VERSION "hnnbnnnynnnnnnnnnnnnnnnnnnnnnnnnnnnnnnnnnn/4/%%%/4/'%**4nnn///"

NS_ :

BS_:

BU_: BAP_Tester Fahrerdisplay_Kombi HUD ICAS1_X_Gateway ICAS3_Gateway ICC_IO_Node Kombi SmartLight_01 ZR_MIB_TOP_ab_Gen3

BO_ 851 DiETa_01: 8 ICAS1_X_Gateway
	SG_ DiETa_Car : 16|2@1+ (1,0) [0|3] ""  ICAS3_Gateway
	SG_ DiETa_Defrost_Taste : 36|2@1+ (1,0) [0|3] ""  Vector__XXX
	SG_ DiETa_FAS_Stufe : 30|2@1+ (1,0) [0|3] ""  Vector__XXX
	SG_ DiETa_FSH_Taste : 24|2@1+ (1,0) [0|3] ""  Vector__XXX
	SG_ DiETa_HSH_Taste : 26|2@1+ (1,0) [0|3] ""  Vector__XXX
	SG_ DiETa_Klima : 18|2@1+ (1,0) [0|3] ""  Vector__XXX
	SG_ DiETa_Lock_Unlock_Taste : 40|3@1+ (1,0) [0|7] ""  Vector__XXX
	SG_ DiETa_Mode : 20|2@1+ (1,0) [0|3] ""  Vector__XXX
	SG_ DiETa_Mode2 : 38|2@1+ (1,0) [0|3] ""  Vector__XXX
	SG_ DiETa_Mode_roh : 43|1@1+ (1,0) [0|1] ""  Vector__XXX
	SG_ DiETa_PAO_OFF_Status : 34|2@1+ (1,0) [0|3] ""  Vector__XXX
	SG_ DiETa_PAO_ON_Status : 32|2@1+ (1,0) [0|3] ""  Vector__XXX
	SG_ DiETa_Parken : 22|2@1+ (1,0) [0|3] ""  Vector__XXX
	SG_ DiETa_Reserve_Byte2_4 : 12|1@1+ (1,0) [0|1] ""  Vector__XXX
	SG_ DiETa_Reserve_Byte6_6 : 46|2@1+ (1,0) [0|3] ""  Vector__XXX
	SG_ DiETa_Reserve_Byte7_4 : 52|4@1+ (1,0) [0|15] ""  Vector__XXX
	SG_ DiETa_Reserve_Byte8 : 56|8@1+ (1,0) [0|255] ""  Vector__XXX
	SG_ DiETa_ResponseError : 15|1@1+ (1,0) [0|1] ""  Vector__XXX
	SG_ DiETa_Status : 13|2@1+ (1,0) [0|3] ""  Vector__XXX
	SG_ DiETa_Touch_Event : 48|4@1+ (1,0) [0|15] ""  ICAS3_Gateway
	SG_ DiETa_Warnblink_Taste : 28|2@1+ (1,0) [0|3] ""  Vector__XXX
	SG_ DiETas_01_BZ : 8|4@1+ (1,0) [0|15] ""  Vector__XXX
	SG_ DiETas_01_CRC : 0|8@1+ (1,0) [0|255] ""  Vector__XXX
	SG_ ESP_Off_Taster : 44|2@1+ (1,0) [0|3] ""  Vector__XXX

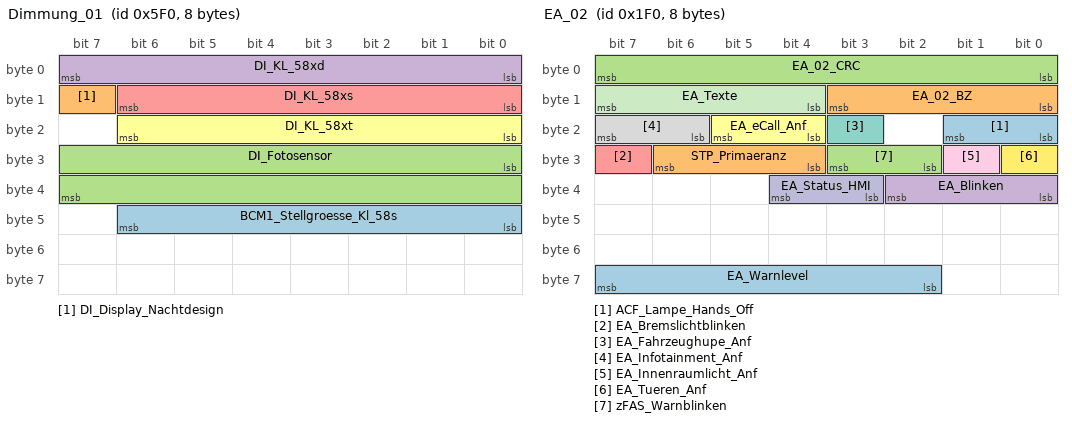
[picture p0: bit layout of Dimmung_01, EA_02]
BO_ 1520 Dimmung_01: 8 ICAS1_X_Gateway
	SG_ BCM1_Stellgroesse_Kl_58s : 40|7@1+ (1,0) [0|100] ""  HUD,ICAS3_Gateway,ICC_IO_Node,ZR_MIB_TOP_ab_Gen3
	SG_ DI_Display_Nachtdesign : 15|1@1+ (1,0) [0|1] ""  Fahrerdisplay_Kombi,HUD,ICAS3_Gateway,ICC_IO_Node,Kombi,ZR_MIB_TOP_ab_Gen3
	SG_ DI_Fotosensor : 24|16@1+ (1,0) [0|65535] ""  ICAS3_Gateway,ICC_IO_Node,ZR_MIB_TOP_ab_Gen3
	SG_ DI_KL_58xd : 0|8@1+ (1,0) [0|253] ""  Fahrerdisplay_Kombi,HUD,ICAS3_Gateway,ICC_IO_Node,Kombi,ZR_MIB_TOP_ab_Gen3
	SG_ DI_KL_58xs : 8|7@1+ (1,0) [0|100] "PerCent"  Fahrerdisplay_Kombi,HUD,ICAS3_Gateway,ICC_IO_Node,Kombi,ZR_MIB_TOP_ab_Gen3
	SG_ DI_KL_58xt : 16|7@1+ (1,0) [0|100] "PerCent"  Fahrerdisplay_Kombi,HUD,ICAS3_Gateway,ICC_IO_Node,Kombi,ZR_MIB_TOP_ab_Gen3

BO_ 2527679674 DispKBI_FS_01: 8 Fahrerdisplay_Kombi
	SG_ DispKBI_FS_Systemstatus : 12|1@1+ (1,0) [0|1] ""  ICAS1_X_Gateway

BO_ 2630879546 DispKBI_FS_DispPos_Req_FD: 64 Fahrerdisplay_Kombi
	SG_ DispKBI_FS_DispPos_Req_FD_Data : 0|512@1+ (1,0) [0|13407807929942597099574024998205846127479365820592393377723561443721764030073546976801874298166903427690031858186486050853753882811946569946433649006084096] ""  ICAS3_Gateway

BO_ 2631010618 DispKBI_FS_DispPos_Resp_FD: 64 ICAS3_Gateway
	SG_ DispKBI_FS_DispPos_Resp_FD_Data : 0|512@1+ (1,0) [0|13407807929942597099574024998205846127479365820592393377723561443721764030073546976801874298166903427690031858186486050853753882811946569946433649006084096] ""  Fahrerdisplay_Kombi

BO_ 2621717001 DispPos_DispKBI_FS_Req_FD: 64 ICAS3_Gateway
	SG_ DispPos_DispKBI_FS_Req_FD_Data : 0|512@1+ (1,0) [0|13407807929942597099574024998205846127479365820592393377723561443721764030073546976801874298166903427690031858186486050853753882811946569946433649006084096] ""  Fahrerdisplay_Kombi

BO_ 2621848073 DispPos_DispKBI_FS_Resp_FD: 64 Fahrerdisplay_Kombi
	SG_ DispPos_DispKBI_FS_Resp_FD_Data : 0|512@1+ (1,0) [0|13407807929942597099574024998205846127479365820592393377723561443721764030073546976801874298166903427690031858186486050853753882811946569946433649006084096] ""  ICAS3_Gateway

BO_ 496 EA_02: 8 ICAS1_X_Gateway
	SG_ ACF_Lampe_Hands_Off : 16|2@1+ (1,0) [0|3] ""  Vector__XXX
	SG_ EA_02_BZ : 8|4@1+ (1,0) [0|15] ""  Vector__XXX
	SG_ EA_02_CRC : 0|8@1+ (1,0) [0|255] ""  Vector__XXX
	SG_ EA_Blinken : 32|3@1+ (1,0) [0|7] ""  Vector__XXX
	SG_ EA_Bremslichtblinken : 31|1@1+ (1,0) [0|1] ""  Vector__XXX
	SG_ EA_eCall_Anf : 20|2@1+ (1,0) [0|3] ""  Kombi
	SG_ EA_Fahrzeughupe_Anf : 19|1@1+ (1,0) [0|1] ""  Vector__XXX
	SG_ EA_Infotainment_Anf : 22|2@1+ (1,0) [0|3] ""  ICAS3_Gateway,ZR_MIB_TOP_ab_Gen3
	SG_ EA_Innenraumlicht_Anf : 25|1@1+ (1,0) [0|1] ""  Vector__XXX
	SG_ EA_Status_HMI : 35|2@1+ (1,0) [0|3] ""  ICAS3_Gateway
	SG_ EA_Texte : 12|4@1+ (1,0) [0|15] ""  Kombi
	SG_ EA_Tueren_Anf : 24|1@1+ (1,0) [0|1] ""  Vector__XXX
	SG_ EA_Warnlevel : 58|6@1+ (1,0) [0|63] ""  Vector__XXX
	SG_ STP_Primaeranz : 28|3@1+ (1,0) [0|7] ""  Vector__XXX
	SG_ zFAS_Warnblinken : 26|2@1+ (1,0) [0|3] ""  Vector__XXX

BO_ 1622 ELV_01: 8 ICAS1_X_Gateway
	SG_ ELV_01_BZ : 8|4@1+ (1,0) [0|15] ""  Vector__XXX
	SG_ ELV_01_CRC : 0|8@1+ (1,0) [0|255] ""  Vector__XXX
	SG_ ELV_01_Sendestatus : 15|1@1+ (1,0) [0|1] ""  Vector__XXX
	SG_ ELV_Abbruch_Anf_Klemmenfreigabe : 23|1@1+ (1,0) [0|1] ""  Vector__XXX
	SG_ ELV_Anf_Klemme_15 : 13|1@1+ (1,0) [0|1] ""  Vector__XXX
	SG_ ELV_Anf_Klemme_50 : 14|1@1+ (1,0) [0|1] ""  Vector__XXX
	SG_ ELV_Anf_Klemme_S : 12|1@1+ (1,0) [0|1] ""  Vector__XXX
	SG_ ELV_Anlernmodus : 20|1@1+ (1,0) [0|1] ""  Vector__XXX
	SG_ ELV_Entriegelt : 17|1@1+ (1,0) [0|1] ""  Kombi
	SG_ ELV_Klemmenfreigabe : 22|1@1+ (1,0) [0|1] ""  Vector__XXX
	SG_ ELV_Lebenszustand : 19|1@1+ (1,0) [0|1] ""  Vector__XXX
	SG_ ELV_LED_Gelb : 25|1@1+ (1,0) [0|1] ""  Vector__XXX
	SG_ ELV_LED_Rot : 24|1@1+ (1,0) [0|1] ""  Kombi
	SG_ ELV_P_verriegelt : 35|1@1+ (1,0) [0|1] ""  Vector__XXX
	SG_ ELV_Txt_Bremse : 34|1@1+ (1,0) [0|1] ""  Vector__XXX
	SG_ ELV_Txt_Defekt : 30|1@1+ (1,0) [0|1] ""  Kombi
	SG_ ELV_Txt_Kupplung : 33|1@1+ (1,0) [0|1] ""  Vector__XXX
	SG_ ELV_Txt_Lkg_Bewegen : 28|1@1+ (1,0) [0|1] ""  Kombi
	SG_ ELV_Txt_P_Gang : 31|1@1+ (1,0) [0|1] ""  Vector__XXX
	SG_ ELV_Txt_Panikabschaltung : 27|1@1+ (1,0) [0|1] ""  Vector__XXX
	SG_ ELV_Txt_PN_Gang : 32|1@1+ (1,0) [0|1] ""  Vector__XXX
	SG_ ELV_Txt_Werkstatt : 29|1@1+ (1,0) [0|1] ""  Kombi
	SG_ ELV_Verriegelt : 16|1@1+ (1,0) [0|1] ""  Kombi
	SG_ ELV_ZAT_betaetigt : 18|1@1+ (1,0) [0|1] ""  Vector__XXX
	SG_ KST_Anf_ZV_Verriegelung : 37|1@1+ (1,0) [0|1] ""  Vector__XXX
	SG_ KST_aut_Abschaltung_Zuendung : 21|1@1+ (1,0) [0|1] ""  Vector__XXX
	SG_ KST_Txt_Komfortabschaltung : 36|1@1+ (1,0) [0|1] ""  Vector__XXX

BO_ 522 EML_06: 64 ICAS1_X_Gateway
	SG_ EML_06_BZ : 8|4@1+ (1,0) [0|15] ""  Vector__XXX
	SG_ EML_06_CRC : 0|8@1+ (1,0) [0|255] ""  Vector__XXX
	SG_ EML_AnzeigeGeschw : 252|10@1+ (0.32,0) [0|325.12] "KiloMeterPerHour"  Vector__XXX
	SG_ EML_BeschlX : 12|11@1+ (0.02,-20.45) [-20.45|20.45] "MeterPerSeconSquar"  Vector__XXX
	SG_ EML_BeschlXCF : 34|3@1+ (1,0) [0|7] ""  Vector__XXX
	SG_ EML_BeschlY : 23|11@1+ (0.02,-20.45) [-20.45|20.45] "MeterPerSeconSquar"  Vector__XXX
	SG_ EML_BeschlYCF : 37|3@1+ (1,0) [0|7] ""  Vector__XXX
	SG_ EML_Fahrtrichtungswahrsch : 184|8@1+ (1,-100) [-100|100] "PerCent"  Vector__XXX
	SG_ EML_Fahrwerksregeleingriff : 248|3@1+ (1,0) [0|7] ""  Vector__XXX
	SG_ EML_GeschwX : 40|12@1+ (0.0625,-128) [-128|127.8125] "MeterPerSecon"  Vector__XXX
	SG_ EML_GeschwXStdA : 52|6@1+ (0.125,0) [0|7.5] "MeterPerSecon"  Vector__XXX
	SG_ EML_GierRate : 200|16@1+ (0.000122070312,-3.9998168945) [-3.9998168945|3.999816894563] "RadiaPerSecon"  Vector__XXX
	SG_ EML_GierRateCF : 64|3@1+ (1,0) [0|7] ""  Vector__XXX
	SG_ EML_GierRateStdA : 58|6@1+ (0.0008,0) [0|0.048] "RadiaPerSecon"  Vector__XXX
	SG_ EML_Gierwinkel : 170|14@1+ (0.000383565435,-3.1415927) [-3.1415927|3.141592698925] "Radia"  Vector__XXX
	SG_ EML_GierwinkelCF : 72|2@1+ (1,0) [0|3] ""  Vector__XXX
	SG_ EML_GierwinkelStdA : 67|5@1+ (0.000976563,0) [0|0.027343764] "Radia"  Vector__XXX
	SG_ EML_Hoehe2USK : 80|7@1+ (0.002,-0.126) [-0.126|0.124] "Meter"  Vector__XXX
	SG_ EML_Hoehe2USKStdA : 76|4@1+ (0.002,0) [0|0.024] "Meter"  Vector__XXX
	SG_ EML_Hoehe_Nick_Wankwinkel2USKCF : 74|2@1+ (1,0) [0|3] ""  Vector__XXX
	SG_ EML_Kurvenkruemmung : 216|14@1+ (0.00004,-0.32) [-0.32|0.32] "MeterInver"  Vector__XXX
	SG_ EML_LenkWnklVL : 100|10@1+ (0.001953125,-1) [-1|0.994140625] "Radia"  ZR_MIB_TOP_ab_Gen3
	SG_ EML_LenkWnklVR : 110|10@1+ (0.001953125,-1) [-1|0.994140625] "Radia"  ZR_MIB_TOP_ab_Gen3
	SG_ EML_MessZeitpunkt : 87|13@1+ (0.001,0) [0|8.19] "Secon"  Vector__XXX
	SG_ EML_Nickwinkel : 262|12@1+ (0.001,-1.786) [-1.786|1.789] "Radia"  Vector__XXX
	SG_ EML_Nickwinkel2USK : 120|7@1+ (0.002,-0.126) [-0.126|0.124] "Radia"  Vector__XXX
	SG_ EML_Nickwinkel2USKStdA : 232|4@1+ (0.002,0) [0|0.024] "Radia"  Vector__XXX
	SG_ EML_Pose_Qualifier : 127|1@1+ (1,0) [0|1] ""  Vector__XXX
	SG_ EML_PositionCF : 128|2@1+ (1,0) [0|3] ""  Vector__XXX
	SG_ EML_PositionX : 130|14@1+ (0.001,-8) [-8|7.999] "Meter"  Vector__XXX
	SG_ EML_PositionXStdA : 158|6@1+ (0.01,0) [0|0.6] "Meter"  Vector__XXX
	SG_ EML_PositionY : 144|14@1+ (0.001,-8) [-8|7.999] "Meter"  Vector__XXX
	SG_ EML_PositionYStdA : 164|6@1+ (0.01,0) [0|0.6] "Meter"  Vector__XXX
	SG_ EML_QBit_Anzeigegeschw : 251|1@1+ (1,0) [0|1] ""  Vector__XXX
	SG_ EML_QBit_Fahrtrichtungswahrsch : 231|1@1+ (1,0) [0|1] ""  Vector__XXX
	SG_ EML_QBit_Kurvenkruemmung : 230|1@1+ (1,0) [0|1] ""  Vector__XXX
	SG_ EML_QBit_Nickwinkel : 274|1@1+ (1,0) [0|1] ""  Vector__XXX
	SG_ EML_QBit_Stillstandswahrsch : 247|1@1+ (1,0) [0|1] ""  Vector__XXX
	SG_ EML_Stillstandswahrsch : 240|7@1+ (1,0) [0|100] "PerCent"  Vector__XXX
	SG_ EML_Wankwinkel2USK : 192|8@1+ (0.002,-0.254) [-0.254|0.252] "Radia"  Vector__XXX
	SG_ EML_Wankwinkel2USKStdA : 236|4@1+ (0.002,0) [0|0.024] "Radia"  Vector__XXX

BO_ 608 EML_07: 8 ICAS1_X_Gateway
	SG_ EML_AnzeigeGeschw : 54|10@1+ (0.32,0) [0|325.12] "KiloMeterPerHour"  ICAS3_Gateway,Kombi
	SG_ EML_QBit_Anzeigegeschw : 53|1@1+ (1,0) [0|1] ""  Vector__XXX

BO_ 2589283970 Entfernung_02: 16 ICAS1_X_Gateway
	SG_ DIST_DKmtg_Auth : 32|32@1+ (1,0) [0|4294967293] "Meter"  ICAS3_Gateway,Kombi
	SG_ SOK_Entfernung_02_Signatur : 64|64@1+ (1,0) [0|18446744073709551616] "None"  ICAS3_Gateway,Kombi

BO_ 2331595989 Entfernung_03: 8 ICAS1_X_Gateway
	SG_ DIST_DKmtg : 32|32@1+ (1,0) [0|4294967293] "Meter"  ICAS3_Gateway,Kombi

BO_ 2589283751 Entfernungen_01: 8 ICAS1_X_Gateway
	SG_ KBI_Kilometerstand_Extended : 6|24@1+ (1,0) [0|16777213] "KiloMeter"  Vector__XXX
	SG_ KBI_Kilometerstand_HiRes_meter : 30|34@1+ (1,0) [0|17179869183] "Meter"  Kombi

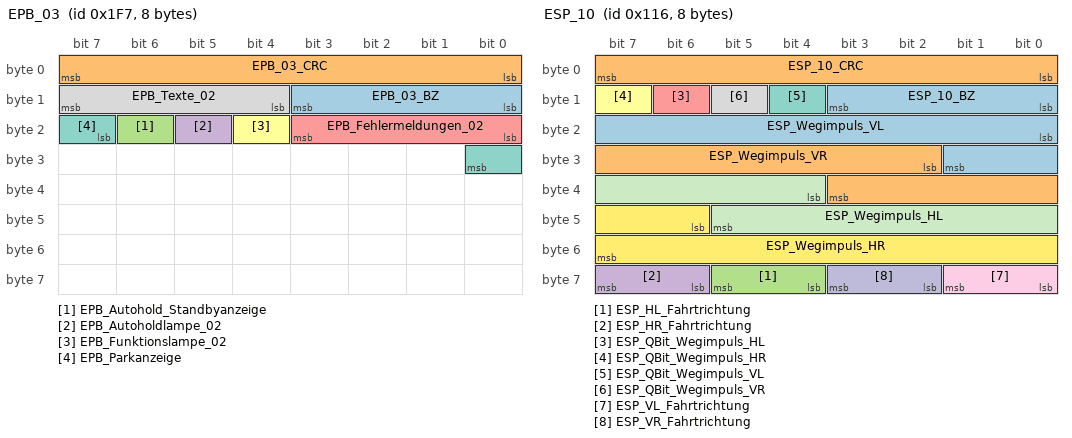
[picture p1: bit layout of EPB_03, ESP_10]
BO_ 503 EPB_03: 8 ICAS1_X_Gateway
	SG_ EPB_03_BZ : 8|4@1+ (1,0) [0|15] ""  Fahrerdisplay_Kombi,Kombi
	SG_ EPB_03_CRC : 0|8@1+ (1,0) [0|255] ""  Fahrerdisplay_Kombi,Kombi
	SG_ EPB_Autohold_Standbyanzeige : 22|1@1+ (1,0) [0|1] ""  Kombi
	SG_ EPB_Autoholdlampe_02 : 21|1@1+ (1,0) [0|1] ""  Fahrerdisplay_Kombi,Kombi
	SG_ EPB_Fehlermeldungen_02 : 16|4@1+ (1,0) [0|15] ""  Fahrerdisplay_Kombi,Kombi
	SG_ EPB_Funktionslampe_02 : 20|1@1+ (1,0) [0|1] ""  Fahrerdisplay_Kombi,Kombi
	SG_ EPB_Parkanzeige : 23|2@1+ (1,0) [0|3] ""  ICAS3_Gateway,Kombi
	SG_ EPB_Texte_02 : 12|4@1+ (1,0) [0|15] ""  Fahrerdisplay_Kombi,Kombi

BO_ 258 ESC_50: 48 ICAS1_X_Gateway
	SG_ ASR_Systemstatus : 150|2@1+ (1,0) [0|3] ""  Vector__XXX
	SG_ ECD_Bremslicht : 123|1@1+ (1,0) [0|1] ""  Vector__XXX
	SG_ ECD_Fehler : 96|1@1+ (1,0) [0|1] ""  Vector__XXX
	SG_ ECD_nicht_verfuegbar : 97|1@1+ (1,0) [0|1] ""  Vector__XXX
	SG_ EPB_DAA_Randbed_erf : 305|1@1+ (1,0) [0|1] ""  Vector__XXX
	SG_ EPB_Fehlerstatus_02 : 306|2@1+ (1,0) [0|3] ""  Vector__XXX
	SG_ EPB_Freig_Verzoeg_Anf : 271|1@1+ (1,0) [0|1] ""  Vector__XXX
	SG_ EPB_Pedalweg_Kuppl : 288|8@1+ (0.4,0) [8|92] "PerCent"  Vector__XXX
	SG_ EPB_QBit_Pedalweg_Kuppl : 269|1@1+ (1,0) [0|1] ""  Vector__XXX
	SG_ EPB_QBit_Schalterpos : 310|1@1+ (1,0) [0|1] ""  Vector__XXX
	SG_ EPB_Schalterposition : 308|2@1+ (1,0) [0|3] ""  Vector__XXX
	SG_ EPB_Spannkraft : 312|5@1+ (1,0) [0|29] "KiloNewto"  Vector__XXX
	SG_ EPB_Status : 320|2@1+ (1,0) [0|3] ""  Vector__XXX
	SG_ EPB_Status_02 : 317|3@1+ (1,0) [0|7] ""  Vector__XXX
	SG_ EPB_Verzoeg_Anf : 272|8@1+ (0.048,-7.968) [-7.968|4.224] "MeterPerSeconSquar"  Vector__XXX
	SG_ ESC_50_BZ : 8|4@1+ (1,0) [0|15] ""  Vector__XXX
	SG_ ESC_50_CRC : 0|8@1+ (1,0) [0|255] ""  Vector__XXX
	SG_ ESC_Bremsdruckgradient : 172|8@1+ (10,0) [0|2500] "BarPerSecon"  Vector__XXX
	SG_ ESC_Fahrerbremswunsch : 226|10@1+ (0.3,-30) [-30|276.6] "Bar"  Vector__XXX
	SG_ ESC_Fahrerradbremswunschmoment : 128|12@1+ (6,-2400) [-2400|22158] "NewtoMeter"  Vector__XXX
	SG_ ESC_Hydr_Fkt_aktiv : 223|2@1+ (1,0) [0|3] ""  Vector__XXX
	SG_ ESC_Motorstartverzoegerung : 34|1@1+ (1,0) [0|1] ""  Vector__XXX
	SG_ ESC_QBit_Fahrerbremswunsch : 225|1@1+ (1,0) [0|1] ""  Vector__XXX
	SG_ ESC_Raddruck_max : 248|8@1+ (1,0) [0|250] "Bar"  Vector__XXX
	SG_ ESC_SeitenwindAssistent_Eingriff : 35|1@1+ (1,0) [0|1] ""  Vector__XXX
	SG_ ESC_Unterdruckmangel_erkannt : 38|1@1+ (1,0) [0|1] ""  Vector__XXX
	SG_ ESCGeneratorSollMoment : 236|12@1+ (3,-12279) [-12279|0] ""  Vector__XXX
	SG_ ESP_Abrutschen_Stillstand : 146|1@1+ (1,0) [0|1] ""  Vector__XXX
	SG_ ESP_ANB_CM_Rueckk_Umsetz : 140|1@1+ (1,0) [0|1] ""  Vector__XXX
	SG_ ESP_Anforderung_EPB : 126|2@1+ (1,0) [0|3] ""  Vector__XXX
	SG_ ESP_Anschleppstart_Freigabe : 36|2@1+ (1,0) [0|3] ""  Vector__XXX
	SG_ ESP_Autohold_aktiv : 120|1@1+ (1,0) [0|1] ""  Vector__XXX
	SG_ ESP_Autohold_Standby : 99|1@1+ (1,0) [0|1] ""  Vector__XXX
	SG_ ESP_BKV_Unterdruck : 112|8@1+ (4,0) [4|1012] "MilliBar"  Vector__XXX
	SG_ ESP_Bremsdruck : 80|10@1+ (0.3,-30) [-30|276.6] "Bar"  ZR_MIB_TOP_ab_Gen3
	SG_ ESP_Bremsruck_AWV2 : 94|1@1+ (1,0) [0|1] ""  Vector__XXX
	SG_ ESP_Eingr_HL : 108|1@1+ (1,0) [0|1] ""  ZR_MIB_TOP_ab_Gen3
	SG_ ESP_Eingr_HR : 109|1@1+ (1,0) [0|1] ""  ZR_MIB_TOP_ab_Gen3
	SG_ ESP_Eingr_VL : 110|1@1+ (1,0) [0|1] ""  ZR_MIB_TOP_ab_Gen3
	SG_ ESP_Eingr_VR : 111|1@1+ (1,0) [0|1] ""  ZR_MIB_TOP_ab_Gen3
	SG_ ESP_Fahrer_bremst : 90|1@1+ (1,0) [0|1] ""  Vector__XXX
	SG_ ESP_Fahrer_tritt_ZBR_Schw : 147|1@1+ (1,0) [0|1] ""  Vector__XXX
	SG_ ESP_FStatus_Anfahrhilfe : 121|1@1+ (1,0) [0|1] ""  Vector__XXX
	SG_ ESP_Gierrate : 40|14@1+ (0.01,0) [0|163.82] "DegreOfArcPerSecon"  ICAS3_Gateway,ZR_MIB_TOP_ab_Gen3
	SG_ ESP_HBA_aktiv : 101|1@1+ (1,0) [0|1] ""  Vector__XXX
	SG_ ESP_HDC_aktiv : 105|1@1+ (1,0) [0|1] ""  Vector__XXX
	SG_ ESP_HDC_Standby : 100|1@1+ (1,0) [0|1] ""  Vector__XXX
	SG_ ESP_Konsistenz_ACC_Botschaft : 141|1@1+ (1,0) [0|1] ""  Vector__XXX
	SG_ ESP_Konsistenz_AWV2 : 95|1@1+ (1,0) [0|1] ""  Vector__XXX
	SG_ ESP_Konsistenz_TSK : 93|1@1+ (1,0) [0|1] ""  Vector__XXX
	SG_ ESP_Laengsbeschl : 24|10@1+ (0.03125,-16) [-16|15.90625] "MeterPerSeconSquar"  ICAS3_Gateway,Kombi,ZR_MIB_TOP_ab_Gen3
	SG_ ESP_Lenkeingriff_ADS : 92|1@1+ (1,0) [0|1] ""  Vector__XXX
	SG_ ESP_Notbremsanzeige : 55|1@1+ (1,0) [0|1] ""  Vector__XXX
	SG_ ESP_PLA_Abbruch : 57|3@1+ (1,0) [0|7] ""  Vector__XXX
	SG_ ESP_Prefill_ausgeloest : 102|1@1+ (1,0) [0|1] ""  Vector__XXX
	SG_ ESP_QBit_Bremsdruck : 76|1@1+ (1,0) [0|1] ""  Vector__XXX
	SG_ ESP_QBit_Fahrer_bremst : 77|1@1+ (1,0) [0|1] ""  Vector__XXX
	SG_ ESP_QBit_Gierrate : 12|1@1+ (1,0) [0|1] ""  ICAS3_Gateway,ZR_MIB_TOP_ab_Gen3
	SG_ ESP_QBit_Laengsbeschl : 13|1@1+ (1,0) [0|1] ""  ICAS3_Gateway,Kombi,ZR_MIB_TOP_ab_Gen3
	SG_ ESP_QBit_Querb : 14|1@1+ (1,0) [0|1] ""  ICAS3_Gateway,Kombi,ZR_MIB_TOP_ab_Gen3
	SG_ ESP_QBit_v_ref : 169|1@1+ (1,0) [0|1] ""  Vector__XXX
	SG_ ESP_Querbeschleunigung : 16|8@1+ (0.01,-1.27) [-1.27|1.27] "ForceOfGravi"  ICAS3_Gateway,Kombi,ZR_MIB_TOP_ab_Gen3
	SG_ ESP_Rueckwaertsfahrt_erkannt : 103|1@1+ (1,0) [0|1] ""  Vector__XXX
	SG_ ESP_Schwelle_Unterdruck : 78|2@1+ (1,0) [0|3] ""  Vector__XXX
	SG_ ESP_SpannungsAnf : 56|1@1+ (1,0) [0|1] ""  Vector__XXX
	SG_ ESP_StartStopp_Info : 106|2@1+ (1,0) [0|3] ""  Vector__XXX
	SG_ ESP_Status_Anfahrhilfe : 104|1@1+ (1,0) [0|1] ""  Vector__XXX
	SG_ ESP_Status_Bremsdruck : 125|1@1+ (1,0) [0|1] ""  Vector__XXX
	SG_ ESP_Status_Bremsentemp : 98|1@1+ (1,0) [0|1] ""  Vector__XXX
	SG_ ESP_Status_Bremsentemp_02 : 322|2@1+ (1,0) [0|3] ""  Vector__XXX
	SG_ ESP_Status_ESP_PLA : 60|4@1+ (1,0) [0|15] ""  Vector__XXX
	SG_ ESP_Stillstandsphase_erschoepft : 142|1@1+ (1,0) [0|1] ""  Vector__XXX
	SG_ ESP_Systemstatus_03 : 148|2@1+ (1,0) [0|3] ""  Vector__XXX
	SG_ ESP_Tuerkontakt_Fahrertuer : 144|1@1+ (1,0) [0|1] ""  Vector__XXX
	SG_ ESP_v_ref : 180|12@1+ (0.125,0) [0|511.5] "KiloMeterPerHour"  Vector__XXX
	SG_ ESP_v_ref_Fahrtrichtung : 170|2@1+ (1,0) [0|3] ""  Vector__XXX
	SG_ ESP_Verz_EPB_aktiv : 122|1@1+ (1,0) [0|1] ""  Vector__XXX
	SG_ ESP_Verz_TSK_aktiv : 91|1@1+ (1,0) [0|1] ""  Vector__XXX
	SG_ ESP_Verzoeg_EPB_verf : 124|1@1+ (1,0) [0|1] ""  Vector__XXX
	SG_ ESP_VZ_Gierrate : 54|1@1+ (1,0) [0|1] ""  ICAS3_Gateway,ZR_MIB_TOP_ab_Gen3
	SG_ ESP_ZT_Rueckk_Umsetz : 143|1@1+ (1,0) [0|1] ""  Vector__XXX
	SG_ SOK_ESC_50_Signatur : 352|32@1+ (1,0) [0|4294967295] ""  Vector__XXX

BO_ 252 ESC_51_Auth: 64 ICAS1_X_Gateway
	SG_ ESC_51_BZ : 8|4@1+ (1,0) [0|15] ""  Vector__XXX
	SG_ ESC_51_CRC : 0|8@1+ (1,0) [0|255] ""  Vector__XXX
	SG_ ESC_Achsdrehzahl_Max : 328|14@1+ (0.4,-800) [-800|5752.4] "MinutInver"  Vector__XXX
	SG_ ESC_Achsdrehzahl_Max_sek : 356|14@1+ (0.4,-800) [-800|5752.4] "MinutInver"  Vector__XXX
	SG_ ESC_Achsdrehzahl_Min : 342|14@1+ (0.4,-800) [-800|5752.4] "MinutInver"  Vector__XXX
	SG_ ESC_Achsdrehzahl_Min_sek : 370|14@1+ (0.4,-800) [-800|5752.4] "MinutInver"  Vector__XXX
	SG_ ESC_aktBR_Modus_02 : 12|2@1+ (1,0) [0|3] ""  Vector__XXX
	SG_ ESC_aktBr_Volumenstrom : 24|16@1+ (0.0078125,-252) [-252|252] "MilliLiterPerSec"  Vector__XXX
	SG_ ESC_Allrad_Anteil_max_sek : 280|9@1+ (0.2,0) [0|100] "PerCent"  Vector__XXX
	SG_ ESC_Allrad_Anteil_min_sek : 289|9@1+ (0.2,0) [0|100] "PerCent"  Vector__XXX
	SG_ ESC_Allradverteilung_aktiv : 63|1@1+ (1,0) [0|1] ""  Vector__XXX
	SG_ ESC_Anf_Mindestreku : 144|1@1+ (1,0) [0|1] ""  Kombi
	SG_ ESC_Blending_Solldruck : 14|10@1+ (0.25,0) [0|250] "Bar"  Vector__XXX
	SG_ ESC_Bremsdruck_02 : 52|10@1+ (0.3,-30) [-30|276.6] "Bar"  Vector__XXX
	SG_ ESC_Bremsdruck_Modell : 42|10@1+ (0.25,0) [0|250] "Bar"  Vector__XXX
	SG_ ESC_EBKV_Kraftblending_Modus : 40|2@1+ (1,0) [0|3] ""  Vector__XXX
	SG_ ESC_GMV_aktiv : 145|3@1+ (1,0) [0|7] ""  Vector__XXX
	SG_ ESC_GMV_nicht_verfuegbar : 148|1@1+ (1,0) [0|1] ""  Vector__XXX
	SG_ ESC_MomRad_Eingriff : 302|13@1+ (3,-12279) [-12279|12279] "None"  Vector__XXX
	SG_ ESC_MomRad_Eingriff_sek : 315|13@1+ (3,-12279) [-12279|12279] "None"  Vector__XXX
	SG_ ESC_QBit_Bremsdruck_02 : 62|1@1+ (1,0) [0|1] ""  Vector__XXX
	SG_ ESC_Status_Eingriff : 298|2@1+ (1,0) [0|3] ""  Vector__XXX
	SG_ ESC_Status_Eingriff_sek : 300|2@1+ (1,0) [0|3] ""  Vector__XXX
	SG_ ESC_Status_vRef_Stuetzeingriff : 149|1@1+ (1,0) [0|1] ""  Vector__XXX
	SG_ ESP_FDR_uebersteuern : 184|8@1+ (0.004,0) [0|1] ""  Vector__XXX
	SG_ ESP_FDR_untersteuern : 192|8@1+ (0.004,0) [0|1] ""  Vector__XXX
	SG_ ESP_FZR_uebersteuern : 128|8@1+ (0.004,0) [0|1] ""  Vector__XXX
	SG_ ESP_FZR_untersteuern : 136|8@1+ (0.004,0) [0|1] ""  Vector__XXX
	SG_ ESP_HL_Bremsmoment : 152|8@1+ (20,0) [0|5060] "NewtoMeter"  Vector__XXX
	SG_ ESP_HL_Radgeschw_02 : 64|16@1+ (0.0075,0) [0|491.49] "KiloMeterPerHour"  ZR_MIB_TOP_ab_Gen3
	SG_ ESP_HR_Bremsmoment : 160|8@1+ (20,0) [0|5060] "NewtoMeter"  Vector__XXX
	SG_ ESP_HR_Radgeschw_02 : 80|16@1+ (0.0075,0) [0|491.49] "KiloMeterPerHour"  ZR_MIB_TOP_ab_Gen3
	SG_ ESP_VL_Bremsmoment : 176|8@1+ (40,0) [0|10120] "NewtoMeter"  Vector__XXX
	SG_ ESP_VL_Radgeschw_02 : 96|16@1+ (0.0075,0) [0|491.49] "KiloMeterPerHour"  ZR_MIB_TOP_ab_Gen3
	SG_ ESP_VR_Bremsmoment : 168|8@1+ (40,0) [0|10120] "NewtoMeter"  Vector__XXX
	SG_ ESP_VR_Radgeschw_02 : 112|16@1+ (0.0075,0) [0|491.49] "KiloMeterPerHour"  ZR_MIB_TOP_ab_Gen3
	SG_ FDR_Allradverteilung_aktiv : 150|1@1+ (1,0) [0|1] ""  Vector__XXX
	SG_ FDR_Anf_Allradbetrieb : 151|1@1+ (1,0) [0|1] ""  Vector__XXX
	SG_ SOK_ESC_51_Signatur : 480|32@1+ (1,0) [0|4294967295] ""  Vector__XXX
	SG_ TSMomBegrenzung : 268|12@1+ (3,-12279) [-12279|0] ""  Vector__XXX

BO_ 885 ESC_54: 32 ICAS1_X_Gateway
	SG_ ESC_54_BZ : 8|4@1+ (1,0) [0|15] ""  ICAS3_Gateway,Kombi
	SG_ SOK_ESC_54_Signatur : 208|48@1+ (1,0) [0|281474976710655] "None"  ICAS3_Gateway,Kombi
	SG_ SSO_EdgeCount_Sum : 16|32@1+ (1,0) [0|4294967293] "None"  ICAS3_Gateway,Kombi

BO_ 278 ESP_10: 8 ICAS1_X_Gateway
	SG_ ESP_10_BZ : 8|4@1+ (1,0) [0|15] ""  ICAS3_Gateway
	SG_ ESP_10_CRC : 0|8@1+ (1,0) [0|255] ""  Vector__XXX
	SG_ ESP_HL_Fahrtrichtung : 60|2@1+ (1,0) [0|3] ""  ICAS3_Gateway,ZR_MIB_TOP_ab_Gen3
	SG_ ESP_HR_Fahrtrichtung : 62|2@1+ (1,0) [0|3] ""  ICAS3_Gateway,ZR_MIB_TOP_ab_Gen3
	SG_ ESP_QBit_Wegimpuls_HL : 14|1@1+ (1,0) [0|1] ""  ICAS3_Gateway,ZR_MIB_TOP_ab_Gen3
	SG_ ESP_QBit_Wegimpuls_HR : 15|1@1+ (1,0) [0|1] ""  ICAS3_Gateway,ZR_MIB_TOP_ab_Gen3
	SG_ ESP_QBit_Wegimpuls_VL : 12|1@1+ (1,0) [0|1] ""  ICAS3_Gateway,ZR_MIB_TOP_ab_Gen3
	SG_ ESP_QBit_Wegimpuls_VR : 13|1@1+ (1,0) [0|1] ""  ICAS3_Gateway,ZR_MIB_TOP_ab_Gen3
	SG_ ESP_VL_Fahrtrichtung : 56|2@1+ (1,0) [0|3] ""  ICAS3_Gateway,ZR_MIB_TOP_ab_Gen3
	SG_ ESP_VR_Fahrtrichtung : 58|2@1+ (1,0) [0|3] ""  ICAS3_Gateway,ZR_MIB_TOP_ab_Gen3
	SG_ ESP_Wegimpuls_HL : 36|10@1+ (1,0) [0|1000] ""  ICAS3_Gateway,ZR_MIB_TOP_ab_Gen3
	SG_ ESP_Wegimpuls_HR : 46|10@1+ (1,0) [0|1000] ""  ICAS3_Gateway,ZR_MIB_TOP_ab_Gen3
	SG_ ESP_Wegimpuls_VL : 16|10@1+ (1,0) [0|1000] ""  ICAS3_Gateway,ZR_MIB_TOP_ab_Gen3
	SG_ ESP_Wegimpuls_VR : 26|10@1+ (1,0) [0|1000] ""  ICAS3_Gateway,ZR_MIB_TOP_ab_Gen3

BO_ 1629 ESP_20: 8 ICAS1_X_Gateway
	SG_ BR_QBit_Reifenumfang : 51|1@1+ (1,0) [0|1] ""  Vector__XXX
	SG_ BR_Reifenumfang : 52|12@1+ (1,0) [0|4095] "MilliMeter"  ICAS3_Gateway
	SG_ BR_Systemart : 12|2@1+ (1,0) [0|3] ""  Vector__XXX
	SG_ ESP_20_BZ : 8|4@1+ (1,0) [0|15] ""  Vector__XXX
	SG_ ESP_20_CRC : 0|8@1+ (1,0) [0|255] ""  Vector__XXX
	SG_ ESP_Charisma_FahrPr : 24|4@1+ (1,0) [0|15] ""  Vector__XXX
	SG_ ESP_Charisma_Status : 28|2@1+ (1,0) [0|3] ""  Vector__XXX
	SG_ ESP_Dachrelingsensor : 42|2@1+ (1,0) [0|3] ""  Vector__XXX
	SG_ ESP_SpannungsAnf_02 : 14|2@1+ (1,0) [0|3] ""  Vector__XXX
	SG_ ESP_Stoppverbot_Anz_01 : 34|1@1+ (1,0) [0|1] ""  Vector__XXX
	SG_ ESP_Stoppverbot_Anz_02 : 35|1@1+ (1,0) [0|1] ""  Vector__XXX
	SG_ ESP_Stoppverbot_Anz_03 : 36|1@1+ (1,0) [0|1] ""  Vector__XXX
	SG_ ESP_Stoppverbot_Anz_04 : 37|1@1+ (1,0) [0|1] ""  Vector__XXX
	SG_ ESP_Stoppverbot_Anz_05 : 38|1@1+ (1,0) [0|1] ""  Vector__XXX
	SG_ ESP_Stoppverbot_Anz_06 : 39|1@1+ (1,0) [0|1] ""  Vector__XXX
	SG_ ESP_Stoppverbot_Anz_07 : 40|1@1+ (1,0) [0|1] ""  Vector__XXX
	SG_ ESP_Stoppverbot_Anz_08 : 44|1@1+ (1,0) [0|1] ""  Vector__XXX
	SG_ ESP_Stoppverbot_Anz_Std : 41|1@1+ (1,0) [0|1] ""  Vector__XXX
	SG_ ESP_Wiederstart_Anz_01 : 30|1@1+ (1,0) [0|1] ""  Vector__XXX
	SG_ ESP_Wiederstart_Anz_02 : 31|1@1+ (1,0) [0|1] ""  Vector__XXX
	SG_ ESP_Wiederstart_Anz_03 : 32|1@1+ (1,0) [0|1] ""  Vector__XXX
	SG_ ESP_Wiederstart_Anz_04 : 33|1@1+ (1,0) [0|1] ""  Vector__XXX
	SG_ ESP_Zaehnezahl : 16|8@1+ (1,0) [0|255] ""  ICAS3_Gateway,Kombi,ZR_MIB_TOP_ab_Gen3
	SG_ HDC_Charisma_FahrPr : 45|4@1+ (1,0) [0|15] ""  Vector__XXX
	SG_ HDC_Charisma_Status : 49|2@1+ (1,0) [0|3] ""  Vector__XXX

BO_ 253 ESP_21: 8 ICAS1_X_Gateway
	SG_ ABS_Bremsung : 56|1@1+ (1,0) [0|1] ""  Vector__XXX
	SG_ ASR_Anf : 57|1@1+ (1,0) [0|1] ""  Vector__XXX
	SG_ ASR_Schalteingriff : 51|2@1+ (1,0) [0|3] ""  Vector__XXX
	SG_ ASR_Tastung_passiv : 48|1@1+ (1,0) [0|1] ""  Vector__XXX
	SG_ BR_Eingriffsmoment : 12|10@1+ (1,-509) [-509|509] ""  Vector__XXX
	SG_ EBV_Eingriff : 59|1@1+ (1,0) [0|1] ""  Vector__XXX
	SG_ EDS_Eingriff : 60|1@1+ (1,0) [0|1] ""  Vector__XXX
	SG_ ESC_Reku_Freigabe : 24|1@1+ (1,0) [0|1] ""  Vector__XXX
	SG_ ESC_v_Signal_Qualifier_High_Low : 25|3@1+ (1,0) [0|7] ""  HUD
	SG_ ESP_21_BZ : 8|4@1+ (1,0) [0|15] ""  HUD
	SG_ ESP_21_CRC : 0|8@1+ (1,0) [0|255] ""  HUD
	SG_ ESP_Anhaltevorgang_ACC_aktiv : 63|1@1+ (1,0) [0|1] ""  Vector__XXX
	SG_ ESP_ASP : 62|1@1+ (1,0) [0|1] ""  Vector__XXX
	SG_ ESP_AWV3_Brems_aktiv : 29|1@1+ (1,0) [0|1] ""  Vector__XXX
	SG_ ESP_Diagnose : 23|1@1+ (1,0) [0|1] ""  Vector__XXX
	SG_ ESP_Eingriff : 61|1@1+ (1,0) [0|1] ""  Vector__XXX
	SG_ ESP_Haltebestaetigung : 53|1@1+ (1,0) [0|1] ""  Vector__XXX
	SG_ ESP_MKB_Abbruch_Geschw : 54|1@1+ (1,0) [0|1] ""  Vector__XXX
	SG_ ESP_PLA_Bremseingriff : 22|1@1+ (1,0) [0|1] ""  Vector__XXX
	SG_ ESP_QBit_v_Signal : 55|1@1+ (1,0) [0|1] ""  Fahrerdisplay_Kombi,HUD,ICAS3_Gateway,ICC_IO_Node,ZR_MIB_TOP_ab_Gen3
	SG_ ESP_Systemstatus : 50|1@1+ (1,0) [0|1] ""  Vector__XXX
	SG_ ESP_Tastung_passiv : 49|1@1+ (1,0) [0|1] ""  Vector__XXX
	SG_ ESP_v_Signal : 32|16@1+ (0.01,0) [0|655.32] "KiloMeterPerHour"  Fahrerdisplay_Kombi,HUD,ICAS3_Gateway,ICC_IO_Node,Kombi,SmartLight_01,ZR_MIB_TOP_ab_Gen3
	SG_ ESP_Vorsteuerung : 28|1@1+ (1,0) [0|1] ""  Vector__XXX
	SG_ MSR_Anf : 58|1@1+ (1,0) [0|1] ""  Vector__XXX
	SG_ OBD_QBit_Schlechtweg : 31|1@1+ (1,0) [0|1] ""  Vector__XXX
	SG_ OBD_Schlechtweg : 30|1@1+ (1,0) [0|1] ""  Vector__XXX

BO_ 795 ESP_24: 8 ICAS1_X_Gateway
	SG_ ABS_Lampe : 13|1@1+ (1,0) [0|1] ""  Fahrerdisplay_Kombi,Kombi
	SG_ BK_Lampe_02 : 14|2@1+ (1,0) [0|3] ""  Fahrerdisplay_Kombi,Kombi
	SG_ ESP_24_BZ : 8|4@1+ (1,0) [0|15] ""  Fahrerdisplay_Kombi,Kombi
	SG_ ESP_24_CRC : 0|8@1+ (1,0) [0|255] ""  Fahrerdisplay_Kombi,Kombi
	SG_ ESP_BKV_Warnung : 63|1@1+ (1,0) [0|1] ""  Fahrerdisplay_Kombi,Kombi
	SG_ ESP_Fehlerstatus_Wegimp : 51|1@1+ (1,0) [0|1] ""  ICAS3_Gateway,ZR_MIB_TOP_ab_Gen3
	SG_ ESP_HDC_FktLampe : 54|1@1+ (1,0) [0|1] ""  Vector__XXX
	SG_ ESP_HDC_Regelgeschw : 56|7@1+ (0.32,0) [0.32|39.68] "KiloMeterPerHour"  Vector__XXX
	SG_ ESP_Lampe : 12|1@1+ (1,0) [0|1] ""  Fahrerdisplay_Kombi,Kombi,ZR_MIB_TOP_ab_Gen3
	SG_ ESP_m_Raddrehz : 17|15@1+ (0.002,0) [0|65.278] "Hertz"  Kombi
	SG_ ESP_Meldungen : 37|3@1+ (1,0) [0|7] ""  Fahrerdisplay_Kombi,Kombi
	SG_ ESP_Off_Lampe : 55|1@1+ (1,0) [0|1] ""  Fahrerdisplay_Kombi,Kombi
	SG_ ESP_QBit_Wegimp_VA : 53|1@1+ (1,0) [0|1] ""  ICAS3_Gateway,ZR_MIB_TOP_ab_Gen3
	SG_ ESP_Textanzeigen_03 : 32|5@1+ (1,0) [0|31] ""  Kombi
	SG_ ESP_Wegimp_Ueberlauf : 52|1@1+ (1,0) [0|1] ""  ICAS3_Gateway,Kombi,ZR_MIB_TOP_ab_Gen3
	SG_ ESP_Wegimp_VA : 40|11@1+ (1,0) [0|2047] ""  ICAS3_Gateway,Kombi,ZR_MIB_TOP_ab_Gen3
	SG_ TC_Lampe : 16|1@1+ (1,0) [0|1] ""  Vector__XXX

BO_TX_BU_ 851 :ICAS1_X_Gateway;
BO_TX_BU_ 1520 :ICAS1_X_Gateway;
BO_TX_BU_ 2527679674 :Fahrerdisplay_Kombi;
BO_TX_BU_ 2630879546 :Fahrerdisplay_Kombi;
BO_TX_BU_ 2631010618 :ICAS3_Gateway;
BO_TX_BU_ 2621717001 :ICAS3_Gateway;
BO_TX_BU_ 2621848073 :Fahrerdisplay_Kombi;
BO_TX_BU_ 496 :ICAS1_X_Gateway;
BO_TX_BU_ 1622 :ICAS1_X_Gateway;
BO_TX_BU_ 522 :ICAS1_X_Gateway;
BO_TX_BU_ 608 :ICAS1_X_Gateway;
BO_TX_BU_ 2589283970 :ICAS1_X_Gateway;
BO_TX_BU_ 2331595989 :ICAS1_X_Gateway;
BO_TX_BU_ 2589283751 :ICAS1_X_Gateway;
BO_TX_BU_ 503 :ICAS1_X_Gateway;
BO_TX_BU_ 258 :ICAS1_X_Gateway;
BO_TX_BU_ 252 :ICAS1_X_Gateway;
BO_TX_BU_ 885 :ICAS1_X_Gateway;
BO_TX_BU_ 278 :ICAS1_X_Gateway;
BO_TX_BU_ 1629 :ICAS1_X_Gateway;
BO_TX_BU_ 253 :ICAS1_X_Gateway;
BO_TX_BU_ 795 :ICAS1_X_Gateway;
CM_ BO_ 1520 "ab MQB nach abgestimmten FLH Dimmung";
CM_ BO_ 1629 "neu im MQB";
CM_ SG_ 851 DiETa_Car "Status Car-Taste";
CM_ SG_ 851 DiETa_Defrost_Taste "Max. Defrost AN/AUS";
CM_ SG_ 851 DiETa_FAS_Stufe "Status FAS-Taste";
CM_ SG_ 851 DiETa_FSH_Taste "Frontscheibenheizung AN/AUS";
CM_ SG_ 851 DiETa_HSH_Taste "Heckscheibenheizung AN/AUS";
CM_ SG_ 851 DiETa_Klima "Status Klimataste";
CM_ SG_ 851 DiETa_Lock_Unlock_Taste "Lock-/Unlock-Taste";
CM_ SG_ 851 DiETa_Mode "Status Modetaste";
CM_ SG_ 851 DiETa_Mode2 "Status Mode2taste (GTE-Taster im VW380 PHEV)";
CM_ SG_ 851 DiETa_Mode_roh "Erweitertes SIgnal zur Erfï?½llung der OBD-Relevanz fï?½r die Funktion Mode auf der DiETa";
CM_ SG_ 851 DiETa_PAO_OFF_Status "Istwert fï?½r LED 'OFF' in Anzeige Passenger Airbag On/Off";
CM_ SG_ 851 DiETa_PAO_ON_Status "Istwert fï?½r LED 'ON' in Anzeige Passenger Airbag On/Off";
CM_ SG_ 851 DiETa_Parken "Status Parkentaste";
CM_ SG_ 851 DiETa_Reserve_Byte2_4 "Vorhalt, Initialisierung mit '0'";
CM_ SG_ 851 DiETa_Reserve_Byte6_6 "Vorhalt, Initialisierung mit '0'";
CM_ SG_ 851 DiETa_Reserve_Byte7_4 "Vorhalt, Initialisierung mit '0'";
CM_ SG_ 851 DiETa_Reserve_Byte8 "Vorhalt, Initialisierung mit '0'";
CM_ SG_ 851 DiETa_ResponseError "siehe LIN2.0-Specification\n(Darf nicht ï?½ber ein Fehlergueltigkeitsbit abgesichtert werden!)";
CM_ SG_ 851 DiETa_Status "Betriebszustand Direkteinstiegstasten";
CM_ SG_ 851 DiETa_Touch_Event "Touch_Events fï?½r Informationen einer Funktionsauslï?½sung auf DiETa, welches dann fï?½r bspw. ein akustisches Signal zentral umgesetzt werden kï?½nnen.";
CM_ SG_ 851 DiETa_Warnblink_Taste "Status Warnblinktaster";
CM_ SG_ 851 DiETas_01_BZ "4bit Botschaftszï?½hler, wird mit jeder Sendebotschaft inkrementiert";
CM_ SG_ 851 DiETas_01_CRC "Fï?½r MLB:\nBerechnung siehe Lastenheft 'Kommunikationsabsicherung fï?½r FlexRay und CAN'\nAb MQB und MLBevo:\nBerechnung siehe Lastenheft 'End-to-End Kommunikationsabsicherung'\n\nEndwerte siehe Begleitdokument 'S-PDU Kennungsfolgen'";
CM_ SG_ 851 ESP_Off_Taster "Das Signal beschreibt den Zustand der ESP Taste, die im MLBevo vom BCM1 eingelesen wird.\n";
CM_ SG_ 1520 BCM1_Stellgroesse_Kl_58s "Rohwert Dimmpoti";
CM_ SG_ 1520 DI_Display_Nachtdesign "Fï?½r Displays sind oft  automatische Umschaltungen von Tag-/Nachtdesign vorgesehen.\nEs gibt jedoch Zustï?½nde, an denen auch tagsï?½ber das Abblendlicht eingeschaltet ist.\nz.B. Dauerfahrlicht, Geschwindigkeitsabhï?½ngiges 'Licht-An-Bei-Autobahn', 'Regenlicht',";
CM_ SG_ 1520 DI_Fotosensor "Helligkeitswert Fotosensor\nFï?½r die Dimmung relevanter Wert zur Sensierung der Umgebungshelligkeit\nIm Detail beschrieben im 'Funktionslastenheft Dimmung MQB'.";
CM_ SG_ 1520 DI_KL_58xd "Klemme 58xd Display- und Funktionsbeleuchtung\nMit der Klemme 58xd wird die Helligkeit der Display- und der Funktionsbeleuchtungen der Schalter gesteuert.\nIm Detail beschrieben im 'Funktionslastenheft Dimmung MQB'.";
CM_ SG_ 1520 DI_KL_58xs "Suchbeleuchtung Schalter\nEIN-AUS-Schaltalgorithmus der allgemeinen Schaltersuchbeleuchtung. \nIm Detail beschrieben im 'Funktionslastenheft Dimmung MQB'.\n";
CM_ SG_ 1520 DI_KL_58xt "Timergesteuerte Suchbeleuchtung\nDer EIN-AUS-Schaltalgorithmus fï?½r die vor- und nachlaufende Schaltersuchbeleuchtungen beim Ein- & Aussteigen; z.B.: Start/Stop-Taster.\nIm Detail beschrieben im 'Funktionslastenheft Dimmung MQB'.";
CM_ SG_ 2527679674 DispKBI_FS_Systemstatus "Steuergerï?½t Defekt Eintrag im Ereignisspeicher des Steuergerï?½tes (Diagnose DTC)";
CM_ SG_ 2630879546 DispKBI_FS_DispPos_Req_FD_Data "ISO TP NA zu FID (CAN FD)\nFahrerdisplay Kombi (NA) an Funktion Display Positionierung Warnanzeigen (FID)\n- Request an Funktion";
CM_ SG_ 2631010618 DispKBI_FS_DispPos_Resp_FD_Data "ISO TP NA zu FID (CAN FD)\nFahrerdisplay Kombi (NA) an Funktion Display Positionierung Warnanzeigen (FID)\n- Response der Funktion";
CM_ SG_ 2621717001 DispPos_DispKBI_FS_Req_FD_Data "ISO TP FID zu NA (CAN FD)\nFunktion Display Positionierung Warnanzeigen (FID) an Fahrerdisplay Kombi (NA)\n- Request an Knoten";
CM_ SG_ 2621848073 DispPos_DispKBI_FS_Resp_FD_Data "ISO TP FID zu NA (CAN FD)\nFunktion Display Positionierung Warnanzeigen (FID) an Fahrerdisplay Kombi (NA)\n- Response des Knotens";
CM_ SG_ 496 ACF_Lampe_Hands_Off "Anzeige, ob der Fahrer die Hï?½nde am Lenkrad hat.";
CM_ SG_ 496 EA_02_BZ "Botschaftszï?½hler";
CM_ SG_ 496 EA_02_CRC "Fï?½r MLB:\n'Berechnung siehe Lastenheft 'Kommunikationsabsicherung fï?½r Flexray und CAN''\n\nAb MQB und MLBevo:\n'Berechnung siehe Lastenheft 'End-to-End Kommunikationsabsicherung'\n\nEndwerte siehe Begleitdokument 'S-PDU Kennungsfolge'";
CM_ SG_ 496 EA_Blinken "Emergency Assist Anforderung Blinker";
CM_ SG_ 496 EA_Bremslichtblinken "Die Funktion Emergency Alert fordert ein Blinken der Bremsleuchten an.";
CM_ SG_ 496 EA_eCall_Anf "Emergency Assist Anforderung eCall";
CM_ SG_ 496 EA_Fahrzeughupe_Anf "Emergency Assist Anforderung Fahrzeughupe";
CM_ SG_ 496 EA_Infotainment_Anf "Emergency Assist Anforderung Absenkung Infotainment-Funktionen";
CM_ SG_ 496 EA_Innenraumlicht_Anf "Anforderung Innenraumbeleuchtung durch den Emergency Assist";
CM_ SG_ 496 EA_Status_HMI "Anzeige Emergency Assist-Statusleuchte im Fahrerinformationsdisplay";
CM_ SG_ 496 EA_Texte "Anzeige der EA Texte";
CM_ SG_ 496 EA_Tueren_Anf "Emergency Assist Anforderung Tï?½ren entriegeln";
CM_ SG_ 496 EA_Warnlevel "Kritikalitï?½t der Funktion Emergency Assist";
CM_ SG_ 496 STP_Primaeranz "Primï?½ranzeige des Staupiloten";
CM_ SG_ 496 zFAS_Warnblinken "Anforderung Warnblinken durch zFAS Funktionen.";
CM_ SG_ 1622 ELV_01_BZ "4bit Botschaftszaehler, wird mit jeder Sendebotschaft inkrementiert";
CM_ SG_ 1622 ELV_01_CRC "Ab MQB und MLBevo:\n'Berechnung siehe Lastenheft 'End-to-End Kommunikationsabsicherung''\n\nEndwerte siehe Begleitdokument 'S-PDU Kennungsfolgen'";
CM_ SG_ 1622 ELV_01_Sendestatus "Zeigt an, ob die ELV fï?½r einen begrenzten Zeitraum mit verkï?½rzter Zykluszeit (50ms) sendet. Das ist bis zur KL15ein notwendig, um eine Motorstartverzï?½gerung zu vermeiden.";
CM_ SG_ 1622 ELV_Abbruch_Anf_Klemmenfreigabe "Klemmenanforderung des Kessy-SG wird von der ELV verworfen und muss vom Kessy zurï?½ckgenommen werden.";
CM_ SG_ 1622 ELV_Anf_Klemme_15 "Signal wird zur Plausibilisierung parrallel zum Klemmensignal auf dem CAN ï?½bertragen\nAnforderung Klemme_15";
CM_ SG_ 1622 ELV_Anf_Klemme_50 "Signal wird zur Plausibilisierung parrallel zum Klemmensignal auf dem CAN ï?½bertragen\nAnforderung Klemme_50";
CM_ SG_ 1622 ELV_Anf_Klemme_S "Signal wird zur Plausibilisierung parallel zum Klemmensignal auf dem CAN ï?½bertragen\nAnforderung Klemme_S";
CM_ SG_ 1622 ELV_Anlernmodus "Im Anlernmodus (1) ist zum Einschalten der KLS u.KL15 keine Authentifizierung der WFS notwendig. KL50 ist nicht einschaltbar.\nAuslieferungszustand ist (1)";
CM_ SG_ 1622 ELV_Entriegelt "ELV im Zustand entriegelt\n";
CM_ SG_ 1622 ELV_Klemmenfreigabe "Freigabe/Quittierung der ELV fï?½r das Einschalten der Klemme 15 und Klemme S";
CM_ SG_ 1622 ELV_Lebenszustand "Auslieferungszustand ist (0)\nLebenszustand";
CM_ SG_ 1622 ELV_LED_Gelb "Warnlampe Gelb";
CM_ SG_ 1622 ELV_LED_Rot "Warnlampe Rot";
CM_ SG_ 1622 ELV_P_verriegelt "Position P-verriegelt vom Gangwahlhebel";
CM_ SG_ 1622 ELV_Txt_Bremse "Text: 'Bremspedal betï?½tigen!'";
CM_ SG_ 1622 ELV_Txt_Defekt "Text: 'Lenkungsverriegelung defekt!'";
CM_ SG_ 1622 ELV_Txt_Kupplung "Text: 'Kupplungspedal betï?½tigen!'";
CM_ SG_ 1622 ELV_Txt_Lkg_Bewegen "Text: 'Lenkrad bewegen!'";
CM_ SG_ 1622 ELV_Txt_P_Gang "Text: 'Wï?½hlhebel in Position P bringen!'";
CM_ SG_ 1622 ELV_Txt_Panikabschaltung "Text: 'Notabschaltung''";
CM_ SG_ 1622 ELV_Txt_PN_Gang "Text: 'Wï?½hlhebel in Position P/N bringen!'";
CM_ SG_ 1622 ELV_Txt_Werkstatt "Text: 'Lenkungsverriegelung! Werkstatt!'";
CM_ SG_ 1622 ELV_Verriegelt "ELV im Zustand verriegelt\n";
CM_ SG_ 1622 ELV_ZAT_betaetigt "Zï?½ndanlass-Taster (ZAT) betï?½tigt";
CM_ SG_ 1622 KST_Anf_ZV_Verriegelung "Neuer Verriegelungstrigger fï?½r die ZV nach der automatischen Klemmenabschaltung.\n\nWird bei Kessyfahrzeugen mit StartStop ein aktiver Stop-Mode und Fahrerverlassen erkannt, startet ein 30 Sekunden-Timer. Innerhalb dieser 30 Sekunden hat der Fahrer die Mï?½";
CM_ SG_ 1622 KST_aut_Abschaltung_Zuendung "Falls bei eingeschalteter Zï?½ndung das Abblendlicht aktiv war, muss nach der automatischen Abschaltung der Kl_15 & Kl_S, dass Standlicht aktiv bleiben. Das Signal sendet die Information, dass eine automatische Abschaltung der Kl_15 und Kl_S erfogt.";
CM_ SG_ 1622 KST_Txt_Komfortabschaltung "Dieses Signal fordert im Kombi die Meldung an, die den Fahrer ï?½ber die ausgefï?½hrte automatische Zï?½ndungsabschaltung informiert. Signal wird fï?½r10s gesendet.";
CM_ SG_ 522 EML_06_BZ "4bit Botschaftszï?½hler, wird mit jeder Sendebotschaft inkrementiert";
CM_ SG_ 522 EML_06_CRC "Fï?½r MLB:\nBerechnung siehe Lastenheft 'Kommunikationsabsicherung fï?½r FlexRay und CAN'\nAb MQB und MLBevo:\nBerechnung siehe Lastenheft 'End-to-End Kommunikationsabsicherung'\n\nEndwerte siehe Begleitdokument 'S-PDU Kennungsfolgen'";
CM_ SG_ 522 EML_AnzeigeGeschw "Betrag des aktuellen Geschwindigkeitssignals in Fahrzeugbewegungsrichtung zur Anzeige nach Euro NCAP. Bei ASIL-Anforderungen ist die Fachabteilung zu kontaktieren.";
CM_ SG_ 522 EML_BeschlX "Beschleunigung in X-Richtung";
CM_ SG_ 522 EML_BeschlXCF "Konfidenzwert Beschleunigung X:\n0: Signal Gï?½ltig\n1: Best Guess/Ersatzwert\n2: Nicht belegt\n3: Nicht belegt\n4: Eingangsdatenfehler\n5: Nicht belegt\n6: Initwert\n7: Fehler";
CM_ SG_ 522 EML_BeschlY "Beschleunigung in Y-Richtung";
CM_ SG_ 522 EML_BeschlYCF "Konfidenzwert Beschleunigung Y:\n0: Signal Gï?½ltig\n1: Best Guess/Ersatzwert\n2: Nicht belegt\n3: Nicht belegt\n4: Eingangsdatenfehler\n5: Nicht belegt\n6: Initwert\n7: Fehler";
CM_ SG_ 522 EML_Fahrtrichtungswahrsch "Fahrtrichtungswahrscheinlichkeit in Prozent. \nBei ASIL-Anforderungen ist die Fachabteilung zu kontaktieren";
CM_ SG_ 522 EML_Fahrwerksregeleingriff "Fahrwerksregeleingriff.\nZu Hinweisen bzgl. der Berechnungsvorschrift oder bei ASIL-Anforderungen ist die Fachabteilung zu kontaktieren";
CM_ SG_ 522 EML_GeschwX "Geschwindigkeitssignal der EML in X-Richtung.";
CM_ SG_ 522 EML_GeschwXStdA "Standardabweichung EML_GeschwX (berechnet auf Basis empirischer Daten). Weiterfï?½hrende Informationen im Lastenheft spezifiziert und in der entsprechenden Fachabteilung zu erfragen.";
CM_ SG_ 522 EML_GierRate "Gierrate .";
CM_ SG_ 522 EML_GierRateCF "Konfidenzwert Gierrate:\n0: Signal Gï?½ltig\n1: Best Guess/Ersatzwert\n2: Nicht belegt\n3: Nicht belegt\n4: Eingangsdatenfehler\n5: Nicht belegt\n6: Initwert\n7: Fehler";
CM_ SG_ 522 EML_GierRateStdA "Abschï?½tzung der Standardabweichung fï?½r EML_Gierrate nach oben (berechnet auf Basis empirischer Daten). Weiterfï?½hrende Informationen im Lastenheft spezifiziert und in der entsprechenden Fachabteilung zu erfragen.";
CM_ SG_ 522 EML_Gierwinkel "Ausrichtung des USK gegenï?½ber ortsfestem Koordinatensystem um z-Achse. Definition des ortsfesten Koordinatensystems in entsprechender Fachabteilung zu erfragen. Drehrichtung im mathematisch positiven Drehsinn (rechtshï?½ndiges Koordinatensystem).";
CM_ SG_ 522 EML_GierwinkelCF "Konfidenzwert Gierwinkel\n0: gï?½ltiger Wert\n1: BestGuess/Ersatzwert\n2: Init\n3: Fehler/Fehler in den Eingangsdaten";
CM_ SG_ 522 EML_GierwinkelStdA "Standardabweichung zu EML_Gierwinkel (berechnet auf Basis empirischer Daten). Weiterfï?½hrende Informationen im Lastenheft spezifiziert und in der entsprechenden Fachabteilung zu erfragen.";
CM_ SG_ 522 EML_Hoehe2USK "Abweichung der Hï?½he der Karosserie zum USK gegenï?½ber Trimmlage";
CM_ SG_ 522 EML_Hoehe2USKStdA "Standardabweichung zu EML_Hoehe2USK (berechnet auf Basis empirischer Daten). Weiterfï?½hrende Informationen im Lastenheft spezifiziert und in der entsprechenden Fachabteilung zu erfragen.";
CM_ SG_ 522 EML_Hoehe_Nick_Wankwinkel2USKCF "Konfidenzwert Hï?½he, Nickwinkel und Wankwinkel 2USK\n0: gï?½ltiger Wert\n1: BestGuess/Ersatzwert\n2: Init\n3: Fehler/Fehler in den Eingangsdaten";
CM_ SG_ 522 EML_Kurvenkruemmung "Kurvenkrï?½mmung in 1/m bezogen auf USK. \nBei ASIL-Anforderungen ist die Fachabteilung zu kontaktieren";
CM_ SG_ 522 EML_LenkWnklVL "Radlenkwinkel Vorne Links. Freigegeben nur fï?½r Laser Scanner";
CM_ SG_ 522 EML_LenkWnklVR "Radlenkwinkel Vorne Rechts. Freigegeben nur fï?½r Laser Scanner";
CM_ SG_ 522 EML_MessZeitpunkt "Messzeitpunkt der EML Daten";
CM_ SG_ 522 EML_Nickwinkel "Nickwinkel zum Schwerevektor auf Basis HMS_Steigung.";
CM_ SG_ 522 EML_Nickwinkel2USK "Nickwinkel zum USK gegenï?½ber Trimmlage. Weiterfï?½hrende Informationen im Lastenheft spezifiziert und in der entsprechenden Fachabteilung zu erfragen.";
CM_ SG_ 522 EML_Nickwinkel2USKStdA "Standardabweichung zu EML_Nickwinkel2USK (berechnet auf Basis empirischer Daten). Weiterfï?½hrende Informationen im Lastenheft spezifiziert und in der entsprechenden Fachabteilung zu erfragen.";
CM_ SG_ 522 EML_Pose_Qualifier "Bei der Berechnung der Geschwindigkeit, Beschleuningung und Gierrate wurden nur ASIL-B abgesicherte Eingangssignale verwendet. Weiterfï?½hrende Informationen im Lastenheft spezifiziert und in der entsprechenden Fachabteilung zu erfragen.";
CM_ SG_ 522 EML_PositionCF "Konfidenzwert Position X und Y\n0: gï?½ltiger Wert\n1: BestGuess/Ersatzwert\n2: Init\n3: Fehler/Fehler in den Eingangsdaten";
CM_ SG_ 522 EML_PositionX "Position des USK gegenï?½ber ortsfestem Koordinatensystem in x-Richtung. Definition des ortsfesten Koordinatensystems in entsprechender Fachabteilung zu erfragen. Bei ï?½berlauf ist folgende Konvention zu beachten: \nPositiver ï?½berlauf: 7,999m + 0.001m = -8,0";
CM_ SG_ 522 EML_PositionXStdA "Standardabweichung zu EML_PositionX (berechnet auf Basis empirischer Daten). Weiterfï?½hrende Informationen im Lastenheft spezifiziert und in der entsprechenden Fachabteilung zu erfragen.";
CM_ SG_ 522 EML_PositionY "Position des USK gegenï?½ber ortsfestem Koordinatensystem in y-Richtung. Definition des ortsfesten Koordinatensystems in entsprechender Fachabteilung zu erfragen. Bei ï?½berlauf ist folgende Konvention zu beachten: \nPositiver ï?½berlauf: 7,999m + 0.001m = -8,0";
CM_ SG_ 522 EML_PositionYStdA "Standardabweichung zu EML_PositionY (berechnet auf Basis empirischer Daten). Weiterfï?½hrende Informationen im Lastenheft spezifiziert und in der entsprechenden Fachabteilung zu erfragen.";
CM_ SG_ 522 EML_QBit_Anzeigegeschw "QBit der Anzeigegeschwindigkeit. Gesetzt bei Ersatzwert, Init oder Fehler.";
CM_ SG_ 522 EML_QBit_Fahrtrichtungswahrsch "QBit der Fahrtrichtungswahrscheinlichkeit. Gesetzt bei Ersatzwert, Init oder Fehler";
CM_ SG_ 522 EML_QBit_Kurvenkruemmung "QBit der Kurvenkrï?½mmung. Gesetzt bei Ersatzwert, Init oder Fehler.";
CM_ SG_ 522 EML_QBit_Nickwinkel "QBit des Signals EML_Nickwinkel. Gesetzt bei Ersatzwert, Init oder Fehler.";
CM_ SG_ 522 EML_QBit_Stillstandswahrsch "QBit der Stillstandswahrscheinlichkeit. Gesetzt bei Ersatzwert, Init oder Fehler.";
CM_ SG_ 522 EML_Stillstandswahrsch "Stillstandswahrscheinlichkeit in Prozent. \nBei ASIL-Anforderungen ist die Fachabteilung zu kontaktieren";
CM_ SG_ 522 EML_Wankwinkel2USK "Wankwinkel zum USK gegenï?½ber Trimmlage. Weiterfï?½hrende Informationen im Lastenheft spezifiziert und in der entsprechenden Fachabteilung zu erfragen.";
CM_ SG_ 522 EML_Wankwinkel2USKStdA "Standardabweichung zu EML_Wankwinkel2USK (berechnet auf Basis empirischer Daten). Weiterfï?½hrende Informationen im Lastenheft spezifiziert und in der entsprechenden Fachabteilung zu erfragen.";
CM_ SG_ 608 EML_AnzeigeGeschw "Betrag des aktuellen Geschwindigkeitssignals in Fahrzeugbewegungsrichtung zur Anzeige nach Euro NCAP. Bei ASIL-Anforderungen ist die Fachabteilung zu kontaktieren.";
CM_ SG_ 608 EML_QBit_Anzeigegeschw "QBit der Anzeigegeschwindigkeit. Gesetzt bei Ersatzwert, Init oder Fehler.";
CM_ SG_ 2589283970 DIST_DKmtg_Auth "Vehicle lifetime traveled distance authentic";
CM_ SG_ 2589283970 SOK_Entfernung_02_Signatur "Signatur im Rahmen der durch SOK geschï?½tzten Broadcast-Kommunikation\n\nGeschï?½tzte Funktion: Wegstreckensicherheit\nGeschï?½tzte Signale: DIST_DKmtg_Auth";
CM_ SG_ 2331595989 DIST_DKmtg "Vehicle lifetime traveled distance";
CM_ SG_ 2589283751 KBI_Kilometerstand_Extended "Erweiterter Kilometerstand in km (ï?½ber 999.999 km)";
CM_ SG_ 2589283751 KBI_Kilometerstand_HiRes_meter "Hï?½chauflï?½senderes Signal als KBI_Kilometerstand_HiRes um Umrechnung zu vermindern und eine hï?½here Auflï?½sung als 0,1km zu erhalten.\nAuflï?½sung 1m / Bit";
CM_ SG_ 503 EPB_03_BZ "Botschaftszï?½hler";
CM_ SG_ 503 EPB_03_CRC "Fï?½r MLB:\n'Berechnung siehe Lastenheft 'Kommunikationsabsicherung fï?½r FlexRay und CAN''\n\nAb MQB und MLBevo:\n'Berechnung siehe Lastenheft 'End-to-End Kommunikationsabsicherung''\n\nEndwerte siehe Begleitdokument 'S-PDU Kennungsfolgen'\n";
CM_ SG_ 503 EPB_Autohold_Standbyanzeige "Ansteuerung der Autohold-Bereitschaftsanzeige im Kombiinstrument";
CM_ SG_ 503 EPB_Autoholdlampe_02 "Autoholdlampe im Kombi, grï?½nes P";
CM_ SG_ 503 EPB_Fehlermeldungen_02 "ï?½ber das Signal werden bestimmte Fehlertexte und -lampen im Kombi angefordert.";
CM_ SG_ 503 EPB_Funktionslampe_02 "Bit wird nur gesetzt, wenn volle Spannkraft auf beiden Seiten erreicht. Rote Lampe (rotes P) im Kombiinstrument";
CM_ SG_ 503 EPB_Parkanzeige "Signalisierung der Funktionsaktivierung der Parkbremse. Dient zur Anzeige des Schriftzug ï?½PARKï?½ im i.ID..";
CM_ SG_ 503 EPB_Texte_02 "EPB-Texte fï?½r Kombi\n9 bei Audi aktuell nicht bedient.\n10 bei Audi hinzugefï?½gt fï?½r RSe\n11 bei PAG Duo Servo Parkbremse aktuell nicht bedient \n12 bei PAG Duo Servo Parkbremse aktuell nicht bedient";
CM_ SG_ 258 ASR_Systemstatus "ASR-Systemstatus fï?½r Datenablage im EDR";
CM_ SG_ 258 ECD_Bremslicht "Bremslichtansteuerung durch ECD-Funktion";
CM_ SG_ 258 ECD_Fehler "ESP kann die Verzï?½gerungsregelung/Bremsenregelung aufgrund eines internen Fehlers nicht ausfï?½hren, mit Fehlereintrag im ESP.\n";
CM_ SG_ 258 ECD_nicht_verfuegbar "ESP kann die Verzï?½gerungsregelung/Bremsenregelung temporï?½r nicht ausfï?½hren (z.B. Netzwerkmanagement-Betriebe - KL15 Aus; v<18km/h; ESP in Diagnose, ...), ohne Fehlereintrag im ESP.\n\n";
CM_ SG_ 258 EPB_DAA_Randbed_erf "Die Randbedingungen zum automatischen ï?½ffnen der EPB (Funktion DAA) sind erfï?½llt und ein Betï?½tigen des Fahrpedals fï?½hrt zum ï?½ffnen der EPB.";
CM_ SG_ 258 EPB_Fehlerstatus_02 "Anpassung der Texte an die  aktuellen Zustï?½nde fï?½r weitergehende Funktionen (Stillstandsmanager)";
CM_ SG_ 258 EPB_Freig_Verzoeg_Anf "Verzï?½gerungsanforderung\t";
CM_ SG_ 258 EPB_Pedalweg_Kuppl "Signal entspricht Tastverhï?½ltnis des PWM. Gesamtweg Kupplungspedal 10% bis 90%, damit zu erwartende Werte 25 bis 225. 25 bei Kupplungspedal nicht getreten, 225 bei Kupplungspedal voll durchgetreten.\n2% Toleranz wird im Wertebereich ermï?½glicht (8%-92%).\n";
CM_ SG_ 258 EPB_Schalterposition "Spiegelt die Schalterstellung wieder.\n\n0x3 = Schalterfehler ";
CM_ SG_ 258 EPB_Spannkraft "Erzeugte Spannkraft. Bezieht sich auf die Aktuatoren.\n\nMQB: Spannkraftwerte entsprechen nicht den tatsï?½chlichen Spannkrï?½ften. Genauere Informationen bitte in der Fachabteilung erfragen! ";
CM_ SG_ 258 EPB_Status "Gibt den Zustand der EPB-Aktuatoren an.\n\nNur VW526/PAG E2: Wert 0x3 bedeutet 'unbekannt'\n\n";
CM_ SG_ 258 EPB_Status_02 "Erweiterung der Zustï?½nde um ein genaueres Bild des aktuellen Zustandes zu erhalten fï?½r weitergehende Funktionen ( Stillstandsmanager)\n";
CM_ SG_ 258 EPB_Verzoeg_Anf "Steuerungsanforderung an andere Systeme (z.B. ESP), um wï?½hrend der Fahrt, durch den Handbremsschalter ausgelï?½st, zu bremsen (ECD-Funktion)";
CM_ SG_ 258 ESC_50_BZ "4bit Botschaftszï?½hler, wird mit jeder Sendebotschaft inkrementiert";
CM_ SG_ 258 ESC_50_CRC "Fï?½r MLB:\nBerechnung siehe Lastenheft 'Kommunikationsabsicherung fï?½r FlexRay und CAN'\nAb MQB und MLBevo:\nBerechnung siehe Lastenheft 'End-to-End Kommunikationsabsicherung'\n\nEndwerte siehe Begleitdokument 'S-PDU Kennungsfolgen'";
CM_ SG_ 258 ESC_Bremsdruckgradient "Das Signal zeigt den vom Fahrer gedruckten Bremsdruckgradienten";
CM_ SG_ 258 ESC_Fahrerbremswunsch "PHEV: Berechneter Druck anhand des eBKV-Ausgangsstangenwegs sowie ESP-pMC. Reku nicht aktiv--> vergleichbar mit ESP_Bremsdruck; Reku aktiv --> virtueller Bremsdruck\nKonv.: entspricht ESP_Bremsdruck";
CM_ SG_ 258 ESC_Fahrerradbremswunschmoment "Berechnetes Moment anhand des eBKV-Ausgangsstangenwegs, THZ-Druck, cp-Faktoren der Bremsen und Bremspedalbetï?½tigung.\nReku nicht aktiv--> entspricht dem berechneten Moment auf Basis THZ-Druck; \nReku aktiv --> entspricht dem berechneten Moment auf Basis v";
CM_ SG_ 258 ESC_Hydr_Fkt_aktiv "Info ï?½ber die Aktivitï?½t von Druckaufbaufunktionen im ESC und Uebermittlung des Warnlevel an EBKV.";
CM_ SG_ 258 ESC_Motorstartverzoegerung "Mit dem Signal 'Motorstartverzï?½gerung' wird den aktiven Teilnehmern ermï?½glicht, einen Motorstart durch die Start-Stop-Funktion zu verzï?½gern.";
CM_ SG_ 258 ESC_QBit_Fahrerbremswunsch "Gesetzt bei Ersatzwert, Init oder Fehler.";
CM_ SG_ 258 ESC_Raddruck_max "Stellt den zahlenmï?½ï?½ig hï?½chsten Druckwert der vier modellierten Raddrï?½cke dar.";
CM_ SG_ 258 ESC_SeitenwindAssistent_Eingriff "Mit diesem Statusbit wird eine aktive Regelung durch den Seitenwindassistenten signalisiert.";
CM_ SG_ 258 ESC_Unterdruckmangel_erkannt "ESC hat einen Unterdruckmangel im Bremskraftverstï?½rker festgestellt";
CM_ SG_ 258 ESCGeneratorSollMoment "In MLBevo Faktor in TS_Faktor_Radmomente beachten!\n\nVerzï?½gernd wirkender Antriebsstrangsollmomentenanteil aus Bremspedalbetï?½tigung auf Summenradebene.";
CM_ SG_ 258 ESP_Abrutschen_Stillstand "Das ESP teilt ï?½ber dieses Bit mit, dass ein Abrutschen im Stillstand erkannt wurde.\n\nIm MQB wird das Signal nicht unterstï?½tzt!";
CM_ SG_ 258 ESP_ANB_CM_Rueckk_Umsetz "Das Signal dient als Rï?½ckmeldung zum ACC, dass eine angeforderte ANB-CM durchgefï?½hrt wird. Die positive Rï?½ckmeldung lï?½st u.a. eine entsprechende Fahrerinformation im Kombiinstrument aus";
CM_ SG_ 258 ESP_Anforderung_EPB "ESP fordert von der EPB ï?½ffnen bzw. Schliessen an. Notwendig wegen Autohold-Funktion.";
CM_ SG_ 258 ESP_Anschleppstart_Freigabe "Bilden einer Schleppstartfreigabe aus Fahrdynamiksicht. Schleppstartabbruch bei kritischer Fahrzeugstabilitï?½t";
CM_ SG_ 258 ESP_Autohold_aktiv "Rï?½ckmeldung an EPB, dass Autohold aktiv ist.";
CM_ SG_ 258 ESP_Autohold_Standby "Rï?½ckmeldung an EPB, dass der Fahrer die Funktion Autohold mindestens einmal angefordert hat. Im Fall eines ESP-Ausfalles oder einer ï?½bernahmeaufforderung erfolgt die EPB-Zuschaltung nur nach Setzen dieses Bits. Bit wird gesetzt nach Betï?½tigung des Autohol";
CM_ SG_ 258 ESP_BKV_Unterdruck "Der maximale Wert wird auf 1012 mbar begrenzt.\nDieses Signal wird im AU64x nicht unterstï?½tzt.\n\nHinweis: Auch bei nicht verbautem BKV-Unterdrucksensor kï?½nnte wï?½hrend der Initialisierung der Initialisierungswert gesendet werden.";
CM_ SG_ 258 ESP_Bremsdruck "Rohwert des Bremsdrucks\nFï?½r Fahrzeuge mit elektrischem Bremskraftverstï?½rker gilt: Aus dem Signal ESP_Bremsdruck lï?½sst sich kein Fahrerbremswunsch ableiten. Das Signal bildet lediglich den hydraulischen Anteil der Fahrzeugverzï?½gerung ab. Der Rohwert des S";
CM_ SG_ 258 ESP_Bremsruck_AWV2 "Das Signal dient als Rï?½ckmeldung zum ACC, dass ein angeforderter AWV2-Bremsruck durchgefï?½hrt wird. Die positive Rï?½ckmeldung lï?½st u.a. eine entsprechende Fahrerinformation im Kombiinstrument aus";
CM_ SG_ 258 ESP_Eingr_HL "wird von QSP und Neigungsanzeige verwendet\n\nFlag wird vom ESP gesetzt, sobald aufgrund eines ESP-Eingriffs am Rad aktiv Druck aufgebaut wird.\nFrï?½hestens mit ï?½ffnen des Ventils und spï?½testens bei einem Bremsmoment von 100Nm. Flag bleibt solange gesetzt ";
CM_ SG_ 258 ESP_Eingr_HR "wird von QSP und Neigungsanzeige verwendet\n\nFlag wird vom ESP gesetzt, sobald aufgrund eines ESP-Eingriffs am Rad aktiv Druck aufgebaut wird.\nFrï?½hestens mit ï?½ffnen des Ventils und spï?½testens bei einem Bremsmoment von 100Nm. Flag bleibt solange gesetzt ";
CM_ SG_ 258 ESP_Eingr_VL "wird von QSP und Neigungsanzeige verwendet\n\nFlag wird vom ESP gesetzt, sobald aufgrund eines ESP-Eingriffs am Rad aktiv Druck aufgebaut wird.\nFrï?½hestens mit ï?½ffnen des Ventils und spï?½testens bei einem Bremsmoment von 100Nm. Flag bleibt solange gesetzt ";
CM_ SG_ 258 ESP_Eingr_VR "wird von QSP und Neigungsanzeige verwendet\n\nFlag wird vom ESP gesetzt, sobald aufgrund eines ESP-Eingriffs am Rad aktiv Druck aufgebaut wird.\nFrï?½hestens mit ï?½ffnen des Ventils und spï?½testens bei einem Bremsmoment von 100Nm. Flag bleibt solange gesetzt ";
CM_ SG_ 258 ESP_Fahrer_bremst "Bit wird gesetzt beim ï?½berschreiten der Bremsdruckschwelle\n\nWeiterfï?½hrende Informationen im Lastenheft spezifiziert und in der entsprechenden Fachabteilung zu erfragen.\n";
CM_ SG_ 258 ESP_Fahrer_tritt_ZBR_Schw "Rï?½ckmeldung des ESP an AWV, ob der Fahrer die aktuell gï?½ltige ZBR-Schwelle ï?½bertritt";
CM_ SG_ 258 ESP_FStatus_Anfahrhilfe "Bei gesetztem Bit steht die Funktion Berganfahrassistent (Hillhold) nicht zur Verfï?½gung";
CM_ SG_ 258 ESP_Gierrate "Winkelgeschwindigkeit um die z-Achse, ESP_VZ_Gierrate & ESP_QBit_Gierrate beachten !!!\n\nMLB: gemessener Wert\ntatsï?½chliche Auflï?½sung Bosch ESP: 0,27 Grad/s\n\nAb AU64x Auflï?½sung wie die tatsï?½chliche Skalierung 0,01. Im AU64x und AU57x wird bei ESP-Absch";
CM_ SG_ 258 ESP_HBA_aktiv "Verwendung/Bedienung ab D4\nSignal gibt an, ob der hydraulische Bremsassistent im Regler aktiviert wurde\n\nIm MQB wird das Signal nicht unterstï?½tzt!\n\n";
CM_ SG_ 258 ESP_HDC_aktiv "MQB und AU57x Allroad: Mit diesem Statusbit wird eine gerade aktive Regelung des Bergabfahrassistenten (Hill Descent Control) signalisiert.";
CM_ SG_ 258 ESP_HDC_Standby "Verwendung/Bedienung im MQB und AU57x Allroad:\nFlag wird vom ESP gesetzt, wenn ï?½ber den HDC-Taster die HDC-Funktion eingeschalten wurde";
CM_ SG_ 258 ESP_Konsistenz_ACC_Botschaft "Rï?½ckmeldung zum Sender der Verzï?½gerungsanforderung ACC bezï?½glich Prï?½fung CHK/CRC, BZ und langer Timeout. Wird auch gesetzt bei einer Verzï?½gerungsanforderung grï?½ï?½er als eine applizierbare Schwelle.\n\nIm D4/C7: Botschaft ACC_05\nIm MQB: Botschaft ACC_07";
CM_ SG_ 258 ESP_Konsistenz_AWV2 "Rï?½ckmeldung zum Sender einer AWV-Anforderung (ACC-Steuergerï?½t) bezï?½glich Prï?½fung der Checksumme, des Botschaftszï?½hlers, des langen Timeout und DLC.\n";
CM_ SG_ 258 ESP_Konsistenz_TSK "Rï?½ckmeldung zum Sender einer Verzï?½gerungsanforderung (Triebstrangskoordinator) bezï?½glich Prï?½fung der Checksumme, des Botschaftszï?½hlers, des langen Timeout und DLC. Wird auch gesetzt bei Verzï?½gerungsanforderung grï?½ï?½er einer applizierbaren Schwelle.\n";
CM_ SG_ 258 ESP_Laengsbeschl "Beschleunigungswert in x-Achse\n\nMLB: Im AU64x und AU57x erfolgt die Bereitstellung der Sensorwerte durch SARA-SG! Im AU64x und AU57x wird bei ESP-Abschaltung durch modellgestï?½tzte ï?½berwachung das Signal weiterhin ausgegeben.\n\nMQB: reines ABS schickt 0";
CM_ SG_ 258 ESP_Lenkeingriff_ADS "Im Falle eines fahrzeugstabilisierenden Lenkeingriffs des ADS-Systems soll ACC/GRA deaktiviert werden.\n\nIm MQB wird dieses Signal nicht unterstï?½tzt!";
CM_ SG_ 258 ESP_Notbremsanzeige "ABS/ASR oder ESP hat Notbremssituation erkannt.\nWeiterfï?½hrende Informationen im Lastenheft spezifiziert und in der entsprechenden Fachabteilung zu erfragen.\n\n";
CM_ SG_ 258 ESP_PLA_Abbruch "Wenn der Bremseingriff abgebrochen wurde, wird in diesem Signal der Grund des Abbruchs dargestellt.\nDies ist nur gï?½ltig, wenn der Status ESP_Status_ESP_PLA = '0xA' ist.";
CM_ SG_ 258 ESP_Prefill_ausgeloest "MLB: Verwendung/Bedienung ab D4\nzeigt, ob die Funktion Prefill (aufgrund Fahrpedalgradient) ausgelï?½st wird; zeigt keinen Funktionszustand bezï?½glich Fehlerstilllegung\n\nMQB: Wird gesetzt bei jeder Art von aktivem Prefill";
CM_ SG_ 258 ESP_QBit_Bremsdruck "QBit des Bremsdrucks. Gesetzt bei Ersatzwert, Init oder Fehler.";
CM_ SG_ 258 ESP_QBit_Fahrer_bremst "Gï?½ltigkeit der Bremsdruckschwelleninformation des Signals ESP_Fahrer_bremst vom ESP SG\n0x1 = Druckschwelleninformation kann noch nicht oder aufgrund eines Fehlers nicht ausgegeben werden\n";
CM_ SG_ 258 ESP_QBit_Gierrate "QBit der Gierrate. Gesetzt bei Ersatzwert, Init oder Fehler. \n";
CM_ SG_ 258 ESP_QBit_Laengsbeschl "QBit der Lï?½ngsbeschleunigung. Gesetzt bei Ersatzwert, Init oder Fehler. \n";
CM_ SG_ 258 ESP_QBit_Querb "QBit der Querbeschleunigung. Gesetzt bei Ersatzwert, Init oder Fehler. ";
CM_ SG_ 258 ESP_QBit_v_ref "QBit der Referenzgeschwindigkeit ESP_v_ref. Gesetzt bei Ersatzwert, Init oder Fehler.\nDetailinformationen zu dem Signal sind dem Lastenheft 'Signalexport - Funktionale Anforderungen an ESP' zu entnehmen - Signal ESP_St_v_fzg_ref";
CM_ SG_ 258 ESP_Querbeschleunigung "Beschleunigungswert in y-Achse\n\nMLB: Gemessener Wert\n0xFF = Fehler (wie bereits im Wertebereich spezifizert)\nBei ESP-Abschaltung durch modellgestï?½tzte ï?½berwachung wird das Signal weiterhin ausgegeben.\nIm AU64x und AU57x erfolgt die Bereitstellung der";
CM_ SG_ 258 ESP_Rueckwaertsfahrt_erkannt "nur bei AU57x und AU416 sowie Audi B8PA\nInfo, ob Rï?½ckwï?½rtsfahrt ï?½ber internen Algorithmus sicher erkannt\n\nIm MQB wird das Signal nicht unterstï?½tzt!";
CM_ SG_ 258 ESP_Schwelle_Unterdruck "Verwendung im MQB fï?½r HBV-Projekte oder wenn fï?½r St/St ein Unterdrucksensor verbaut ist";
CM_ SG_ 258 ESP_SpannungsAnf "Die Rekuperation kann mit der Anforderung einer hï?½heren Spannung eingeschrï?½nkt werden.";
CM_ SG_ 258 ESP_StartStopp_Info "Stopp-Freigabe und Start-Anforderung an den Start-Stopp-Koordinator";
CM_ SG_ 258 ESP_Status_Anfahrhilfe "Funktionsstatus des Berganfahrassistenten\nMQB: Auswertung im Getriebe zwecks Standabkopplung";
CM_ SG_ 258 ESP_Status_Bremsdruck "MLB: Bei gesetztem Bit liegt p > ca. 2 bar an, hervorgerufen durch Fahrer, ASR, FZR, ECD, Bremsregler ... bei Abfall des Bits ist p < X bar, bei aktivem ECD-Eingriff Ende des Eingriffs \n\nWeiterfï?½hrende Informationen im Lastenheft spezifiziert und in der";
CM_ SG_ 258 ESP_Status_Bremsentemp "ECD-Bremsscheibentemperaturmodell. Rï?½ckmeldung fï?½r Sender einer ECD Verzï?½gerungsanforderung, ohne Fehlereintrag im ESP";
CM_ SG_ 258 ESP_Status_Bremsentemp_02 "Bremsscheibentemperaturmodell. Rï?½ckmeldung fï?½r Sender einer Verzï?½gerungsanforderung";
CM_ SG_ 258 ESP_Status_ESP_PLA "Zustand der Statusmaschine der Bremse fï?½r die korrespondierende Statusmaschine in dem PLA-SG";
CM_ SG_ 258 ESP_Stillstandsphase_erschoepft "Rï?½ckmeldung vom ESP, dass eine angefordertes sicheres Halten im Stillstand nicht mehr lï?½nger mï?½glich ist.";
CM_ SG_ 258 ESP_Systemstatus_03 "ESC-Status fï?½r Datenablage im EDR";
CM_ SG_ 258 ESP_Tuerkontakt_Fahrertuer "Logischer Pegel der HW-Leitung zum Tï?½rkontaktschalter im ESP-SG.\n0 > Schalter geschlossen\n1 > Schalter offen\n\nUngefilterter und unplausibilisierter Status der HW-Leitung vom Fahrertï?½r-Tï?½rkontaktschalter zum ESP.\nRedundanz fï?½r Systemsicherheit notwend";
CM_ SG_ 258 ESP_v_ref "MLBevo:\nSignal wird nur von einem BOSCH ESP System zur Verfï?½gung gestellt. Exklusives Signal vom BOSCH ESP zum BOSCH Airbag fï?½r ROSEII Funktion und fï?½r Fahrwerkregelsysteme. \nVerwendung nur nach vorheriger Abstimmung mit den verantwortlichen EF Fachbere";
CM_ SG_ 258 ESP_v_ref_Fahrtrichtung "Signal stellt die Informationen ï?½ber die Fahrtrichtung des Fahrzeuges dar. Sie wird als Vorzeichen der Referenzgeschwindigkeit ESP_v_ref interpretiert und basiert auf den Drehrichtungen der Rï?½der.\nDetailinformationen zu dem Signal sind dem Lastenheft 'Si";
CM_ SG_ 258 ESP_Verz_EPB_aktiv "Bei gesetztem Bit wird die Verzï?½gerungsanforderung von EPB umgesetzt.";
CM_ SG_ 258 ESP_Verz_TSK_aktiv "Rï?½ckmeldeinformation an den Triebsstrangkoordinator/ACC, dass die ECD-Verzï?½gerungsanforderung aktuell umgesetzt wird";
CM_ SG_ 258 ESP_Verzoeg_EPB_verf "Bei gesetztem Bit ist der Verzï?½gerungsregeler fï?½r EPB verfï?½gbar.";
CM_ SG_ 258 ESP_VZ_Gierrate "Vorzeichen der Gierrate";
CM_ SG_ 258 ESP_ZT_Rueckk_Umsetz "Das Signal dient als Rï?½ckmeldung zum ACC, dass eine angeforderte Zielbremsung/Teilbremsung durchgefï?½hrt wird. Die positive Rï?½ckmeldung lï?½st u.a. eine entsprechende Fahrerinformation im Kombiinstrument aus";
CM_ SG_ 258 SOK_ESC_50_Signatur "Signatur im Rahmen der durch SOK geschï?½tzten Broadcast-Kommunikation\nGeschï?½tzte Funktionen: Airbag-Funktionen, EML, versch. Bremsfunktionen\nGeschï?½tzte Botschaft: ESC_50";
CM_ SG_ 252 ESC_51_BZ "4bit Botschaftszï?½hler, wird mit jeder Sendebotschaft inkrementiert";
CM_ SG_ 252 ESC_51_CRC "Fï?½r MLB:\nBerechnung siehe Lastenheft 'Kommunikationsabsicherung fï?½r FlexRay und CAN'\nAb MQB und MLBevo:\nBerechnung siehe Lastenheft 'End-to-End Kommunikationsabsicherung'\n\nEndwerte siehe Begleitdokument 'S-PDU Kennungsfolgen'";
CM_ SG_ 252 ESC_Achsdrehzahl_Max "Limit Achsdrehzahl fï?½r die Primï?½rachse";
CM_ SG_ 252 ESC_Achsdrehzahl_Max_sek "Limit Achsdrehzahl fï?½r die Sekundï?½rachse";
CM_ SG_ 252 ESC_Achsdrehzahl_Min "Limit Achsdrehzahl fï?½r die Primï?½rachse";
CM_ SG_ 252 ESC_Achsdrehzahl_Min_sek "Limit Achsdrehzahl fï?½r die Sekundï?½rachse";
CM_ SG_ 252 ESC_aktBR_Modus_02 "Kontext des Signals ESC_aktBr_Modus_02:\n0: AktivBremsung per eBKV nicht aktiv\n1: ESC fordert eine schnelle Initialisierung vom eBKV beim Wecken\n2: Aktivbremsung per eBKV aktiv\n3: Aktivbremsung per eBKV aktiv ohne Begrenzung durch 'Fahrer bremst' Erken";
CM_ SG_ 252 ESC_aktBr_Volumenstrom "Volumenstromvorgabe fï?½r Aktivbremsung per eBKV,\nKontext des Volumenstroms wird im Signal ESC_aktBr_Modus ï?½bertragen";
CM_ SG_ 252 ESC_Allrad_Anteil_max_sek "Maximaler prozentualer Anteil der sekundï?½ren Antriebsachse am Gesamtmoment - wird soweit dies durch die Leistungsfï?½higkeit der Achse mï?½glich ist eingehalten";
CM_ SG_ 252 ESC_Allrad_Anteil_min_sek "Minimaler prozentualer Anteil der sekundï?½ren Antriebsachse am Gesamtmoment - wird soweit dies durch die Leistungsfï?½higkeit der Achse mï?½glich ist eingehalten";
CM_ SG_ 252 ESC_Allradverteilung_aktiv "Allradumverteilung aus BRS aktiv und vom ASG umzusetzen";
CM_ SG_ 252 ESC_Anf_Mindestreku "Bei Wert == 1 soll durch den Antrieb eine im Projekt definierte Mindestrekuperationsleistung des E-Antriebs zur Anforderung durch das Bremssystem schnellst mï?½glich frei gegeben werden. Dies dient zur Entlastung der Reibbremse.";
CM_ SG_ 252 ESC_Blending_Solldruck "Zieldruck wï?½hrend Rekuperation. Das Signal ist spezifisch aufbereitet und wird fï?½r die Pedakraftkompensation im eBKV genutzt.\n\nMQB/MQB2020: Wird nur von einem blendfï?½higen ESC unterstï?½tzt, wie es in mHEV und pHEV Fahrzeugen eingesetzt wird.";
CM_ SG_ 252 ESC_Bremsdruck_02 "Rohwert des Bremsdrucks\nFï?½r Fahrzeuge mit elektrischem Bremskraftverstï?½rker gilt: Aus dem Signal ESC_Bremsdruck_02 lï?½sst sich kein Fahrerbremswunsch ableiten. Das Signal bildet lediglich den hydraulischen Anteil der Fahrzeugverzï?½gerung ab. Der Rohwert de";
CM_ SG_ 252 ESC_Bremsdruck_Modell "Virtueller, aus dem Wert 'EBKV_Stangenweg_Fahrerwunsch' berechneter Hauptzylinderdruck. Wï?½hrend einer hydraulischen Bremsung entspricht dieser Druck nahezu dem 'ESC_Bremsdruck_02'. Wï?½hrend einer Bremsung mit Rekuperation ist es ein berechneter Wert, der d";
CM_ SG_ 252 ESC_EBKV_Kraftblending_Modus "Freigabe der Pedalkraftkompensation (Funktion des eBKV)\n\nMQB/MQB2020: Wird nur von einem blendfï?½higen ESC unterstï?½tzt, wie es in mHEV und pHEV Fahrzeugen eingesetzt wird.";
CM_ SG_ 252 ESC_GMV_aktiv "Rueckmeldung Giermomentvorgabe aktiv";
CM_ SG_ 252 ESC_GMV_nicht_verfuegbar "Rueckmeldung Giermomentvorgabe nicht verfuegbar";
CM_ SG_ 252 ESC_MomRad_Eingriff "Eingriffs-Momenten-Anforderung vom ESC an das ASG fï?½r die primï?½re Achse; auf Bezugsebene ï?½Moment am Rad; Faktor in TS_Faktor_Radmomente beachten!";
CM_ SG_ 252 ESC_MomRad_Eingriff_sek "Eingriffs-Momenten-Anforderung vom ESC an das ASG fï?½r die sekundï?½re Achse; auf Bezugsebene ï?½Moment am Rad; Faktor in TS_Faktor_Radmomente beachten! Signal ist nur relevant fï?½r mechanisch getrennte Achsantriebe (z. B. equattro)";
CM_ SG_ 252 ESC_QBit_Bremsdruck_02 "QBit des ESC_Bremsdruck_02. Gesetzt bei Ersatzwert, Init oder Fehler.";
CM_ SG_ 252 ESC_Status_Eingriff "Das Signal qualifiziert ï?½ESC_MomRad_Eingriffï?½ und gibt an, wie dieses Signal umzusetzen ist";
CM_ SG_ 252 ESC_Status_Eingriff_sek "Das Signal qualifiziert ï?½ESC_MomRad_Eingriff_sekï?½ und gibt an, wie dieses Signal umzusetzen ist";
CM_ SG_ 252 ESC_Status_vRef_Stuetzeingriff "Das Signal qualifiziert eine Momentenreduzierung an der Hinterachse zur Stï?½tzung der ESC Referenzgeschwindigkeit. Die Reduzierung erfolgt ï?½ber die Signale ESC_MomRad_Eingriff bzw ESC_MomRad_Eingriff_sek";
CM_ SG_ 252 ESP_FDR_uebersteuern "Modularer Fahrdynamikregler erkennt ï?½bersteuern.\nBei Integration modularer Fahrdynamikregler in ESC MEB: Verwendung durch eAllradfunktion in MSG.";
CM_ SG_ 252 ESP_FDR_untersteuern "Modularer Fahrdynamikregler erkennt Untersteuern.\nBei Integration modularer Fahrdynamikregler in ESC MEB: Verwendung durch eAllradfunktion in MSG.";
CM_ SG_ 252 ESP_FZR_uebersteuern "Fahrzeug erkennt uebersteuern";
CM_ SG_ 252 ESP_FZR_untersteuern "Fahrzeug erkennt untersteuern";
CM_ SG_ 252 ESP_HL_Bremsmoment "Bremsmoment HL\nAusgabe nach LAH: Ausgabe der internen Radbremsmomente / Radbremsdrï?½cke / durch das ESP";
CM_ SG_ 252 ESP_HL_Radgeschw_02 "Radgeschwindigkeit hinten links";
CM_ SG_ 252 ESP_HR_Bremsmoment "Bremsmoment HR\nAusgabe nach LAH: Ausgabe der internen Radbremsmomente / Radbremsdrï?½cke / durch das ESP";
CM_ SG_ 252 ESP_HR_Radgeschw_02 "Radgeschwindigkeit hinten rechts";
CM_ SG_ 252 ESP_VL_Bremsmoment "Bremsmoment VL\nAusgabe nach LAH: Ausgabe der internen Radbremsmomente / Radbremsdrï?½cke / durch das ESP";
CM_ SG_ 252 ESP_VL_Radgeschw_02 "Radgeschwindigkeit vorne links";
CM_ SG_ 252 ESP_VR_Bremsmoment "Bremsmoment VR\nAusgabe nach LAH: Ausgabe der internen Radbremsmomente / Radbremsdrï?½cke / durch das ESP";
CM_ SG_ 252 ESP_VR_Radgeschw_02 "Radgeschwindigkeit vorne rechts";
CM_ SG_ 252 FDR_Allradverteilung_aktiv "Allradumverteilung aus FDR aktiv und vom MSG umzusetzen";
CM_ SG_ 252 FDR_Anf_Allradbetrieb "Anforderung des Fahrdynamikreglers an MSG zur Aktivierung des Allradbetriebs.";
CM_ SG_ 252 SOK_ESC_51_Signatur "Signatur im Rahmen des SOK Authentic-Broadcast-Protokolls.\n\nGeschï?½tzte Funktion: Lenkunterstï?½tzung\nGeschï?½tzte Botschaft: ESC_51";
CM_ SG_ 252 TSMomBegrenzung "In MLBevo Faktor in TS_Faktor_Radmomente beachten!\n\nBegrenzung des verzï?½gernd wirkenden Antriebsstrangsollmomentenanteil auf Summenradebene";
CM_ SG_ 885 ESC_54_BZ "4bit Botschaftszï?½hler, wird mit jeder Sendebotschaft inkrementiert";
CM_ SG_ 885 SOK_ESC_54_Signatur "Signatur im Rahmen der durch SOK geschï?½tzten Broadcast-Kommunikation\n\nGeschï?½tzte Funktion: Wegstreckensicherheit\nGeschï?½tzte Signale: SSO_EdgeCount_Sum";
CM_ SG_ 885 SSO_EdgeCount_Sum "sum of the average of the counters of the rear wheels";
CM_ SG_ 278 ESP_10_BZ "Botschaftszï?½hler\n\nWird im Projekt D4 und D4Hybrid nicht verwendet!  Wird im D4 PA verwendet";
CM_ SG_ 278 ESP_10_CRC "Fï?½r MLB:\n'Berechnung siehe Lastenheft 'Kommunikationsabsicherung fï?½r FlexRay und CAN''\n\nAb MQB und MLBevo:\n'Berechnung siehe Lastenheft 'End-to-End Kommunikationsabsicherung''\n\nEndwerte siehe Begleitdokument 'S-PDU Kennungsfolgen'\n\nWird im Projekt";
CM_ SG_ 278 ESP_HL_Fahrtrichtung "Drehrichtung Rad HL\n\nWeiterfï?½hrende Informationen im Lastenheft spezifiziert und in der entsprechenden Fachabteilung zu erfragen.\n\nWird im Projekt D4 und D4Hybrid nicht verwendet!  Wird im D4 PA verwendet";
CM_ SG_ 278 ESP_HR_Fahrtrichtung "Drehrichtung Rad HR\n\nWeiterfï?½hrende Informationen im Lastenheft spezifiziert und in der entsprechenden Fachabteilung zu erfragen.\n\nWird im Projekt D4 und D4Hybrid nicht verwendet!  Wird im D4 PA verwendet";
CM_ SG_ 278 ESP_QBit_Wegimpuls_HL "Qualifizierungsbit Wegimpulszï?½hler HL\n\nWird im Projekt D4 und D4Hybrid nicht verwendet!  Wird im D4 PA verwendet";
CM_ SG_ 278 ESP_QBit_Wegimpuls_HR "Qualifizierungsbit Wegimpulszï?½hler HR\n\nWird im Projekt D4 und D4Hybrid nicht verwendet!  Wird im D4 PA verwendet";
CM_ SG_ 278 ESP_QBit_Wegimpuls_VL "Qualifizierungsbit Wegimpulszï?½hler VL\n\nWird im Projekt D4 und D4Hybrid nicht verwendet!  Wird im D4 PA verwendet";
CM_ SG_ 278 ESP_QBit_Wegimpuls_VR "Qualifizierungsbit Wegimpulszï?½hler VR\n\nWird im Projekt D4 und D4Hybrid nicht verwendet!  Wird im D4 PA verwendet";
CM_ SG_ 278 ESP_VL_Fahrtrichtung "Drehrichtung Rad VL\n\nWeiterfï?½hrende Informationen im Lastenheft spezifiziert und in der entsprechenden Fachabteilung zu erfragen.\n\nWird im Projekt D4 und D4Hybrid nicht verwendet!  Wird im D4 PA verwendet";
CM_ SG_ 278 ESP_VR_Fahrtrichtung "Drehrichtung Rad VR\n\nWeiterfï?½hrende Informationen im Lastenheft spezifiziert und in der entsprechenden Fachabteilung zu erfragen.\n\nWird im Projekt D4 und D4Hybrid nicht verwendet!  Wird im D4 PA verwendet";
CM_ SG_ 278 ESP_Wegimpuls_HL "Wegimpulszï?½hler HL.\nAnzahl der Wegimpulse Hinterrad links (steigende und fallende Flanke)\nZï?½hler lï?½uft grundsï?½tzlich vorwï?½rts, auch bei Rï?½ckwï?½rtsfahrt.\nNach SG-Reset ist immer, ohne Ausnahme, 1mal der Init Wert 1021 zu senden.\n\nWird im Projekt D4 und";
CM_ SG_ 278 ESP_Wegimpuls_HR "Wegimpulszï?½hler HR.\nAnzahl der Wegimpulse Hinterrad rechts (steigende und fallende Flanke)\nZï?½hler lï?½uft grundsï?½tzlich vorwï?½rts, auch bei Rï?½ckwï?½rtsfahrt.\nNach SG-Reset ist immer, ohne Ausnahme, 1mal der Init Wert 1021 zu senden.\n\nWird im Projekt D4 un";
CM_ SG_ 278 ESP_Wegimpuls_VL "Wegimpulszï?½hler VL.\nAnzahl der Wegimpulse Vorderrad links (steigende und fallende Flanke)\nZï?½hler lï?½uft grundsï?½tzlich vorwï?½rts, auch bei Rï?½ckwï?½rtsfahrt.\nNach SG-Reset ist immer, ohne Ausnahme, 1mal der Init Wert 1021 zu senden.\n\nWird im Projekt D4 und";
CM_ SG_ 278 ESP_Wegimpuls_VR "Wegimpulszï?½hler VR.\nAnzahl der Wegimpulse Vorderrad rechts (steigende und fallende Flanke)\nZï?½hler lï?½uft grundsï?½tzlich vorwï?½rts, auch bei Rï?½ckwï?½rtsfahrt.\nNach SG-Reset ist immer, ohne Ausnahme, 1mal der Init Wert 1021 zu senden.\n\nWird im Projekt D4 un";
CM_ SG_ 1629 BR_QBit_Reifenumfang "Gesetzt bei Ersatzwert, Init oder Fehler.";
CM_ SG_ 1629 BR_Reifenumfang "Mittlerer Radumfang gerechnet in Millimeter.\nVon der Bremse plausibilisierter Wert (Kopie von KBI_Reifenumfang wenn dieser plausibel) oder Ersatzwert aus Bremse wenn KBI_Reifenumfang unplausibel. Bitte das QBit beachten!\n\nIm MEB wird das Signal KBI_Rei";
CM_ SG_ 1629 BR_Systemart "Identifikation des verbauten Bremssystems\n\nDient dem Kombi zur Plausibilisierung";
CM_ SG_ 1629 ESP_20_CRC "Fï?½r MLB:\n'Berechnung siehe Lastenheft 'Kommunikationsabsicherung fï?½r FlexRay und CAN''\n\nAb MQB und MLBevo:\n'Berechnung siehe Lastenheft 'End-to-End Kommunikationsabsicherung''\n\nEndwerte siehe Begleitdokument 'S-PDU Kennungsfolgen'";
CM_ SG_ 1629 ESP_Charisma_FahrPr "MLBevo: Aktuelles Fahrprogramm des Charisma-Teilnehmers (siehe Systemlastenheft Drive Select)\nMQB: Istwert der Kennlinie (siehe Systemlastenheft MQB FPA)";
CM_ SG_ 1629 ESP_Charisma_Status "Systemstatus des Charismateilnehmers\n\nWert 0x3 ist nur fï?½r Fahrzeuge ab MQB relevant";
CM_ SG_ 1629 ESP_Dachrelingsensor "Erkennung auf Verbau des Dachrelingsensors und Dachquertrï?½ger.";
CM_ SG_ 1629 ESP_SpannungsAnf_02 "Forderung des ESP-SG's zur Spannungsanhebung.";
CM_ SG_ 1629 ESP_Stoppverbot_Anz_01 "Dieses Signal gibt die detaillierte Begrï?½ndung fï?½r ein Stoppverbot vom Bremsensteuergerï?½t an.";
CM_ SG_ 1629 ESP_Stoppverbot_Anz_02 "Dieses Signal gibt die detaillierte Begrï?½ndung fï?½r ein Stoppverbot vom Bremsensteuergerï?½t an.";
CM_ SG_ 1629 ESP_Stoppverbot_Anz_03 "Dieses Signal gibt die detaillierte Begrï?½ndung fï?½r ein Stoppverbot vom Bremsensteuergerï?½t an.";
CM_ SG_ 1629 ESP_Stoppverbot_Anz_04 "Dieses Signal gibt die detaillierte Begrï?½ndung fï?½r ein Stoppverbot vom Bremsensteuergerï?½t an.";
CM_ SG_ 1629 ESP_Stoppverbot_Anz_05 "Dieses Signal gibt die detaillierte Begrï?½ndung fï?½r ein Stoppverbot vom Bremsensteuergerï?½t an.";
CM_ SG_ 1629 ESP_Stoppverbot_Anz_06 "Dieses Signal gibt die detaillierte Begrï?½ndung fï?½r ein Stoppverbot vom Bremsensteuergerï?½t an.";
CM_ SG_ 1629 ESP_Stoppverbot_Anz_07 "Dieses Signal gibt die detaillierte Begrï?½ndung fï?½r ein Stoppverbot vom Bremsensteuergerï?½t an.";
CM_ SG_ 1629 ESP_Stoppverbot_Anz_08 "Dieses Signal gibt die detaillierte Begrï?½ndung fï?½r ein Stoppverbot vom Bremsensteuergerï?½t an.";
CM_ SG_ 1629 ESP_Stoppverbot_Anz_Std "Dieses Signal gibt die detaillierte Begrï?½ndung fï?½r ein Stoppverbot vom Bremsensteuergerï?½t an.";
CM_ SG_ 1629 ESP_Wiederstart_Anz_01 "Dieses Signal gibt die detaillierte Begrï?½ndung fï?½r einen Wiederstart vom Bremsensteuergerï?½t an. ";
CM_ SG_ 1629 ESP_Wiederstart_Anz_02 "Dieses Signal gibt die detaillierte Begrï?½ndung fï?½r einen Wiederstart vom Bremsensteuergerï?½t an. ";
CM_ SG_ 1629 ESP_Wiederstart_Anz_03 "Dieses Signal gibt die detaillierte Begrï?½ndung fï?½r einen Wiederstart vom Bremsensteuergerï?½t an. ";
CM_ SG_ 1629 ESP_Wiederstart_Anz_04 "Dieses Signal gibt die detaillierte Begrï?½ndung fï?½r einen Wiederstart vom Bremsensteuergerï?½t an.";
CM_ SG_ 1629 ESP_Zaehnezahl "Konstanter Wert der Zï?½hnezahl des verwendeten Impulsrades wird ausgegeben, jeder Empfï?½nger der Wegimpulse muss die Zï?½hnezahl einlesen, um eine volle Umdrehung des Rades zu erkennen. \n\nWeiterfï?½hrende Informationen im Lastenheft spezifiziert und in der en";
CM_ SG_ 1629 HDC_Charisma_FahrPr "MLBevo: Aktuelles Fahrprogramm des Charisma-Teilnehmers (siehe Systemlastenheft Drive Select)\nMQB: Istwert der Kennlinie (siehe Systemlastenheft MQB FPA)";
CM_ SG_ 1629 HDC_Charisma_Status "Systemstatus des Charismateilnehmers\n\nWert 0x3 ist nur fï?½r Fahrzeuge ab MQB relevant";
CM_ SG_ 253 ABS_Bremsung "Antiblockiersystem, Bit zeigt auch Druckabbau an (z.B. ESP hat zuviel Druck aufgebaut oder ungebremste Regelung auf Bahnï?½bergang)\nWeiterfï?½hrende Informationen im Lastenheft spezifiziert und in der entsprechenden Fachabteilung zu erfragen.";
CM_ SG_ 253 ASR_Anf "MLB: Die Momentenanforderung 'ASR_MSR_Moment_schnell' und 'ASR_Moment_langsam' sind auszufï?½hren\nMQB: Die Momentenanforderung 'BR_Eingriffsmoment' ist auszufï?½hren";
CM_ SG_ 253 ASR_Schalteingriff "Wunsch an das Getriebe wï?½hrend einer ASR Regelung\n\nMLB: Es wird nur 0x0 und 0x1 genutzt\n\n";
CM_ SG_ 253 ASR_Tastung_passiv "ASR deaktiviert oder Schwellen geï?½ndert (projektabhï?½ngig)\nWeiterfï?½hrende Informationen im Lastenheft spezifiziert und in der entsprechenden Fachabteilung zu erfragen.\n";
CM_ SG_ 253 BR_Eingriffsmoment "Einheitenloser Wert! Faktor in MO_Faktor_Momente_02 in Motor_Code_01 beachten!\nSchnelle reduzierende (ASR) oder erhï?½hende (MSR) Momentanforderung an den Motor.";
CM_ SG_ 253 EBV_Eingriff "Elektronische Bremskraftverteilung, aktueller Eingriff (Druckhalten, Druckabbau)\n\nIm MLB: kein ABS / ESP-Eingriff ???";
CM_ SG_ 253 EDS_Eingriff "Elektronische Differentialsperre";
CM_ SG_ 253 ESC_Reku_Freigabe "Mit diesem Bit wird die Rekuperation im Motorsteuergerï?½t erlaubt. Bei Ausfall ESC wird Rekuperation nicht freigegeben.\n\nMQB/MQB2020: Wird nur von einem blendfï?½higen ESC unterstï?½tzt, wie es in mHEV und pHEV Fahrzeugen eingesetzt wird.";
CM_ SG_ 253 ESC_v_Signal_Qualifier_High_Low "Das Qualifizerungssignal ESC_v_Signal_Qualifier_High_Low gibt eine Information ï?½ber die Gï?½te der vom Bremsregelsystem ausgegebenen Geschwindigkeitsinformation 'mittlere Geschwindigkeit', wobei Vertrauensbereiche fï?½r das ausgegebene Geschwindigkeitssignal ";
CM_ SG_ 253 ESP_21_CRC "Fï?½r MLB:\n'Berechnung siehe Lastenheft 'Kommunikationsabsicherung fï?½r FlexRay und CAN''\n\nAb MQB und MLBevo:\n'Berechnung siehe Lastenheft 'End-to-End Kommunikationsabsicherung''\n\nEndwerte siehe Begleitdokument 'S-PDU Kennungsfolgen'";
CM_ SG_ 253 ESP_Anhaltevorgang_ACC_aktiv "Zeigt an, ob ACC-Anhaltevorgang aktiv";
CM_ SG_ 253 ESP_ASP "MLB: Anhaenger-Stabilisierungs-Programm\nMQB: Gespannstabilisierung";
CM_ SG_ 253 ESP_AWV3_Brems_aktiv "Teil-, Ziel- oder Notbremsung wird im ESP fï?½r AWV3 umgesetzt (das MSG nutzt diese Info fï?½r den Abwurf der GRA-Regelung).";
CM_ SG_ 253 ESP_Diagnose "MLB: Nach Diagnoseende wird ein SW-Reset ausgelï?½st welcher einen Kommunikatiosausfall fï?½r max. 150ms verursacht. Dies ist bei SG mit verschï?½rfter Timeoutï?½berwachung (nicht nach Konzern-LH) zu beachten.\n\nMQB: Weiterfï?½hrende Informationen im Lastenheft sp";
CM_ SG_ 253 ESP_Eingriff "Eingriff des Fahrdynamikreglers";
CM_ SG_ 253 ESP_Haltebestaetigung "Rï?½ckmeldung vom ESP-SG, dass das Fahrzeug aufgrund einer externen Bremsanforderung (z. B. ACC, PLA, ANB, o. ï?½.) abgebremst wurde und im Stillstand gehalten wird.";
CM_ SG_ 253 ESP_MKB_Abbruch_Geschw "Im Falle einer Multikollisionsbremsung teilt das ESP den Abbruch der MKB aufgrund der unteren Geschwindigkeitsschwelle mit.";
CM_ SG_ 253 ESP_PLA_Bremseingriff "Signalisierung des aktiven Bremseingriffes des ESP aufgrund einer Bremsanforderung vom PLA.";
CM_ SG_ 253 ESP_QBit_v_Signal "Geschwindigkeit wird vom ABS/ASR oder ESP aus Ersatzwerten errechnet, wenn Bit gesetzt ist. Gï?½te des Signals ist verï?½ndert.";
CM_ SG_ 253 ESP_Systemstatus "Fehler steht fï?½r Stillegung ESP mit Fehlereintrag.\n\nMLB: Flag wird bei Unterspannung im Stand bis einmalig 6km/h (AU48x) oder 10 km/h (AU641, AU57x) ï?½berschritten nicht gesetzt (Ausblendung Startvorgang)\nIm AU64x, AU57x gilt ESP D4 Funktionsanforderung";
CM_ SG_ 253 ESP_Tastung_passiv "ESP deaktiviert oder Schwellen geï?½ndert (projektabhï?½ngig)\nWeiterfï?½hrende Informationen im Lastenheft spezifiziert und in der entsprechenden Fachabteilung zu erfragen.";
CM_ SG_ 253 ESP_v_Signal "Geschwindigkeitssignal vom ABS/ASR oder ESP. Mittelwert der angetriebenen Rï?½der.\nBei MSR oder ABS Eingriffen wird die ABS-Referenzgeschwindigkeit fï?½r >= 200ms eingespiegelt (Zeit wird mit Aktiv-Flanke der Funktionsbits getriggert)\n\nMQB: Bei Frontantrie";
CM_ SG_ 253 ESP_Vorsteuerung "zur Unterscheidung zwischen ESP-Vorsteuermaï?½nahmen und ESP-Regeleingriffen";
CM_ SG_ 253 MSR_Anf "MLB: Die Momentenanforderung 'ASR_MSR_Moment_schnell' ist auszufï?½hren.\nMQB: Die Momentenanforderung 'BR_Eingriffsmoment' ist auszufï?½hren";
CM_ SG_ 253 OBD_Schlechtweg "Fï?½r Ausblendung der Zï?½ndaussetzererkennung im Motorsteuergerï?½t (Otto). Bit wird gesetzt, wenn Rad-Drehbeschleunigung im ESP > Grenzwert ist. Vorteil gegenï?½ber Radgeschwindigkeiten, dass ESP alle 2 ms dynamisch die Rad-Drehbeschleunigung errechnet und dem ";
CM_ SG_ 795 ABS_Lampe "Sicherheitswarnlampe\n\nWeiterfï?½hrende Informationen im Lastenheft spezifiziert und in der entsprechenden Fachabteilung zu erfragen.";
CM_ SG_ 795 BK_Lampe_02 "Typ1_ein_statisch signalisiert EBV-Ausfall\nMQB: wird auch bei HBV-Ausfall verwendet.\n\nTyp1_ein_statisch: wird bei AUDI fï?½r Aktivierung der roten BKL ohne Text und Akustik verwendet (z.B. Lampenaufprï?½fung).\nTyp2_ein_statisch: signalisiert elektrischen ";
CM_ SG_ 795 ESP_24_CRC "Fï?½r MLB:\n'Berechnung siehe Lastenheft 'Kommunikationsabsicherung fï?½r FlexRay und CAN''\n\nAb MQB und MLBevo:\n'Berechnung siehe Lastenheft 'End-to-End Kommunikationsabsicherung''\n\nEndwerte siehe Begleitdokument 'S-PDU Kennungsfolgen'";
CM_ SG_ 795 ESP_BKV_Warnung "ESP sendet im Hinweis- /Stï?½rungsfall an das Kombi Informationen zum Anzeigen (Text + Akustik)\n\nIm MQB wird dieses Signal nicht unterstï?½tzt!\n";
CM_ SG_ 795 ESP_Fehlerstatus_Wegimp "Weiterfï?½hrende Informationen im Lastenheft spezifiziert und in der entsprechenden Fachabteilung zu erfragen.\n\nMLB: Fehler wird gesetzt, wenn beide ESP-Drehzahlfï?½hler an der Vorderachse defekt sind.\n\nMQB: Fehler wird gesetzt, wenn beide Raddrehzahlfï?½hl";
CM_ SG_ 795 ESP_HDC_FktLampe "Funktionslampe Bergabfahrassistent.\n(Sender blinkt mit dem Bit 3,3Hz)";
CM_ SG_ 795 ESP_HDC_Regelgeschw "Verwendung/Bedienung nur im AU57x Allroad:\nHDC-Geschwindigkeit\nDient der Anzeige der HDC-Geschwindigkeit und eines Bergabfahrsymbols im Kombi.\nHDC-Standby wird gesetzt sobald der Fahrer den HDC-Taster aktiviert hat.\nBei HDC-Off oder wï?½hrend der Initia";
CM_ SG_ 795 ESP_Lampe "Zustand der Fahrdynamikregelungslampe (MLB: ASR und/oder ESP, MQB: nur ESP)\n\nWeiterfï?½hrende Informationen im Lastenheft spezifiziert und in der entsprechenden Fachabteilung zu erfragen.";
CM_ SG_ 795 ESP_m_Raddrehz "Radumdrehungen pro Sekunde sind Eingangsgrï?½ï?½e fï?½r die Geschwindigkeitsberechnung im Kombi. Aus dieser Raddrehzahl und dem Radumfang wird die Fahrzeuggeschwindigkeit errechnet.\n\nMLB: Exklusiver Empfï?½nger ist das Kombiinstrument!\nMQB: Bei Frontantrieb un";
CM_ SG_ 795 ESP_Meldungen "ESP sendet im Hinweis- /Stï?½rungsfall an das Kombi Informationen zum Anzeigen\n\nWeiterfï?½hrende Informationen im Lastenheft spezifiziert und in der entsprechenden Fachabteilung zu erfragen.\nErgï?½nzender Hinweis:\n1 = Autohold_Hinweis_1 (Anfahrassistent: nu";
CM_ SG_ 795 ESP_Off_Lampe "Bit zur Ansteuerung der separaten ESP-off-Lampe im Kombi (Gesetzesforderung USA)\n\nMLB:\nVerwendung/Bedienung ab D4";
CM_ SG_ 795 ESP_QBit_Wegimp_VA "Gesetzt bei Ersatzwert, Init oder Fehler.";
CM_ SG_ 795 ESP_Textanzeigen_03 "Textanzeigen der Fahrdynamikregelung im Kombiinstrument\n\nWeiterfï?½hrende Informationen im Lastenheft spezifiziert und in der entsprechenden Fachabteilung zu erfragen.\n\nDer Signalwert 24 wird nur im BY736 verwendet.";
CM_ SG_ 795 ESP_Wegimp_Ueberlauf "Der Wegimpulszï?½hler ist pro Zï?½ndungslauf mindestens einmal ï?½bergelaufen\n\nWeiterfï?½hrende Informationen im Lastenheft spezifiziert und in der entsprechenden Fachabteilung zu erfragen.";
CM_ SG_ 795 ESP_Wegimp_VA "Weiterfï?½hrende Informationen im Lastenheft spezifiziert und in der entsprechenden Fachabteilung zu erfragen.\n\nMLB: Die Wegimpulse Vorderachse sind die gemittelten Werte (reine mathematische Operation: Addition und Division durch zwei, keine Filterung) d";
CM_ SG_ 795 TC_Lampe "M-ABS Lampe (separate Lampe fï?½r M-ABS-Systeme Markt Brasilien)\n\nWeiterfï?½hrende Informationen im Lastenheft spezifiziert und in der entsprechenden Fachabteilung zu erfragen.";
BA_DEF_ BO_ "CANFD_BRS" ENUM "0", "1";
BA_DEF_ BO_ "DiagRequest" ENUM "No", "Yes";
BA_DEF_ BO_ "DiagResponse" ENUM "No", "Yes";
BA_DEF_ BO_ "DiagState" ENUM "No", "Yes";
BA_DEF_ BO_ "GenMsgChkConstant" HEX 0 4095;
BA_DEF_ BO_ "GenMsgCycleTime" INT 0 65535;
BA_DEF_ BO_ "GenMsgCycleTimeFast" INT 0 65535;
BA_DEF_ BO_ "GenMsgDelayTime" INT 0 100000;
BA_DEF_ BO_ "GenMsgILSupport" ENUM "No", "Yes";
BA_DEF_ BO_ "GenMsgNrOfRepetition" INT 0 100;
BA_DEF_ BO_ "GenMsgPDUConstants" STRING;
BA_DEF_ BO_ "GenMsgSendType" ENUM "Cyclic", "not_used", "not_used", "not_used", "not_used", "not_used", "not_used", "IfActive", "NoMsgSendType";
BA_DEF_ BO_ "GenMsgStartDelayTime" INT 0 100000;
BA_DEF_ BO_ "MsgType" ENUM "Application", "NM ", "NMH", "TP2.0", "ISO-TP ", "BAP", "EID", "KS", "XCP_PRE_CONFIGURED", "XCP_RUNTIME_CONFIGURED";
BA_DEF_ BO_ "NmMessage" ENUM "No", "Yes";
BA_DEF_ BO_ "NmhMessage" ENUM "No", "Yes";
BA_DEF_ BO_ "VAGTP20_API" HEX 0 255;
BA_DEF_ BO_ "VAGTP20_DynConnection" ENUM "No", "Yes";
BA_DEF_ BO_ "VAGTP20_DynSetup" ENUM "No", "Yes";
BA_DEF_ BO_ "VAGTP20_StatConnection" ENUM "No", "Yes";
BA_DEF_ BO_ "VFrameFormat" ENUM "StandardCAN", "ExtendedCAN", "reserved", "reserved", "reserved", "reserved", "reserved", "reserved", "reserved", "reserved", "reserved", "reserved", "reserved", "reserved", "StandardCAN_FD", "ExtendedCAN_FD";
BA_DEF_ SG_ "Fehlerwert" HEX 0 2147483647;
BA_DEF_ SG_ "GenSigActiveRepetitions" INT -2147483648 2147483647;
BA_DEF_ SG_ "GenSigFuncType" ENUM "NoFunction", "MsgCounter", "CRC-8", "XOR", "XOR-2", "DatedBit", "SW-Kl15", "CHK", "Constant", "Protocol", "CRC-8-SAE_J1850", "CRC-32", "DataLength", "DataID", "MsgCounter16", "SOK-Signatur", "Cluster";
BA_DEF_ SG_ "GenSigInactiveValue" INT -2147483648 2147483647;
BA_DEF_ SG_ "GenSigMissingSourceValue" HEX 0 2147483647;
BA_DEF_ SG_ "GenSigSendType" ENUM "Cyclic", "OnWrite", "OnWriteWithRepetition", "OnChange", "OnChangeWithRepetition", "IfActive", "IfActiveWithRepetition", "NoSigSendType", "OnChangeAndIfActive", "OnChangeAndIfActiveWithRepetition";
BA_DEF_ SG_ "GenSigStartValue" INT -2147483648 2147483647;
BA_DEF_ SG_ "GenSigSwitchedByIgnition" ENUM "No", "Yes";
BA_DEF_ SG_ "NWM-WakeupAllowed" ENUM "No", "Yes";

BA_DEF_REL_ BU_SG_REL_ "GenSigTimeoutTime" INT 0 65535;
BA_DEF_DEF_ "CANFD_BRS" "1";
BA_DEF_DEF_ "DiagRequest" "No";
BA_DEF_DEF_ "DiagResponse" "No";
BA_DEF_DEF_ "DiagState" "No";
BA_DEF_DEF_ "Fehlerwert" 0;
BA_DEF_DEF_ "GenMsgChkConstant" 0;
BA_DEF_DEF_ "GenMsgCycleTime" 0;
BA_DEF_DEF_ "GenMsgCycleTimeFast" 0;
BA_DEF_DEF_ "GenMsgDelayTime" 0;
BA_DEF_DEF_ "GenMsgILSupport" "No";
BA_DEF_DEF_ "GenMsgNrOfRepetition" 0;
BA_DEF_DEF_ "GenMsgPDUConstants" "";
BA_DEF_DEF_ "GenMsgSendType" "NoMsgSendType";
BA_DEF_DEF_ "GenMsgStartDelayTime" 0;
BA_DEF_DEF_ "GenSigActiveRepetitions" 0;
BA_DEF_DEF_ "GenSigFuncType" "NoFunction";
BA_DEF_DEF_ "GenSigInactiveValue" 0;
BA_DEF_DEF_ "GenSigMissingSourceValue" 0;
BA_DEF_DEF_ "GenSigSendType" "NoSigSendType";
BA_DEF_DEF_ "GenSigStartValue" 0;
BA_DEF_DEF_ "GenSigSwitchedByIgnition" "Yes";
BA_DEF_DEF_ "MsgType" "Application";
BA_DEF_DEF_ "NWM-WakeupAllowed" "No";
BA_DEF_DEF_ "NmMessage" "No";
BA_DEF_DEF_ "NmhMessage" "No";
BA_DEF_DEF_ "VAGTP20_API" 0;
BA_DEF_DEF_ "VAGTP20_DynConnection" "No";
BA_DEF_DEF_ "VAGTP20_DynSetup" "No";
BA_DEF_DEF_ "VAGTP20_StatConnection" "No";
BA_DEF_DEF_ "VFrameFormat" "StandardCAN";
BA_DEF_DEF_REL_ "GenSigTimeoutTime" 0;
BA_ "GenMsgCycleTime" BO_ 851 40;
BA_ "GenMsgILSupport" BO_ 851 1;
BA_ "GenMsgPDUConstants" BO_ 851 "0x3a,0x97,0x6b,0x70,0x1e,0x84,0xe1,0xb4,0xde,0xb8,0x03,0xe7,0x33,0x20,0x3f,0x7c";
BA_ "GenMsgSendType" BO_ 851 0;
BA_ "VFrameFormat" BO_ 851 14;
BA_ "GenMsgCycleTime" BO_ 1520 200;
BA_ "GenMsgDelayTime" BO_ 1520 50;
BA_ "GenMsgILSupport" BO_ 1520 1;
BA_ "GenMsgSendType" BO_ 1520 0;
BA_ "VFrameFormat" BO_ 1520 14;
BA_ "GenMsgCycleTime" BO_ 2527679674 500;
BA_ "GenMsgDelayTime" BO_ 2527679674 50;
BA_ "GenMsgILSupport" BO_ 2527679674 1;
BA_ "GenMsgSendType" BO_ 2527679674 0;
BA_ "VFrameFormat" BO_ 2527679674 15;
BA_ "MsgType" BO_ 2630879546 4;
BA_ "VFrameFormat" BO_ 2630879546 15;
BA_ "MsgType" BO_ 2631010618 4;
BA_ "VFrameFormat" BO_ 2631010618 15;
BA_ "MsgType" BO_ 2621717001 4;
BA_ "VFrameFormat" BO_ 2621717001 15;
BA_ "MsgType" BO_ 2621848073 4;
BA_ "VFrameFormat" BO_ 2621848073 15;
BA_ "GenMsgCycleTime" BO_ 496 500;
BA_ "GenMsgDelayTime" BO_ 496 20;
BA_ "GenMsgILSupport" BO_ 496 1;
BA_ "GenMsgPDUConstants" BO_ 496 "0x2f,0x3c,0x22,0x60,0x18,0xeb,0x63,0x76,0xc5,0x91,0x0f,0x27,0x34,0x04,0x7f,0x02";
BA_ "GenMsgSendType" BO_ 496 0;
BA_ "VFrameFormat" BO_ 496 14;
BA_ "GenMsgCycleTime" BO_ 1622 1000;
BA_ "GenMsgCycleTimeFast" BO_ 1622 50;
BA_ "GenMsgDelayTime" BO_ 1622 50;
BA_ "GenMsgILSupport" BO_ 1622 1;
BA_ "GenMsgNrOfRepetition" BO_ 1622 5;
BA_ "GenMsgPDUConstants" BO_ 1622 "0xab,0x2f,0xd3,0x39,0x6f,0x37,0xfa,0x59,0xa4,0x70,0xce,0x11,0x54,0x82,0x62,0x56";
BA_ "GenMsgSendType" BO_ 1622 0;
BA_ "VFrameFormat" BO_ 1622 14;
BA_ "GenMsgCycleTime" BO_ 522 20;
BA_ "GenMsgILSupport" BO_ 522 1;
BA_ "GenMsgPDUConstants" BO_ 522 "0x9d,0xe8,0x36,0xa1,0xca,0x3b,0x1d,0x33,0xe0,0xd5,0xbb,0x5f,0xae,0x3c,0x31,0x9f";
BA_ "GenMsgSendType" BO_ 522 0;
BA_ "VFrameFormat" BO_ 522 14;
BA_ "GenMsgCycleTime" BO_ 608 50;
BA_ "GenMsgILSupport" BO_ 608 1;
BA_ "GenMsgSendType" BO_ 608 0;
BA_ "VFrameFormat" BO_ 608 14;
BA_ "GenMsgCycleTime" BO_ 2589283970 1000;
BA_ "GenMsgILSupport" BO_ 2589283970 1;
BA_ "GenMsgSendType" BO_ 2589283970 0;
BA_ "VFrameFormat" BO_ 2589283970 15;
BA_ "GenMsgCycleTime" BO_ 2331595989 50;
BA_ "GenMsgILSupport" BO_ 2331595989 1;
BA_ "GenMsgSendType" BO_ 2331595989 0;
BA_ "VFrameFormat" BO_ 2331595989 15;
BA_ "GenMsgCycleTime" BO_ 2589283751 500;
BA_ "GenMsgILSupport" BO_ 2589283751 1;
BA_ "GenMsgSendType" BO_ 2589283751 0;
BA_ "VFrameFormat" BO_ 2589283751 15;
BA_ "GenMsgCycleTime" BO_ 503 200;
BA_ "GenMsgDelayTime" BO_ 503 20;
BA_ "GenMsgILSupport" BO_ 503 1;
BA_ "GenMsgPDUConstants" BO_ 503 "0xe7,0x1f,0xa2,0xc2,0x76,0x25,0x1a,0x30,0xb7,0xc8,0xe8,0xe9,0x15,0x28,0x08,0x75";
BA_ "GenMsgSendType" BO_ 503 0;
BA_ "VFrameFormat" BO_ 503 14;
BA_ "GenMsgCycleTime" BO_ 258 20;
BA_ "GenMsgILSupport" BO_ 258 1;
BA_ "GenMsgPDUConstants" BO_ 258 "0xd7,0x12,0x85,0x7e,0x0b,0x34,0xfa,0x16,0x7a,0x25,0x2d,0x8f,0x04,0x8e,0x5d,0x35";
BA_ "GenMsgSendType" BO_ 258 0;
BA_ "VFrameFormat" BO_ 258 14;
BA_ "GenMsgCycleTime" BO_ 252 10;
BA_ "GenMsgILSupport" BO_ 252 1;
BA_ "GenMsgPDUConstants" BO_ 252 "0x69,0xdc,0xf9,0x64,0x6a,0xce,0x55,0x2c,0xc4,0x38,0x8f,0xd1,0xc6,0x43,0xb4,0xb1";
BA_ "GenMsgSendType" BO_ 252 0;
BA_ "VFrameFormat" BO_ 252 14;
BA_ "GenMsgCycleTime" BO_ 885 50;
BA_ "GenMsgILSupport" BO_ 885 1;
BA_ "GenMsgSendType" BO_ 885 0;
BA_ "VFrameFormat" BO_ 885 14;
BA_ "GenMsgChkConstant" BO_ 278 172;
BA_ "GenMsgCycleTime" BO_ 278 20;
BA_ "GenMsgILSupport" BO_ 278 1;
BA_ "GenMsgPDUConstants" BO_ 278 "0xac,0xac,0xac,0xac,0xac,0xac,0xac,0xac,0xac,0xac,0xac,0xac,0xac,0xac,0xac,0xac";
BA_ "GenMsgSendType" BO_ 278 0;
BA_ "VFrameFormat" BO_ 278 14;
BA_ "GenMsgCycleTime" BO_ 1629 1000;
BA_ "GenMsgDelayTime" BO_ 1629 200;
BA_ "GenMsgILSupport" BO_ 1629 1;
BA_ "GenMsgPDUConstants" BO_ 1629 "0xac,0xb3,0xab,0xeb,0x7a,0xe1,0x3b,0xf7,0x73,0xba,0x7c,0x9e,0x06,0x5f,0x02,0xd9";
BA_ "GenMsgSendType" BO_ 1629 0;
BA_ "VFrameFormat" BO_ 1629 14;
BA_ "GenMsgCycleTime" BO_ 253 20;
BA_ "GenMsgILSupport" BO_ 253 1;
BA_ "GenMsgPDUConstants" BO_ 253 "0xb4,0xef,0xf8,0x49,0x1e,0xe5,0xc2,0xc0,0x97,0x19,0x3c,0xc9,0xf1,0x98,0xd6,0x61";
BA_ "GenMsgSendType" BO_ 253 0;
BA_ "VFrameFormat" BO_ 253 14;
BA_ "GenMsgCycleTime" BO_ 795 50;
BA_ "GenMsgILSupport" BO_ 795 1;
BA_ "GenMsgPDUConstants" BO_ 795 "0x67,0x8a,0xae,0x22,0x4d,0xd0,0x51,0x80,0x5c,0xb9,0xce,0x1e,0xdf,0x02,0x2d,0xd4";
BA_ "GenMsgSendType" BO_ 795 0;
BA_ "VFrameFormat" BO_ 795 14;
BA_ "Fehlerwert" SG_ 851 DiETa_Car 3;
BA_ "GenSigSendType" SG_ 851 DiETa_Car 0;
BA_ "GenSigSwitchedByIgnition" SG_ 851 DiETa_Car 0;
BA_ "Fehlerwert" SG_ 851 DiETa_Defrost_Taste 3;
BA_ "GenSigSendType" SG_ 851 DiETa_Defrost_Taste 0;
BA_ "GenSigSwitchedByIgnition" SG_ 851 DiETa_Defrost_Taste 0;
BA_ "Fehlerwert" SG_ 851 DiETa_FAS_Stufe 3;
BA_ "GenSigSendType" SG_ 851 DiETa_FAS_Stufe 0;
BA_ "GenSigSwitchedByIgnition" SG_ 851 DiETa_FAS_Stufe 0;
BA_ "Fehlerwert" SG_ 851 DiETa_FSH_Taste 3;
BA_ "GenSigSendType" SG_ 851 DiETa_FSH_Taste 0;
BA_ "GenSigSwitchedByIgnition" SG_ 851 DiETa_FSH_Taste 0;
BA_ "Fehlerwert" SG_ 851 DiETa_HSH_Taste 3;
BA_ "GenSigSendType" SG_ 851 DiETa_HSH_Taste 0;
BA_ "GenSigSwitchedByIgnition" SG_ 851 DiETa_HSH_Taste 0;
BA_ "Fehlerwert" SG_ 851 DiETa_Klima 3;
BA_ "GenSigSendType" SG_ 851 DiETa_Klima 0;
BA_ "GenSigSwitchedByIgnition" SG_ 851 DiETa_Klima 0;
BA_ "Fehlerwert" SG_ 851 DiETa_Lock_Unlock_Taste 7;
BA_ "GenSigSendType" SG_ 851 DiETa_Lock_Unlock_Taste 0;
BA_ "GenSigSwitchedByIgnition" SG_ 851 DiETa_Lock_Unlock_Taste 0;
BA_ "Fehlerwert" SG_ 851 DiETa_Mode 3;
BA_ "GenSigSendType" SG_ 851 DiETa_Mode 0;
BA_ "GenSigSwitchedByIgnition" SG_ 851 DiETa_Mode 0;
BA_ "Fehlerwert" SG_ 851 DiETa_Mode2 3;
BA_ "GenSigSendType" SG_ 851 DiETa_Mode2 0;
BA_ "GenSigSwitchedByIgnition" SG_ 851 DiETa_Mode2 0;
BA_ "GenSigSendType" SG_ 851 DiETa_Mode_roh 0;
BA_ "GenSigSwitchedByIgnition" SG_ 851 DiETa_Mode_roh 0;
BA_ "GenSigSendType" SG_ 851 DiETa_PAO_OFF_Status 0;
BA_ "GenSigSwitchedByIgnition" SG_ 851 DiETa_PAO_OFF_Status 0;
BA_ "GenSigSendType" SG_ 851 DiETa_PAO_ON_Status 0;
BA_ "GenSigSwitchedByIgnition" SG_ 851 DiETa_PAO_ON_Status 0;
BA_ "Fehlerwert" SG_ 851 DiETa_Parken 3;
BA_ "GenSigSendType" SG_ 851 DiETa_Parken 0;
BA_ "GenSigSwitchedByIgnition" SG_ 851 DiETa_Parken 0;
BA_ "GenSigSendType" SG_ 851 DiETa_Reserve_Byte2_4 0;
BA_ "GenSigSwitchedByIgnition" SG_ 851 DiETa_Reserve_Byte2_4 0;
BA_ "GenSigSendType" SG_ 851 DiETa_Reserve_Byte6_6 0;
BA_ "GenSigSwitchedByIgnition" SG_ 851 DiETa_Reserve_Byte6_6 0;
BA_ "GenSigSendType" SG_ 851 DiETa_Reserve_Byte7_4 0;
BA_ "GenSigSwitchedByIgnition" SG_ 851 DiETa_Reserve_Byte7_4 0;
BA_ "GenSigSendType" SG_ 851 DiETa_Reserve_Byte8 0;
BA_ "GenSigSwitchedByIgnition" SG_ 851 DiETa_Reserve_Byte8 0;
BA_ "Fehlerwert" SG_ 851 DiETa_ResponseError 1;
BA_ "GenSigSendType" SG_ 851 DiETa_ResponseError 0;
BA_ "GenSigSwitchedByIgnition" SG_ 851 DiETa_ResponseError 0;
BA_ "GenSigSendType" SG_ 851 DiETa_Status 0;
BA_ "GenSigStartValue" SG_ 851 DiETa_Status 2;
BA_ "GenSigSwitchedByIgnition" SG_ 851 DiETa_Status 0;
BA_ "Fehlerwert" SG_ 851 DiETa_Touch_Event 15;
BA_ "GenSigSendType" SG_ 851 DiETa_Touch_Event 0;
BA_ "GenSigSwitchedByIgnition" SG_ 851 DiETa_Touch_Event 0;
BA_ "Fehlerwert" SG_ 851 DiETa_Warnblink_Taste 3;
BA_ "GenSigSendType" SG_ 851 DiETa_Warnblink_Taste 0;
BA_ "GenSigSwitchedByIgnition" SG_ 851 DiETa_Warnblink_Taste 0;
BA_ "GenSigFuncType" SG_ 851 DiETas_01_BZ 1;
BA_ "GenSigSendType" SG_ 851 DiETas_01_BZ 0;
BA_ "GenSigSwitchedByIgnition" SG_ 851 DiETas_01_BZ 0;
BA_ "GenSigFuncType" SG_ 851 DiETas_01_CRC 2;
BA_ "GenSigSendType" SG_ 851 DiETas_01_CRC 0;
BA_ "GenSigSwitchedByIgnition" SG_ 851 DiETas_01_CRC 0;
BA_ "Fehlerwert" SG_ 851 ESP_Off_Taster 3;
BA_ "GenSigSendType" SG_ 851 ESP_Off_Taster 0;
BA_ "GenSigStartValue" SG_ 851 ESP_Off_Taster 2;
BA_ "GenSigSwitchedByIgnition" SG_ 851 ESP_Off_Taster 0;
BA_ "Fehlerwert" SG_ 1520 BCM1_Stellgroesse_Kl_58s 127;
BA_ "GenSigSendType" SG_ 1520 BCM1_Stellgroesse_Kl_58s 3;
BA_ "GenSigStartValue" SG_ 1520 BCM1_Stellgroesse_Kl_58s 126;
BA_ "GenSigSwitchedByIgnition" SG_ 1520 BCM1_Stellgroesse_Kl_58s 0;
BA_ "GenSigSendType" SG_ 1520 DI_Display_Nachtdesign 3;
BA_ "GenSigSwitchedByIgnition" SG_ 1520 DI_Display_Nachtdesign 0;
BA_ "GenSigSendType" SG_ 1520 DI_Fotosensor 3;
BA_ "GenSigSwitchedByIgnition" SG_ 1520 DI_Fotosensor 0;
BA_ "Fehlerwert" SG_ 1520 DI_KL_58xd 255;
BA_ "GenSigSendType" SG_ 1520 DI_KL_58xd 3;
BA_ "GenSigStartValue" SG_ 1520 DI_KL_58xd 254;
BA_ "GenSigSwitchedByIgnition" SG_ 1520 DI_KL_58xd 0;
BA_ "Fehlerwert" SG_ 1520 DI_KL_58xs 127;
BA_ "GenSigSendType" SG_ 1520 DI_KL_58xs 3;
BA_ "GenSigStartValue" SG_ 1520 DI_KL_58xs 126;
BA_ "GenSigSwitchedByIgnition" SG_ 1520 DI_KL_58xs 0;
BA_ "Fehlerwert" SG_ 1520 DI_KL_58xt 127;
BA_ "GenSigSendType" SG_ 1520 DI_KL_58xt 3;
BA_ "GenSigStartValue" SG_ 1520 DI_KL_58xt 126;
BA_ "GenSigSwitchedByIgnition" SG_ 1520 DI_KL_58xt 0;
BA_ "GenSigSendType" SG_ 2527679674 DispKBI_FS_Systemstatus 3;
BA_ "GenSigSwitchedByIgnition" SG_ 2527679674 DispKBI_FS_Systemstatus 0;
BA_ "GenSigFuncType" SG_ 2630879546 DispKBI_FS_DispPos_Req_FD_Data 9;
BA_ "GenSigSendType" SG_ 2630879546 DispKBI_FS_DispPos_Req_FD_Data 3;
BA_ "GenSigSwitchedByIgnition" SG_ 2630879546 DispKBI_FS_DispPos_Req_FD_Data 0;
BA_ "GenSigFuncType" SG_ 2631010618 DispKBI_FS_DispPos_Resp_FD_Data 9;
BA_ "GenSigSendType" SG_ 2631010618 DispKBI_FS_DispPos_Resp_FD_Data 3;
BA_ "GenSigSwitchedByIgnition" SG_ 2631010618 DispKBI_FS_DispPos_Resp_FD_Data 0;
BA_ "GenSigFuncType" SG_ 2621717001 DispPos_DispKBI_FS_Req_FD_Data 9;
BA_ "GenSigSendType" SG_ 2621717001 DispPos_DispKBI_FS_Req_FD_Data 3;
BA_ "GenSigSwitchedByIgnition" SG_ 2621717001 DispPos_DispKBI_FS_Req_FD_Data 0;
BA_ "GenSigFuncType" SG_ 2621848073 DispPos_DispKBI_FS_Resp_FD_Data 9;
BA_ "GenSigSendType" SG_ 2621848073 DispPos_DispKBI_FS_Resp_FD_Data 3;
BA_ "GenSigSwitchedByIgnition" SG_ 2621848073 DispPos_DispKBI_FS_Resp_FD_Data 0;
BA_ "GenSigSendType" SG_ 496 ACF_Lampe_Hands_Off 3;
BA_ "GenSigSwitchedByIgnition" SG_ 496 ACF_Lampe_Hands_Off 0;
BA_ "GenSigFuncType" SG_ 496 EA_02_BZ 1;
BA_ "GenSigSendType" SG_ 496 EA_02_BZ 0;
BA_ "GenSigFuncType" SG_ 496 EA_02_CRC 2;
BA_ "GenSigSendType" SG_ 496 EA_02_CRC 0;
BA_ "GenSigSendType" SG_ 496 EA_Blinken 3;
BA_ "GenSigSendType" SG_ 496 EA_Bremslichtblinken 3;
BA_ "GenSigSendType" SG_ 496 EA_eCall_Anf 3;
BA_ "GenSigSwitchedByIgnition" SG_ 496 EA_eCall_Anf 0;
BA_ "GenSigSendType" SG_ 496 EA_Fahrzeughupe_Anf 3;
BA_ "GenSigSendType" SG_ 496 EA_Infotainment_Anf 3;
BA_ "GenSigSendType" SG_ 496 EA_Innenraumlicht_Anf 3;
BA_ "GenSigSendType" SG_ 496 EA_Status_HMI 3;
BA_ "GenSigSendType" SG_ 496 EA_Texte 3;
BA_ "GenSigSendType" SG_ 496 EA_Tueren_Anf 3;
BA_ "GenSigSendType" SG_ 496 EA_Warnlevel 3;
BA_ "GenSigSendType" SG_ 496 STP_Primaeranz 3;
BA_ "GenSigSendType" SG_ 496 zFAS_Warnblinken 3;
BA_ "GenSigFuncType" SG_ 1622 ELV_01_BZ 1;
BA_ "GenSigSendType" SG_ 1622 ELV_01_BZ 0;
BA_ "GenSigSwitchedByIgnition" SG_ 1622 ELV_01_BZ 0;
BA_ "GenSigFuncType" SG_ 1622 ELV_01_CRC 2;
BA_ "GenSigSendType" SG_ 1622 ELV_01_CRC 0;
BA_ "GenSigSwitchedByIgnition" SG_ 1622 ELV_01_CRC 0;
BA_ "GenSigSendType" SG_ 1622 ELV_01_Sendestatus 5;
BA_ "GenSigSwitchedByIgnition" SG_ 1622 ELV_01_Sendestatus 0;
BA_ "GenSigSendType" SG_ 1622 ELV_Abbruch_Anf_Klemmenfreigabe 3;
BA_ "GenSigSwitchedByIgnition" SG_ 1622 ELV_Abbruch_Anf_Klemmenfreigabe 0;
BA_ "GenSigSendType" SG_ 1622 ELV_Anf_Klemme_15 3;
BA_ "GenSigSwitchedByIgnition" SG_ 1622 ELV_Anf_Klemme_15 0;
BA_ "GenSigSendType" SG_ 1622 ELV_Anf_Klemme_50 3;
BA_ "GenSigSwitchedByIgnition" SG_ 1622 ELV_Anf_Klemme_50 0;
BA_ "GenSigSendType" SG_ 1622 ELV_Anf_Klemme_S 3;
BA_ "GenSigSwitchedByIgnition" SG_ 1622 ELV_Anf_Klemme_S 0;
BA_ "GenSigSendType" SG_ 1622 ELV_Anlernmodus 3;
BA_ "GenSigSwitchedByIgnition" SG_ 1622 ELV_Anlernmodus 0;
BA_ "GenSigSendType" SG_ 1622 ELV_Entriegelt 3;
BA_ "GenSigSwitchedByIgnition" SG_ 1622 ELV_Entriegelt 0;
BA_ "GenSigSendType" SG_ 1622 ELV_Klemmenfreigabe 3;
BA_ "GenSigSwitchedByIgnition" SG_ 1622 ELV_Klemmenfreigabe 0;
BA_ "GenSigSendType" SG_ 1622 ELV_Lebenszustand 3;
BA_ "GenSigSwitchedByIgnition" SG_ 1622 ELV_Lebenszustand 0;
BA_ "GenSigSendType" SG_ 1622 ELV_LED_Gelb 3;
BA_ "GenSigSwitchedByIgnition" SG_ 1622 ELV_LED_Gelb 0;
BA_ "GenSigSendType" SG_ 1622 ELV_LED_Rot 3;
BA_ "GenSigSwitchedByIgnition" SG_ 1622 ELV_LED_Rot 0;
BA_ "GenSigSendType" SG_ 1622 ELV_P_verriegelt 3;
BA_ "GenSigSwitchedByIgnition" SG_ 1622 ELV_P_verriegelt 0;
BA_ "GenSigSendType" SG_ 1622 ELV_Txt_Bremse 3;
BA_ "GenSigSwitchedByIgnition" SG_ 1622 ELV_Txt_Bremse 0;
BA_ "GenSigSendType" SG_ 1622 ELV_Txt_Defekt 3;
BA_ "GenSigSwitchedByIgnition" SG_ 1622 ELV_Txt_Defekt 0;
BA_ "GenSigSendType" SG_ 1622 ELV_Txt_Kupplung 3;
BA_ "GenSigSwitchedByIgnition" SG_ 1622 ELV_Txt_Kupplung 0;
BA_ "GenSigSendType" SG_ 1622 ELV_Txt_Lkg_Bewegen 3;
BA_ "GenSigSwitchedByIgnition" SG_ 1622 ELV_Txt_Lkg_Bewegen 0;
BA_ "GenSigSendType" SG_ 1622 ELV_Txt_P_Gang 3;
BA_ "GenSigSwitchedByIgnition" SG_ 1622 ELV_Txt_P_Gang 0;
BA_ "GenSigSendType" SG_ 1622 ELV_Txt_Panikabschaltung 3;
BA_ "GenSigSwitchedByIgnition" SG_ 1622 ELV_Txt_Panikabschaltung 0;
BA_ "GenSigSendType" SG_ 1622 ELV_Txt_PN_Gang 3;
BA_ "GenSigSwitchedByIgnition" SG_ 1622 ELV_Txt_PN_Gang 0;
BA_ "GenSigSendType" SG_ 1622 ELV_Txt_Werkstatt 3;
BA_ "GenSigSwitchedByIgnition" SG_ 1622 ELV_Txt_Werkstatt 0;
BA_ "GenSigSendType" SG_ 1622 ELV_Verriegelt 3;
BA_ "GenSigSwitchedByIgnition" SG_ 1622 ELV_Verriegelt 0;
BA_ "GenSigSendType" SG_ 1622 ELV_ZAT_betaetigt 3;
BA_ "GenSigSwitchedByIgnition" SG_ 1622 ELV_ZAT_betaetigt 0;
BA_ "GenSigSendType" SG_ 1622 KST_Anf_ZV_Verriegelung 3;
BA_ "GenSigSwitchedByIgnition" SG_ 1622 KST_Anf_ZV_Verriegelung 0;
BA_ "GenSigSendType" SG_ 1622 KST_aut_Abschaltung_Zuendung 4;
BA_ "GenSigSwitchedByIgnition" SG_ 1622 KST_aut_Abschaltung_Zuendung 0;
BA_ "GenSigSendType" SG_ 1622 KST_Txt_Komfortabschaltung 3;
BA_ "GenSigSwitchedByIgnition" SG_ 1622 KST_Txt_Komfortabschaltung 0;
BA_ "GenSigFuncType" SG_ 522 EML_06_BZ 1;
BA_ "GenSigSendType" SG_ 522 EML_06_BZ 0;
BA_ "GenSigFuncType" SG_ 522 EML_06_CRC 2;
BA_ "GenSigSendType" SG_ 522 EML_06_CRC 0;
BA_ "Fehlerwert" SG_ 522 EML_AnzeigeGeschw 1023;
BA_ "GenSigSendType" SG_ 522 EML_AnzeigeGeschw 0;
BA_ "GenSigStartValue" SG_ 522 EML_AnzeigeGeschw 1022;
BA_ "Fehlerwert" SG_ 522 EML_BeschlX 2047;
BA_ "GenSigSendType" SG_ 522 EML_BeschlX 0;
BA_ "GenSigStartValue" SG_ 522 EML_BeschlX 2046;
BA_ "Fehlerwert" SG_ 522 EML_BeschlXCF 7;
BA_ "GenSigSendType" SG_ 522 EML_BeschlXCF 0;
BA_ "GenSigStartValue" SG_ 522 EML_BeschlXCF 6;
BA_ "Fehlerwert" SG_ 522 EML_BeschlY 2047;
BA_ "GenSigSendType" SG_ 522 EML_BeschlY 0;
BA_ "GenSigStartValue" SG_ 522 EML_BeschlY 2046;
BA_ "Fehlerwert" SG_ 522 EML_BeschlYCF 7;
BA_ "GenSigSendType" SG_ 522 EML_BeschlYCF 0;
BA_ "GenSigStartValue" SG_ 522 EML_BeschlYCF 6;
BA_ "Fehlerwert" SG_ 522 EML_Fahrtrichtungswahrsch 255;
BA_ "GenSigSendType" SG_ 522 EML_Fahrtrichtungswahrsch 0;
BA_ "GenSigStartValue" SG_ 522 EML_Fahrtrichtungswahrsch 254;
BA_ "Fehlerwert" SG_ 522 EML_Fahrwerksregeleingriff 7;
BA_ "GenSigSendType" SG_ 522 EML_Fahrwerksregeleingriff 0;
BA_ "GenSigStartValue" SG_ 522 EML_Fahrwerksregeleingriff 6;
BA_ "GenSigSwitchedByIgnition" SG_ 522 EML_Fahrwerksregeleingriff 0;
BA_ "Fehlerwert" SG_ 522 EML_GeschwX 4095;
BA_ "GenSigSendType" SG_ 522 EML_GeschwX 0;
BA_ "GenSigStartValue" SG_ 522 EML_GeschwX 4094;
BA_ "Fehlerwert" SG_ 522 EML_GeschwXStdA 63;
BA_ "GenSigSendType" SG_ 522 EML_GeschwXStdA 0;
BA_ "GenSigStartValue" SG_ 522 EML_GeschwXStdA 62;
BA_ "Fehlerwert" SG_ 522 EML_GierRate 65535;
BA_ "GenSigSendType" SG_ 522 EML_GierRate 0;
BA_ "GenSigStartValue" SG_ 522 EML_GierRate 65534;
BA_ "GenSigSwitchedByIgnition" SG_ 522 EML_GierRate 0;
BA_ "Fehlerwert" SG_ 522 EML_GierRateCF 7;
BA_ "GenSigSendType" SG_ 522 EML_GierRateCF 0;
BA_ "GenSigStartValue" SG_ 522 EML_GierRateCF 6;
BA_ "Fehlerwert" SG_ 522 EML_GierRateStdA 63;
BA_ "GenSigSendType" SG_ 522 EML_GierRateStdA 0;
BA_ "GenSigStartValue" SG_ 522 EML_GierRateStdA 62;
BA_ "Fehlerwert" SG_ 522 EML_Gierwinkel 16383;
BA_ "GenSigSendType" SG_ 522 EML_Gierwinkel 0;
BA_ "GenSigStartValue" SG_ 522 EML_Gierwinkel 16382;
BA_ "Fehlerwert" SG_ 522 EML_GierwinkelCF 3;
BA_ "GenSigSendType" SG_ 522 EML_GierwinkelCF 0;
BA_ "GenSigStartValue" SG_ 522 EML_GierwinkelCF 2;
BA_ "Fehlerwert" SG_ 522 EML_GierwinkelStdA 31;
BA_ "GenSigSendType" SG_ 522 EML_GierwinkelStdA 0;
BA_ "GenSigStartValue" SG_ 522 EML_GierwinkelStdA 30;
BA_ "Fehlerwert" SG_ 522 EML_Hoehe2USK 127;
BA_ "GenSigSendType" SG_ 522 EML_Hoehe2USK 0;
BA_ "GenSigStartValue" SG_ 522 EML_Hoehe2USK 126;
BA_ "Fehlerwert" SG_ 522 EML_Hoehe2USKStdA 15;
BA_ "GenSigSendType" SG_ 522 EML_Hoehe2USKStdA 0;
BA_ "GenSigStartValue" SG_ 522 EML_Hoehe2USKStdA 14;
BA_ "Fehlerwert" SG_ 522 EML_Hoehe_Nick_Wankwinkel2USKCF 3;
BA_ "GenSigSendType" SG_ 522 EML_Hoehe_Nick_Wankwinkel2USKCF 0;
BA_ "GenSigStartValue" SG_ 522 EML_Hoehe_Nick_Wankwinkel2USKCF 2;
BA_ "Fehlerwert" SG_ 522 EML_Kurvenkruemmung 16383;
BA_ "GenSigSendType" SG_ 522 EML_Kurvenkruemmung 0;
BA_ "GenSigStartValue" SG_ 522 EML_Kurvenkruemmung 16382;
BA_ "Fehlerwert" SG_ 522 EML_LenkWnklVL 1023;
BA_ "GenSigSendType" SG_ 522 EML_LenkWnklVL 0;
BA_ "GenSigStartValue" SG_ 522 EML_LenkWnklVL 1022;
BA_ "Fehlerwert" SG_ 522 EML_LenkWnklVR 1023;
BA_ "GenSigSendType" SG_ 522 EML_LenkWnklVR 0;
BA_ "GenSigStartValue" SG_ 522 EML_LenkWnklVR 1022;
BA_ "GenSigSendType" SG_ 522 EML_MessZeitpunkt 0;
BA_ "GenSigStartValue" SG_ 522 EML_MessZeitpunkt 8191;
BA_ "Fehlerwert" SG_ 522 EML_Nickwinkel 4095;
BA_ "GenSigSendType" SG_ 522 EML_Nickwinkel 0;
BA_ "GenSigStartValue" SG_ 522 EML_Nickwinkel 4094;
BA_ "Fehlerwert" SG_ 522 EML_Nickwinkel2USK 127;
BA_ "GenSigSendType" SG_ 522 EML_Nickwinkel2USK 0;
BA_ "GenSigStartValue" SG_ 522 EML_Nickwinkel2USK 126;
BA_ "Fehlerwert" SG_ 522 EML_Nickwinkel2USKStdA 15;
BA_ "GenSigSendType" SG_ 522 EML_Nickwinkel2USKStdA 0;
BA_ "GenSigStartValue" SG_ 522 EML_Nickwinkel2USKStdA 14;
BA_ "GenSigSendType" SG_ 522 EML_Pose_Qualifier 0;
BA_ "GenSigSwitchedByIgnition" SG_ 522 EML_Pose_Qualifier 0;
BA_ "Fehlerwert" SG_ 522 EML_PositionCF 3;
BA_ "GenSigSendType" SG_ 522 EML_PositionCF 0;
BA_ "GenSigStartValue" SG_ 522 EML_PositionCF 2;
BA_ "Fehlerwert" SG_ 522 EML_PositionX 16383;
BA_ "GenSigSendType" SG_ 522 EML_PositionX 0;
BA_ "GenSigStartValue" SG_ 522 EML_PositionX 16382;
BA_ "Fehlerwert" SG_ 522 EML_PositionXStdA 63;
BA_ "GenSigSendType" SG_ 522 EML_PositionXStdA 0;
BA_ "GenSigStartValue" SG_ 522 EML_PositionXStdA 62;
BA_ "Fehlerwert" SG_ 522 EML_PositionY 16383;
BA_ "GenSigSendType" SG_ 522 EML_PositionY 0;
BA_ "GenSigStartValue" SG_ 522 EML_PositionY 16382;
BA_ "Fehlerwert" SG_ 522 EML_PositionYStdA 63;
BA_ "GenSigSendType" SG_ 522 EML_PositionYStdA 0;
BA_ "GenSigStartValue" SG_ 522 EML_PositionYStdA 62;
BA_ "GenSigSendType" SG_ 522 EML_QBit_Anzeigegeschw 0;
BA_ "GenSigStartValue" SG_ 522 EML_QBit_Anzeigegeschw 1;
BA_ "GenSigSendType" SG_ 522 EML_QBit_Fahrtrichtungswahrsch 0;
BA_ "GenSigStartValue" SG_ 522 EML_QBit_Fahrtrichtungswahrsch 1;
BA_ "GenSigSendType" SG_ 522 EML_QBit_Kurvenkruemmung 0;
BA_ "GenSigStartValue" SG_ 522 EML_QBit_Kurvenkruemmung 1;
BA_ "GenSigSendType" SG_ 522 EML_QBit_Nickwinkel 0;
BA_ "GenSigStartValue" SG_ 522 EML_QBit_Nickwinkel 1;
BA_ "GenSigSendType" SG_ 522 EML_QBit_Stillstandswahrsch 0;
BA_ "GenSigStartValue" SG_ 522 EML_QBit_Stillstandswahrsch 1;
BA_ "Fehlerwert" SG_ 522 EML_Stillstandswahrsch 127;
BA_ "GenSigSendType" SG_ 522 EML_Stillstandswahrsch 0;
BA_ "GenSigStartValue" SG_ 522 EML_Stillstandswahrsch 126;
BA_ "Fehlerwert" SG_ 522 EML_Wankwinkel2USK 255;
BA_ "GenSigSendType" SG_ 522 EML_Wankwinkel2USK 0;
BA_ "GenSigStartValue" SG_ 522 EML_Wankwinkel2USK 254;
BA_ "Fehlerwert" SG_ 522 EML_Wankwinkel2USKStdA 15;
BA_ "GenSigSendType" SG_ 522 EML_Wankwinkel2USKStdA 0;
BA_ "GenSigStartValue" SG_ 522 EML_Wankwinkel2USKStdA 14;
BA_ "Fehlerwert" SG_ 608 EML_AnzeigeGeschw 1023;
BA_ "GenSigSendType" SG_ 608 EML_AnzeigeGeschw 0;
BA_ "GenSigStartValue" SG_ 608 EML_AnzeigeGeschw 1022;
BA_ "GenSigSendType" SG_ 608 EML_QBit_Anzeigegeschw 0;
BA_ "GenSigStartValue" SG_ 608 EML_QBit_Anzeigegeschw 1;
BA_ "GenSigSendType" SG_ 2589283970 DIST_DKmtg_Auth 0;
BA_ "GenSigSwitchedByIgnition" SG_ 2589283970 DIST_DKmtg_Auth 0;
BA_ "GenSigFuncType" SG_ 2589283970 SOK_Entfernung_02_Signatur 15;
BA_ "GenSigSendType" SG_ 2589283970 SOK_Entfernung_02_Signatur 0;
BA_ "GenSigSwitchedByIgnition" SG_ 2589283970 SOK_Entfernung_02_Signatur 0;
BA_ "GenSigSendType" SG_ 2331595989 DIST_DKmtg 0;
BA_ "GenSigSwitchedByIgnition" SG_ 2331595989 DIST_DKmtg 0;
BA_ "Fehlerwert" SG_ 2589283751 KBI_Kilometerstand_Extended 16777215;
BA_ "GenSigSendType" SG_ 2589283751 KBI_Kilometerstand_Extended 0;
BA_ "GenSigStartValue" SG_ 2589283751 KBI_Kilometerstand_Extended 16777214;
BA_ "GenSigSwitchedByIgnition" SG_ 2589283751 KBI_Kilometerstand_Extended 0;
BA_ "GenSigSendType" SG_ 2589283751 KBI_Kilometerstand_HiRes_meter 0;
BA_ "GenSigSwitchedByIgnition" SG_ 2589283751 KBI_Kilometerstand_HiRes_meter 0;
BA_ "GenSigFuncType" SG_ 503 EPB_03_BZ 1;
BA_ "GenSigSendType" SG_ 503 EPB_03_BZ 0;
BA_ "GenSigSwitchedByIgnition" SG_ 503 EPB_03_BZ 0;
BA_ "GenSigFuncType" SG_ 503 EPB_03_CRC 2;
BA_ "GenSigSendType" SG_ 503 EPB_03_CRC 0;
BA_ "GenSigSwitchedByIgnition" SG_ 503 EPB_03_CRC 0;
BA_ "GenSigSendType" SG_ 503 EPB_Autohold_Standbyanzeige 3;
BA_ "GenSigSwitchedByIgnition" SG_ 503 EPB_Autohold_Standbyanzeige 0;
BA_ "GenSigSendType" SG_ 503 EPB_Autoholdlampe_02 3;
BA_ "GenSigSwitchedByIgnition" SG_ 503 EPB_Autoholdlampe_02 0;
BA_ "GenSigSendType" SG_ 503 EPB_Fehlermeldungen_02 3;
BA_ "GenSigSwitchedByIgnition" SG_ 503 EPB_Fehlermeldungen_02 0;
BA_ "GenSigSendType" SG_ 503 EPB_Funktionslampe_02 3;
BA_ "GenSigSwitchedByIgnition" SG_ 503 EPB_Funktionslampe_02 0;
BA_ "GenSigSendType" SG_ 503 EPB_Parkanzeige 3;
BA_ "GenSigSwitchedByIgnition" SG_ 503 EPB_Parkanzeige 0;
BA_ "GenSigSendType" SG_ 503 EPB_Texte_02 3;
BA_ "GenSigSwitchedByIgnition" SG_ 503 EPB_Texte_02 0;
BA_ "GenSigSendType" SG_ 258 ASR_Systemstatus 0;
BA_ "GenSigStartValue" SG_ 258 ASR_Systemstatus 2;
BA_ "GenSigSwitchedByIgnition" SG_ 258 ASR_Systemstatus 0;
BA_ "GenSigSendType" SG_ 258 ECD_Bremslicht 0;
BA_ "GenSigSwitchedByIgnition" SG_ 258 ECD_Bremslicht 0;
BA_ "GenSigSendType" SG_ 258 ECD_Fehler 0;
BA_ "GenSigSwitchedByIgnition" SG_ 258 ECD_Fehler 0;
BA_ "GenSigSendType" SG_ 258 ECD_nicht_verfuegbar 0;
BA_ "GenSigStartValue" SG_ 258 ECD_nicht_verfuegbar 1;
BA_ "GenSigSwitchedByIgnition" SG_ 258 ECD_nicht_verfuegbar 0;
BA_ "GenSigSendType" SG_ 258 EPB_DAA_Randbed_erf 0;
BA_ "GenSigSwitchedByIgnition" SG_ 258 EPB_DAA_Randbed_erf 0;
BA_ "GenSigSendType" SG_ 258 EPB_Fehlerstatus_02 0;
BA_ "GenSigSwitchedByIgnition" SG_ 258 EPB_Fehlerstatus_02 0;
BA_ "GenSigSendType" SG_ 258 EPB_Freig_Verzoeg_Anf 0;
BA_ "GenSigSwitchedByIgnition" SG_ 258 EPB_Freig_Verzoeg_Anf 0;
BA_ "Fehlerwert" SG_ 258 EPB_Pedalweg_Kuppl 255;
BA_ "GenSigSendType" SG_ 258 EPB_Pedalweg_Kuppl 0;
BA_ "GenSigSwitchedByIgnition" SG_ 258 EPB_Pedalweg_Kuppl 0;
BA_ "GenSigSendType" SG_ 258 EPB_QBit_Pedalweg_Kuppl 0;
BA_ "GenSigStartValue" SG_ 258 EPB_QBit_Pedalweg_Kuppl 1;
BA_ "GenSigSwitchedByIgnition" SG_ 258 EPB_QBit_Pedalweg_Kuppl 0;
BA_ "GenSigSendType" SG_ 258 EPB_QBit_Schalterpos 0;
BA_ "GenSigStartValue" SG_ 258 EPB_QBit_Schalterpos 1;
BA_ "GenSigSwitchedByIgnition" SG_ 258 EPB_QBit_Schalterpos 0;
BA_ "Fehlerwert" SG_ 258 EPB_Schalterposition 3;
BA_ "GenSigSendType" SG_ 258 EPB_Schalterposition 0;
BA_ "GenSigSwitchedByIgnition" SG_ 258 EPB_Schalterposition 0;
BA_ "Fehlerwert" SG_ 258 EPB_Spannkraft 31;
BA_ "GenSigSendType" SG_ 258 EPB_Spannkraft 0;
BA_ "GenSigStartValue" SG_ 258 EPB_Spannkraft 30;
BA_ "GenSigSwitchedByIgnition" SG_ 258 EPB_Spannkraft 0;
BA_ "GenSigSendType" SG_ 258 EPB_Status 0;
BA_ "GenSigSwitchedByIgnition" SG_ 258 EPB_Status 0;
BA_ "GenSigSendType" SG_ 258 EPB_Status_02 0;
BA_ "GenSigStartValue" SG_ 258 EPB_Status_02 6;
BA_ "GenSigSwitchedByIgnition" SG_ 258 EPB_Status_02 0;
BA_ "GenSigSendType" SG_ 258 EPB_Verzoeg_Anf 0;
BA_ "GenSigStartValue" SG_ 258 EPB_Verzoeg_Anf 166;
BA_ "GenSigSwitchedByIgnition" SG_ 258 EPB_Verzoeg_Anf 0;
BA_ "GenSigFuncType" SG_ 258 ESC_50_BZ 1;
BA_ "GenSigSendType" SG_ 258 ESC_50_BZ 0;
BA_ "GenSigSwitchedByIgnition" SG_ 258 ESC_50_BZ 0;
BA_ "GenSigFuncType" SG_ 258 ESC_50_CRC 2;
BA_ "GenSigSendType" SG_ 258 ESC_50_CRC 0;
BA_ "GenSigSwitchedByIgnition" SG_ 258 ESC_50_CRC 0;
BA_ "Fehlerwert" SG_ 258 ESC_Bremsdruckgradient 255;
BA_ "GenSigSendType" SG_ 258 ESC_Bremsdruckgradient 0;
BA_ "GenSigStartValue" SG_ 258 ESC_Bremsdruckgradient 254;
BA_ "GenSigSwitchedByIgnition" SG_ 258 ESC_Bremsdruckgradient 0;
BA_ "Fehlerwert" SG_ 258 ESC_Fahrerbremswunsch 1023;
BA_ "GenSigSendType" SG_ 258 ESC_Fahrerbremswunsch 0;
BA_ "GenSigStartValue" SG_ 258 ESC_Fahrerbremswunsch 100;
BA_ "GenSigSwitchedByIgnition" SG_ 258 ESC_Fahrerbremswunsch 0;
BA_ "Fehlerwert" SG_ 258 ESC_Fahrerradbremswunschmoment 4095;
BA_ "GenSigSendType" SG_ 258 ESC_Fahrerradbremswunschmoment 0;
BA_ "GenSigStartValue" SG_ 258 ESC_Fahrerradbremswunschmoment 4094;
BA_ "GenSigSwitchedByIgnition" SG_ 258 ESC_Fahrerradbremswunschmoment 0;
BA_ "GenSigSendType" SG_ 258 ESC_Hydr_Fkt_aktiv 0;
BA_ "GenSigSwitchedByIgnition" SG_ 258 ESC_Hydr_Fkt_aktiv 0;
BA_ "GenSigSendType" SG_ 258 ESC_Motorstartverzoegerung 0;
BA_ "GenSigSwitchedByIgnition" SG_ 258 ESC_Motorstartverzoegerung 0;
BA_ "GenSigSendType" SG_ 258 ESC_QBit_Fahrerbremswunsch 0;
BA_ "GenSigStartValue" SG_ 258 ESC_QBit_Fahrerbremswunsch 1;
BA_ "GenSigSwitchedByIgnition" SG_ 258 ESC_QBit_Fahrerbremswunsch 0;
BA_ "Fehlerwert" SG_ 258 ESC_Raddruck_max 255;
BA_ "GenSigSendType" SG_ 258 ESC_Raddruck_max 0;
BA_ "GenSigStartValue" SG_ 258 ESC_Raddruck_max 254;
BA_ "GenSigSwitchedByIgnition" SG_ 258 ESC_Raddruck_max 0;
BA_ "GenSigSendType" SG_ 258 ESC_SeitenwindAssistent_Eingriff 0;
BA_ "GenSigSwitchedByIgnition" SG_ 258 ESC_SeitenwindAssistent_Eingriff 0;
BA_ "GenSigSendType" SG_ 258 ESC_Unterdruckmangel_erkannt 0;
BA_ "GenSigSwitchedByIgnition" SG_ 258 ESC_Unterdruckmangel_erkannt 0;
BA_ "Fehlerwert" SG_ 258 ESCGeneratorSollMoment 4095;
BA_ "GenSigSendType" SG_ 258 ESCGeneratorSollMoment 0;
BA_ "GenSigStartValue" SG_ 258 ESCGeneratorSollMoment 4094;
BA_ "GenSigSwitchedByIgnition" SG_ 258 ESCGeneratorSollMoment 0;
BA_ "GenSigSendType" SG_ 258 ESP_Abrutschen_Stillstand 0;
BA_ "GenSigSwitchedByIgnition" SG_ 258 ESP_Abrutschen_Stillstand 0;
BA_ "GenSigSendType" SG_ 258 ESP_ANB_CM_Rueckk_Umsetz 0;
BA_ "GenSigSwitchedByIgnition" SG_ 258 ESP_ANB_CM_Rueckk_Umsetz 0;
BA_ "GenSigSendType" SG_ 258 ESP_Anforderung_EPB 0;
BA_ "GenSigSwitchedByIgnition" SG_ 258 ESP_Anforderung_EPB 0;
BA_ "GenSigSendType" SG_ 258 ESP_Anschleppstart_Freigabe 0;
BA_ "GenSigSwitchedByIgnition" SG_ 258 ESP_Anschleppstart_Freigabe 0;
BA_ "GenSigSendType" SG_ 258 ESP_Autohold_aktiv 0;
BA_ "GenSigSwitchedByIgnition" SG_ 258 ESP_Autohold_aktiv 0;
BA_ "GenSigSendType" SG_ 258 ESP_Autohold_Standby 0;
BA_ "GenSigSwitchedByIgnition" SG_ 258 ESP_Autohold_Standby 0;
BA_ "Fehlerwert" SG_ 258 ESP_BKV_Unterdruck 255;
BA_ "GenSigSendType" SG_ 258 ESP_BKV_Unterdruck 0;
BA_ "GenSigStartValue" SG_ 258 ESP_BKV_Unterdruck 254;
BA_ "GenSigSwitchedByIgnition" SG_ 258 ESP_BKV_Unterdruck 0;
BA_ "Fehlerwert" SG_ 258 ESP_Bremsdruck 1023;
BA_ "GenSigSendType" SG_ 258 ESP_Bremsdruck 0;
BA_ "GenSigStartValue" SG_ 258 ESP_Bremsdruck 100;
BA_ "GenSigSwitchedByIgnition" SG_ 258 ESP_Bremsdruck 0;
BA_ "GenSigSendType" SG_ 258 ESP_Bremsruck_AWV2 0;
BA_ "GenSigSwitchedByIgnition" SG_ 258 ESP_Bremsruck_AWV2 0;
BA_ "GenSigSendType" SG_ 258 ESP_Eingr_HL 0;
BA_ "GenSigSwitchedByIgnition" SG_ 258 ESP_Eingr_HL 0;
BA_ "GenSigSendType" SG_ 258 ESP_Eingr_HR 0;
BA_ "GenSigSwitchedByIgnition" SG_ 258 ESP_Eingr_HR 0;
BA_ "GenSigSendType" SG_ 258 ESP_Eingr_VL 0;
BA_ "GenSigSwitchedByIgnition" SG_ 258 ESP_Eingr_VL 0;
BA_ "GenSigSendType" SG_ 258 ESP_Eingr_VR 0;
BA_ "GenSigSwitchedByIgnition" SG_ 258 ESP_Eingr_VR 0;
BA_ "GenSigSendType" SG_ 258 ESP_Fahrer_bremst 0;
BA_ "GenSigSwitchedByIgnition" SG_ 258 ESP_Fahrer_bremst 0;
BA_ "GenSigSendType" SG_ 258 ESP_Fahrer_tritt_ZBR_Schw 0;
BA_ "GenSigSwitchedByIgnition" SG_ 258 ESP_Fahrer_tritt_ZBR_Schw 0;
BA_ "Fehlerwert" SG_ 258 ESP_FStatus_Anfahrhilfe 1;
BA_ "GenSigSendType" SG_ 258 ESP_FStatus_Anfahrhilfe 0;
BA_ "GenSigSwitchedByIgnition" SG_ 258 ESP_FStatus_Anfahrhilfe 0;
BA_ "Fehlerwert" SG_ 258 ESP_Gierrate 16383;
BA_ "GenSigSendType" SG_ 258 ESP_Gierrate 0;
BA_ "GenSigSwitchedByIgnition" SG_ 258 ESP_Gierrate 0;
BA_ "GenSigSendType" SG_ 258 ESP_HBA_aktiv 0;
BA_ "GenSigSwitchedByIgnition" SG_ 258 ESP_HBA_aktiv 0;
BA_ "GenSigSendType" SG_ 258 ESP_HDC_aktiv 0;
BA_ "GenSigSwitchedByIgnition" SG_ 258 ESP_HDC_aktiv 0;
BA_ "GenSigSendType" SG_ 258 ESP_HDC_Standby 0;
BA_ "GenSigSwitchedByIgnition" SG_ 258 ESP_HDC_Standby 0;
BA_ "GenSigSendType" SG_ 258 ESP_Konsistenz_ACC_Botschaft 0;
BA_ "GenSigSwitchedByIgnition" SG_ 258 ESP_Konsistenz_ACC_Botschaft 0;
BA_ "GenSigSendType" SG_ 258 ESP_Konsistenz_AWV2 0;
BA_ "GenSigSwitchedByIgnition" SG_ 258 ESP_Konsistenz_AWV2 0;
BA_ "GenSigSendType" SG_ 258 ESP_Konsistenz_TSK 0;
BA_ "GenSigSwitchedByIgnition" SG_ 258 ESP_Konsistenz_TSK 0;
BA_ "Fehlerwert" SG_ 258 ESP_Laengsbeschl 1023;
BA_ "GenSigSendType" SG_ 258 ESP_Laengsbeschl 0;
BA_ "GenSigStartValue" SG_ 258 ESP_Laengsbeschl 512;
BA_ "GenSigSwitchedByIgnition" SG_ 258 ESP_Laengsbeschl 0;
BA_ "GenSigSendType" SG_ 258 ESP_Lenkeingriff_ADS 0;
BA_ "GenSigSwitchedByIgnition" SG_ 258 ESP_Lenkeingriff_ADS 0;
BA_ "GenSigSendType" SG_ 258 ESP_Notbremsanzeige 0;
BA_ "GenSigSwitchedByIgnition" SG_ 258 ESP_Notbremsanzeige 0;
BA_ "GenSigSendType" SG_ 258 ESP_PLA_Abbruch 0;
BA_ "GenSigSwitchedByIgnition" SG_ 258 ESP_PLA_Abbruch 0;
BA_ "GenSigSendType" SG_ 258 ESP_Prefill_ausgeloest 0;
BA_ "GenSigSwitchedByIgnition" SG_ 258 ESP_Prefill_ausgeloest 0;
BA_ "GenSigSendType" SG_ 258 ESP_QBit_Bremsdruck 0;
BA_ "GenSigStartValue" SG_ 258 ESP_QBit_Bremsdruck 1;
BA_ "GenSigSwitchedByIgnition" SG_ 258 ESP_QBit_Bremsdruck 0;
BA_ "GenSigSendType" SG_ 258 ESP_QBit_Fahrer_bremst 0;
BA_ "GenSigStartValue" SG_ 258 ESP_QBit_Fahrer_bremst 1;
BA_ "GenSigSwitchedByIgnition" SG_ 258 ESP_QBit_Fahrer_bremst 0;
BA_ "GenSigSendType" SG_ 258 ESP_QBit_Gierrate 0;
BA_ "GenSigStartValue" SG_ 258 ESP_QBit_Gierrate 1;
BA_ "GenSigSwitchedByIgnition" SG_ 258 ESP_QBit_Gierrate 0;
BA_ "GenSigSendType" SG_ 258 ESP_QBit_Laengsbeschl 0;
BA_ "GenSigStartValue" SG_ 258 ESP_QBit_Laengsbeschl 1;
BA_ "GenSigSwitchedByIgnition" SG_ 258 ESP_QBit_Laengsbeschl 0;
BA_ "GenSigSendType" SG_ 258 ESP_QBit_Querb 0;
BA_ "GenSigStartValue" SG_ 258 ESP_QBit_Querb 1;
BA_ "GenSigSwitchedByIgnition" SG_ 258 ESP_QBit_Querb 0;
BA_ "GenSigSendType" SG_ 258 ESP_QBit_v_ref 0;
BA_ "GenSigStartValue" SG_ 258 ESP_QBit_v_ref 1;
BA_ "GenSigSwitchedByIgnition" SG_ 258 ESP_QBit_v_ref 0;
BA_ "Fehlerwert" SG_ 258 ESP_Querbeschleunigung 255;
BA_ "GenSigSendType" SG_ 258 ESP_Querbeschleunigung 0;
BA_ "GenSigStartValue" SG_ 258 ESP_Querbeschleunigung 127;
BA_ "GenSigSwitchedByIgnition" SG_ 258 ESP_Querbeschleunigung 0;
BA_ "GenSigSendType" SG_ 258 ESP_Rueckwaertsfahrt_erkannt 0;
BA_ "GenSigSwitchedByIgnition" SG_ 258 ESP_Rueckwaertsfahrt_erkannt 0;
BA_ "GenSigSendType" SG_ 258 ESP_Schwelle_Unterdruck 0;
BA_ "GenSigSwitchedByIgnition" SG_ 258 ESP_Schwelle_Unterdruck 0;
BA_ "GenSigSendType" SG_ 258 ESP_SpannungsAnf 0;
BA_ "GenSigSwitchedByIgnition" SG_ 258 ESP_SpannungsAnf 0;
BA_ "GenSigSendType" SG_ 258 ESP_StartStopp_Info 0;
BA_ "GenSigSwitchedByIgnition" SG_ 258 ESP_StartStopp_Info 0;
BA_ "GenSigSendType" SG_ 258 ESP_Status_Anfahrhilfe 0;
BA_ "GenSigSwitchedByIgnition" SG_ 258 ESP_Status_Anfahrhilfe 0;
BA_ "GenSigSendType" SG_ 258 ESP_Status_Bremsdruck 0;
BA_ "GenSigSwitchedByIgnition" SG_ 258 ESP_Status_Bremsdruck 0;
BA_ "GenSigSendType" SG_ 258 ESP_Status_Bremsentemp 0;
BA_ "GenSigSwitchedByIgnition" SG_ 258 ESP_Status_Bremsentemp 0;
BA_ "GenSigSendType" SG_ 258 ESP_Status_Bremsentemp_02 0;
BA_ "GenSigSwitchedByIgnition" SG_ 258 ESP_Status_Bremsentemp_02 0;
BA_ "GenSigSendType" SG_ 258 ESP_Status_ESP_PLA 0;
BA_ "GenSigSwitchedByIgnition" SG_ 258 ESP_Status_ESP_PLA 0;
BA_ "GenSigSendType" SG_ 258 ESP_Stillstandsphase_erschoepft 0;
BA_ "GenSigSwitchedByIgnition" SG_ 258 ESP_Stillstandsphase_erschoepft 0;
BA_ "Fehlerwert" SG_ 258 ESP_Systemstatus_03 3;
BA_ "GenSigSendType" SG_ 258 ESP_Systemstatus_03 0;
BA_ "GenSigStartValue" SG_ 258 ESP_Systemstatus_03 2;
BA_ "GenSigSwitchedByIgnition" SG_ 258 ESP_Systemstatus_03 0;
BA_ "GenSigSendType" SG_ 258 ESP_Tuerkontakt_Fahrertuer 0;
BA_ "GenSigSwitchedByIgnition" SG_ 258 ESP_Tuerkontakt_Fahrertuer 0;
BA_ "Fehlerwert" SG_ 258 ESP_v_ref 4095;
BA_ "GenSigSendType" SG_ 258 ESP_v_ref 0;
BA_ "GenSigStartValue" SG_ 258 ESP_v_ref 4094;
BA_ "GenSigSwitchedByIgnition" SG_ 258 ESP_v_ref 0;
BA_ "GenSigSendType" SG_ 258 ESP_v_ref_Fahrtrichtung 0;
BA_ "GenSigSwitchedByIgnition" SG_ 258 ESP_v_ref_Fahrtrichtung 0;
BA_ "GenSigSendType" SG_ 258 ESP_Verz_EPB_aktiv 0;
BA_ "GenSigSwitchedByIgnition" SG_ 258 ESP_Verz_EPB_aktiv 0;
BA_ "GenSigSendType" SG_ 258 ESP_Verz_TSK_aktiv 0;
BA_ "GenSigSwitchedByIgnition" SG_ 258 ESP_Verz_TSK_aktiv 0;
BA_ "GenSigSendType" SG_ 258 ESP_Verzoeg_EPB_verf 0;
BA_ "GenSigSwitchedByIgnition" SG_ 258 ESP_Verzoeg_EPB_verf 0;
BA_ "GenSigSendType" SG_ 258 ESP_VZ_Gierrate 0;
BA_ "GenSigSwitchedByIgnition" SG_ 258 ESP_VZ_Gierrate 0;
BA_ "GenSigSendType" SG_ 258 ESP_ZT_Rueckk_Umsetz 0;
BA_ "GenSigSwitchedByIgnition" SG_ 258 ESP_ZT_Rueckk_Umsetz 0;
BA_ "GenSigFuncType" SG_ 258 SOK_ESC_50_Signatur 15;
BA_ "GenSigSendType" SG_ 258 SOK_ESC_50_Signatur 0;
BA_ "GenSigSwitchedByIgnition" SG_ 258 SOK_ESC_50_Signatur 0;
BA_ "GenSigFuncType" SG_ 252 ESC_51_BZ 1;
BA_ "GenSigSendType" SG_ 252 ESC_51_BZ 0;
BA_ "GenSigSwitchedByIgnition" SG_ 252 ESC_51_BZ 0;
BA_ "GenSigFuncType" SG_ 252 ESC_51_CRC 2;
BA_ "GenSigSendType" SG_ 252 ESC_51_CRC 0;
BA_ "GenSigSwitchedByIgnition" SG_ 252 ESC_51_CRC 0;
BA_ "Fehlerwert" SG_ 252 ESC_Achsdrehzahl_Max 16383;
BA_ "GenSigSendType" SG_ 252 ESC_Achsdrehzahl_Max 0;
BA_ "GenSigStartValue" SG_ 252 ESC_Achsdrehzahl_Max 16382;
BA_ "GenSigSwitchedByIgnition" SG_ 252 ESC_Achsdrehzahl_Max 0;
BA_ "Fehlerwert" SG_ 252 ESC_Achsdrehzahl_Max_sek 16383;
BA_ "GenSigSendType" SG_ 252 ESC_Achsdrehzahl_Max_sek 0;
BA_ "GenSigStartValue" SG_ 252 ESC_Achsdrehzahl_Max_sek 16382;
BA_ "GenSigSwitchedByIgnition" SG_ 252 ESC_Achsdrehzahl_Max_sek 0;
BA_ "Fehlerwert" SG_ 252 ESC_Achsdrehzahl_Min 16383;
BA_ "GenSigSendType" SG_ 252 ESC_Achsdrehzahl_Min 0;
BA_ "GenSigStartValue" SG_ 252 ESC_Achsdrehzahl_Min 16382;
BA_ "GenSigSwitchedByIgnition" SG_ 252 ESC_Achsdrehzahl_Min 0;
BA_ "Fehlerwert" SG_ 252 ESC_Achsdrehzahl_Min_sek 16383;
BA_ "GenSigSendType" SG_ 252 ESC_Achsdrehzahl_Min_sek 0;
BA_ "GenSigStartValue" SG_ 252 ESC_Achsdrehzahl_Min_sek 16382;
BA_ "GenSigSwitchedByIgnition" SG_ 252 ESC_Achsdrehzahl_Min_sek 0;
BA_ "GenSigSendType" SG_ 252 ESC_aktBR_Modus_02 0;
BA_ "GenSigSwitchedByIgnition" SG_ 252 ESC_aktBR_Modus_02 0;
BA_ "GenSigSendType" SG_ 252 ESC_aktBr_Volumenstrom 0;
BA_ "GenSigStartValue" SG_ 252 ESC_aktBr_Volumenstrom 32256;
BA_ "GenSigSwitchedByIgnition" SG_ 252 ESC_aktBr_Volumenstrom 0;
BA_ "Fehlerwert" SG_ 252 ESC_Allrad_Anteil_max_sek 511;
BA_ "GenSigSendType" SG_ 252 ESC_Allrad_Anteil_max_sek 0;
BA_ "GenSigStartValue" SG_ 252 ESC_Allrad_Anteil_max_sek 510;
BA_ "GenSigSwitchedByIgnition" SG_ 252 ESC_Allrad_Anteil_max_sek 0;
BA_ "Fehlerwert" SG_ 252 ESC_Allrad_Anteil_min_sek 511;
BA_ "GenSigSendType" SG_ 252 ESC_Allrad_Anteil_min_sek 0;
BA_ "GenSigStartValue" SG_ 252 ESC_Allrad_Anteil_min_sek 510;
BA_ "GenSigSwitchedByIgnition" SG_ 252 ESC_Allrad_Anteil_min_sek 0;
BA_ "GenSigSendType" SG_ 252 ESC_Allradverteilung_aktiv 0;
BA_ "GenSigSwitchedByIgnition" SG_ 252 ESC_Allradverteilung_aktiv 0;
BA_ "GenSigSendType" SG_ 252 ESC_Anf_Mindestreku 0;
BA_ "GenSigSwitchedByIgnition" SG_ 252 ESC_Anf_Mindestreku 0;
BA_ "Fehlerwert" SG_ 252 ESC_Blending_Solldruck 1023;
BA_ "GenSigSendType" SG_ 252 ESC_Blending_Solldruck 0;
BA_ "GenSigStartValue" SG_ 252 ESC_Blending_Solldruck 1022;
BA_ "GenSigSwitchedByIgnition" SG_ 252 ESC_Blending_Solldruck 0;
BA_ "Fehlerwert" SG_ 252 ESC_Bremsdruck_02 1023;
BA_ "GenSigSendType" SG_ 252 ESC_Bremsdruck_02 0;
BA_ "GenSigStartValue" SG_ 252 ESC_Bremsdruck_02 100;
BA_ "GenSigSwitchedByIgnition" SG_ 252 ESC_Bremsdruck_02 0;
BA_ "Fehlerwert" SG_ 252 ESC_Bremsdruck_Modell 1023;
BA_ "GenSigSendType" SG_ 252 ESC_Bremsdruck_Modell 0;
BA_ "GenSigStartValue" SG_ 252 ESC_Bremsdruck_Modell 1022;
BA_ "GenSigSwitchedByIgnition" SG_ 252 ESC_Bremsdruck_Modell 0;
BA_ "GenSigSendType" SG_ 252 ESC_EBKV_Kraftblending_Modus 0;
BA_ "GenSigSwitchedByIgnition" SG_ 252 ESC_EBKV_Kraftblending_Modus 0;
BA_ "GenSigSendType" SG_ 252 ESC_GMV_aktiv 0;
BA_ "GenSigSwitchedByIgnition" SG_ 252 ESC_GMV_aktiv 0;
BA_ "GenSigSendType" SG_ 252 ESC_GMV_nicht_verfuegbar 0;
BA_ "GenSigStartValue" SG_ 252 ESC_GMV_nicht_verfuegbar 1;
BA_ "GenSigSwitchedByIgnition" SG_ 252 ESC_GMV_nicht_verfuegbar 0;
BA_ "Fehlerwert" SG_ 252 ESC_MomRad_Eingriff 8191;
BA_ "GenSigSendType" SG_ 252 ESC_MomRad_Eingriff 0;
BA_ "GenSigStartValue" SG_ 252 ESC_MomRad_Eingriff 8190;
BA_ "GenSigSwitchedByIgnition" SG_ 252 ESC_MomRad_Eingriff 0;
BA_ "Fehlerwert" SG_ 252 ESC_MomRad_Eingriff_sek 8191;
BA_ "GenSigSendType" SG_ 252 ESC_MomRad_Eingriff_sek 0;
BA_ "GenSigStartValue" SG_ 252 ESC_MomRad_Eingriff_sek 8190;
BA_ "GenSigSwitchedByIgnition" SG_ 252 ESC_MomRad_Eingriff_sek 0;
BA_ "GenSigSendType" SG_ 252 ESC_QBit_Bremsdruck_02 0;
BA_ "GenSigStartValue" SG_ 252 ESC_QBit_Bremsdruck_02 1;
BA_ "GenSigSwitchedByIgnition" SG_ 252 ESC_QBit_Bremsdruck_02 0;
BA_ "GenSigSendType" SG_ 252 ESC_Status_Eingriff 0;
BA_ "GenSigSwitchedByIgnition" SG_ 252 ESC_Status_Eingriff 0;
BA_ "GenSigSendType" SG_ 252 ESC_Status_Eingriff_sek 0;
BA_ "GenSigSwitchedByIgnition" SG_ 252 ESC_Status_Eingriff_sek 0;
BA_ "GenSigSendType" SG_ 252 ESC_Status_vRef_Stuetzeingriff 0;
BA_ "GenSigSwitchedByIgnition" SG_ 252 ESC_Status_vRef_Stuetzeingriff 0;
BA_ "Fehlerwert" SG_ 252 ESP_FDR_uebersteuern 255;
BA_ "GenSigSendType" SG_ 252 ESP_FDR_uebersteuern 0;
BA_ "GenSigStartValue" SG_ 252 ESP_FDR_uebersteuern 254;
BA_ "GenSigSwitchedByIgnition" SG_ 252 ESP_FDR_uebersteuern 0;
BA_ "Fehlerwert" SG_ 252 ESP_FDR_untersteuern 255;
BA_ "GenSigSendType" SG_ 252 ESP_FDR_untersteuern 0;
BA_ "GenSigStartValue" SG_ 252 ESP_FDR_untersteuern 254;
BA_ "GenSigSwitchedByIgnition" SG_ 252 ESP_FDR_untersteuern 0;
BA_ "Fehlerwert" SG_ 252 ESP_FZR_uebersteuern 255;
BA_ "GenSigMissingSourceValue" SG_ 252 ESP_FZR_uebersteuern 254;
BA_ "GenSigSendType" SG_ 252 ESP_FZR_uebersteuern 0;
BA_ "GenSigStartValue" SG_ 252 ESP_FZR_uebersteuern 254;
BA_ "GenSigSwitchedByIgnition" SG_ 252 ESP_FZR_uebersteuern 0;
BA_ "NWM-WakeupAllowed" SG_ 252 ESP_FZR_uebersteuern 1;
BA_ "Fehlerwert" SG_ 252 ESP_FZR_untersteuern 255;
BA_ "GenSigMissingSourceValue" SG_ 252 ESP_FZR_untersteuern 254;
BA_ "GenSigSendType" SG_ 252 ESP_FZR_untersteuern 0;
BA_ "GenSigStartValue" SG_ 252 ESP_FZR_untersteuern 254;
BA_ "GenSigSwitchedByIgnition" SG_ 252 ESP_FZR_untersteuern 0;
BA_ "NWM-WakeupAllowed" SG_ 252 ESP_FZR_untersteuern 1;
BA_ "Fehlerwert" SG_ 252 ESP_HL_Bremsmoment 255;
BA_ "GenSigSendType" SG_ 252 ESP_HL_Bremsmoment 0;
BA_ "GenSigStartValue" SG_ 252 ESP_HL_Bremsmoment 254;
BA_ "Fehlerwert" SG_ 252 ESP_HL_Radgeschw_02 65535;
BA_ "GenSigSendType" SG_ 252 ESP_HL_Radgeschw_02 0;
BA_ "GenSigStartValue" SG_ 252 ESP_HL_Radgeschw_02 65534;
BA_ "GenSigSwitchedByIgnition" SG_ 252 ESP_HL_Radgeschw_02 0;
BA_ "Fehlerwert" SG_ 252 ESP_HR_Bremsmoment 255;
BA_ "GenSigSendType" SG_ 252 ESP_HR_Bremsmoment 0;
BA_ "GenSigStartValue" SG_ 252 ESP_HR_Bremsmoment 254;
BA_ "Fehlerwert" SG_ 252 ESP_HR_Radgeschw_02 65535;
BA_ "GenSigSendType" SG_ 252 ESP_HR_Radgeschw_02 0;
BA_ "GenSigStartValue" SG_ 252 ESP_HR_Radgeschw_02 65534;
BA_ "GenSigSwitchedByIgnition" SG_ 252 ESP_HR_Radgeschw_02 0;
BA_ "Fehlerwert" SG_ 252 ESP_VL_Bremsmoment 255;
BA_ "GenSigSendType" SG_ 252 ESP_VL_Bremsmoment 0;
BA_ "GenSigStartValue" SG_ 252 ESP_VL_Bremsmoment 254;
BA_ "Fehlerwert" SG_ 252 ESP_VL_Radgeschw_02 65535;
BA_ "GenSigSendType" SG_ 252 ESP_VL_Radgeschw_02 0;
BA_ "GenSigStartValue" SG_ 252 ESP_VL_Radgeschw_02 65534;
BA_ "GenSigSwitchedByIgnition" SG_ 252 ESP_VL_Radgeschw_02 0;
BA_ "Fehlerwert" SG_ 252 ESP_VR_Bremsmoment 255;
BA_ "GenSigSendType" SG_ 252 ESP_VR_Bremsmoment 0;
BA_ "GenSigStartValue" SG_ 252 ESP_VR_Bremsmoment 254;
BA_ "Fehlerwert" SG_ 252 ESP_VR_Radgeschw_02 65535;
BA_ "GenSigSendType" SG_ 252 ESP_VR_Radgeschw_02 0;
BA_ "GenSigStartValue" SG_ 252 ESP_VR_Radgeschw_02 65534;
BA_ "GenSigSwitchedByIgnition" SG_ 252 ESP_VR_Radgeschw_02 0;
BA_ "GenSigSendType" SG_ 252 FDR_Allradverteilung_aktiv 0;
BA_ "GenSigSwitchedByIgnition" SG_ 252 FDR_Allradverteilung_aktiv 0;
BA_ "GenSigSendType" SG_ 252 FDR_Anf_Allradbetrieb 0;
BA_ "GenSigSwitchedByIgnition" SG_ 252 FDR_Anf_Allradbetrieb 0;
BA_ "GenSigFuncType" SG_ 252 SOK_ESC_51_Signatur 15;
BA_ "GenSigSendType" SG_ 252 SOK_ESC_51_Signatur 0;
BA_ "Fehlerwert" SG_ 252 TSMomBegrenzung 4095;
BA_ "GenSigSendType" SG_ 252 TSMomBegrenzung 0;
BA_ "GenSigStartValue" SG_ 252 TSMomBegrenzung 4094;
BA_ "GenSigSwitchedByIgnition" SG_ 252 TSMomBegrenzung 0;
BA_ "GenSigFuncType" SG_ 885 ESC_54_BZ 1;
BA_ "GenSigSendType" SG_ 885 ESC_54_BZ 0;
BA_ "GenSigSwitchedByIgnition" SG_ 885 ESC_54_BZ 0;
BA_ "GenSigFuncType" SG_ 885 SOK_ESC_54_Signatur 15;
BA_ "GenSigSendType" SG_ 885 SOK_ESC_54_Signatur 0;
BA_ "GenSigSwitchedByIgnition" SG_ 885 SOK_ESC_54_Signatur 0;
BA_ "GenSigSendType" SG_ 885 SSO_EdgeCount_Sum 0;
BA_ "GenSigSwitchedByIgnition" SG_ 885 SSO_EdgeCount_Sum 0;
BA_ "GenSigFuncType" SG_ 278 ESP_10_BZ 1;
BA_ "GenSigSendType" SG_ 278 ESP_10_BZ 0;
BA_ "GenSigSwitchedByIgnition" SG_ 278 ESP_10_BZ 0;
BA_ "GenSigFuncType" SG_ 278 ESP_10_CRC 2;
BA_ "GenSigSendType" SG_ 278 ESP_10_CRC 0;
BA_ "GenSigSwitchedByIgnition" SG_ 278 ESP_10_CRC 0;
BA_ "GenSigSendType" SG_ 278 ESP_HL_Fahrtrichtung 0;
BA_ "GenSigStartValue" SG_ 278 ESP_HL_Fahrtrichtung 2;
BA_ "GenSigSwitchedByIgnition" SG_ 278 ESP_HL_Fahrtrichtung 0;
BA_ "GenSigSendType" SG_ 278 ESP_HR_Fahrtrichtung 0;
BA_ "GenSigStartValue" SG_ 278 ESP_HR_Fahrtrichtung 2;
BA_ "GenSigSwitchedByIgnition" SG_ 278 ESP_HR_Fahrtrichtung 0;
BA_ "GenSigSendType" SG_ 278 ESP_QBit_Wegimpuls_HL 0;
BA_ "GenSigStartValue" SG_ 278 ESP_QBit_Wegimpuls_HL 1;
BA_ "GenSigSwitchedByIgnition" SG_ 278 ESP_QBit_Wegimpuls_HL 0;
BA_ "GenSigSendType" SG_ 278 ESP_QBit_Wegimpuls_HR 0;
BA_ "GenSigStartValue" SG_ 278 ESP_QBit_Wegimpuls_HR 1;
BA_ "GenSigSwitchedByIgnition" SG_ 278 ESP_QBit_Wegimpuls_HR 0;
BA_ "GenSigSendType" SG_ 278 ESP_QBit_Wegimpuls_VL 0;
BA_ "GenSigStartValue" SG_ 278 ESP_QBit_Wegimpuls_VL 1;
BA_ "GenSigSwitchedByIgnition" SG_ 278 ESP_QBit_Wegimpuls_VL 0;
BA_ "GenSigSendType" SG_ 278 ESP_QBit_Wegimpuls_VR 0;
BA_ "GenSigStartValue" SG_ 278 ESP_QBit_Wegimpuls_VR 1;
BA_ "GenSigSwitchedByIgnition" SG_ 278 ESP_QBit_Wegimpuls_VR 0;
BA_ "GenSigSendType" SG_ 278 ESP_VL_Fahrtrichtung 0;
BA_ "GenSigStartValue" SG_ 278 ESP_VL_Fahrtrichtung 2;
BA_ "GenSigSwitchedByIgnition" SG_ 278 ESP_VL_Fahrtrichtung 0;
BA_ "GenSigSendType" SG_ 278 ESP_VR_Fahrtrichtung 0;
BA_ "GenSigStartValue" SG_ 278 ESP_VR_Fahrtrichtung 2;
BA_ "GenSigSwitchedByIgnition" SG_ 278 ESP_VR_Fahrtrichtung 0;
BA_ "Fehlerwert" SG_ 278 ESP_Wegimpuls_HL 1023;
BA_ "GenSigSendType" SG_ 278 ESP_Wegimpuls_HL 0;
BA_ "GenSigStartValue" SG_ 278 ESP_Wegimpuls_HL 1021;
BA_ "GenSigSwitchedByIgnition" SG_ 278 ESP_Wegimpuls_HL 0;
BA_ "Fehlerwert" SG_ 278 ESP_Wegimpuls_HR 1023;
BA_ "GenSigSendType" SG_ 278 ESP_Wegimpuls_HR 0;
BA_ "GenSigStartValue" SG_ 278 ESP_Wegimpuls_HR 1021;
BA_ "GenSigSwitchedByIgnition" SG_ 278 ESP_Wegimpuls_HR 0;
BA_ "Fehlerwert" SG_ 278 ESP_Wegimpuls_VL 1023;
BA_ "GenSigSendType" SG_ 278 ESP_Wegimpuls_VL 0;
BA_ "GenSigStartValue" SG_ 278 ESP_Wegimpuls_VL 1021;
BA_ "GenSigSwitchedByIgnition" SG_ 278 ESP_Wegimpuls_VL 0;
BA_ "Fehlerwert" SG_ 278 ESP_Wegimpuls_VR 1023;
BA_ "GenSigSendType" SG_ 278 ESP_Wegimpuls_VR 0;
BA_ "GenSigStartValue" SG_ 278 ESP_Wegimpuls_VR 1021;
BA_ "GenSigSwitchedByIgnition" SG_ 278 ESP_Wegimpuls_VR 0;
BA_ "GenSigSendType" SG_ 1629 BR_QBit_Reifenumfang 0;
BA_ "GenSigStartValue" SG_ 1629 BR_QBit_Reifenumfang 1;
BA_ "GenSigSwitchedByIgnition" SG_ 1629 BR_QBit_Reifenumfang 0;
BA_ "GenSigSendType" SG_ 1629 BR_Reifenumfang 0;
BA_ "GenSigSwitchedByIgnition" SG_ 1629 BR_Reifenumfang 0;
BA_ "GenSigFuncType" SG_ 1629 BR_Systemart 8;
BA_ "GenSigSendType" SG_ 1629 BR_Systemart 0;
BA_ "GenSigSwitchedByIgnition" SG_ 1629 BR_Systemart 0;
BA_ "GenSigFuncType" SG_ 1629 ESP_20_BZ 1;
BA_ "GenSigSendType" SG_ 1629 ESP_20_BZ 0;
BA_ "GenSigSwitchedByIgnition" SG_ 1629 ESP_20_BZ 0;
BA_ "GenSigFuncType" SG_ 1629 ESP_20_CRC 2;
BA_ "GenSigSendType" SG_ 1629 ESP_20_CRC 0;
BA_ "GenSigSwitchedByIgnition" SG_ 1629 ESP_20_CRC 0;
BA_ "GenSigSendType" SG_ 1629 ESP_Charisma_FahrPr 3;
BA_ "GenSigSwitchedByIgnition" SG_ 1629 ESP_Charisma_FahrPr 0;
BA_ "GenSigSendType" SG_ 1629 ESP_Charisma_Status 3;
BA_ "GenSigSwitchedByIgnition" SG_ 1629 ESP_Charisma_Status 0;
BA_ "Fehlerwert" SG_ 1629 ESP_Dachrelingsensor 3;
BA_ "GenSigSendType" SG_ 1629 ESP_Dachrelingsensor 0;
BA_ "GenSigSwitchedByIgnition" SG_ 1629 ESP_Dachrelingsensor 0;
BA_ "GenSigSendType" SG_ 1629 ESP_SpannungsAnf_02 3;
BA_ "GenSigSwitchedByIgnition" SG_ 1629 ESP_SpannungsAnf_02 0;
BA_ "GenSigSendType" SG_ 1629 ESP_Stoppverbot_Anz_01 3;
BA_ "GenSigSwitchedByIgnition" SG_ 1629 ESP_Stoppverbot_Anz_01 0;
BA_ "GenSigSendType" SG_ 1629 ESP_Stoppverbot_Anz_02 3;
BA_ "GenSigSwitchedByIgnition" SG_ 1629 ESP_Stoppverbot_Anz_02 0;
BA_ "GenSigSendType" SG_ 1629 ESP_Stoppverbot_Anz_03 3;
BA_ "GenSigSwitchedByIgnition" SG_ 1629 ESP_Stoppverbot_Anz_03 0;
BA_ "GenSigSendType" SG_ 1629 ESP_Stoppverbot_Anz_04 3;
BA_ "GenSigSwitchedByIgnition" SG_ 1629 ESP_Stoppverbot_Anz_04 0;
BA_ "GenSigSendType" SG_ 1629 ESP_Stoppverbot_Anz_05 3;
BA_ "GenSigSwitchedByIgnition" SG_ 1629 ESP_Stoppverbot_Anz_05 0;
BA_ "GenSigSendType" SG_ 1629 ESP_Stoppverbot_Anz_06 3;
BA_ "GenSigSwitchedByIgnition" SG_ 1629 ESP_Stoppverbot_Anz_06 0;
BA_ "GenSigSendType" SG_ 1629 ESP_Stoppverbot_Anz_07 3;
BA_ "GenSigSwitchedByIgnition" SG_ 1629 ESP_Stoppverbot_Anz_07 0;
BA_ "GenSigSendType" SG_ 1629 ESP_Stoppverbot_Anz_08 3;
BA_ "GenSigSwitchedByIgnition" SG_ 1629 ESP_Stoppverbot_Anz_08 0;
BA_ "GenSigSendType" SG_ 1629 ESP_Stoppverbot_Anz_Std 3;
BA_ "GenSigSwitchedByIgnition" SG_ 1629 ESP_Stoppverbot_Anz_Std 0;
BA_ "GenSigSendType" SG_ 1629 ESP_Wiederstart_Anz_01 3;
BA_ "GenSigSwitchedByIgnition" SG_ 1629 ESP_Wiederstart_Anz_01 0;
BA_ "GenSigSendType" SG_ 1629 ESP_Wiederstart_Anz_02 3;
BA_ "GenSigSwitchedByIgnition" SG_ 1629 ESP_Wiederstart_Anz_02 0;
BA_ "GenSigSendType" SG_ 1629 ESP_Wiederstart_Anz_03 3;
BA_ "GenSigSwitchedByIgnition" SG_ 1629 ESP_Wiederstart_Anz_03 0;
BA_ "GenSigSendType" SG_ 1629 ESP_Wiederstart_Anz_04 3;
BA_ "GenSigSwitchedByIgnition" SG_ 1629 ESP_Wiederstart_Anz_04 0;
BA_ "GenSigFuncType" SG_ 1629 ESP_Zaehnezahl 8;
BA_ "GenSigSendType" SG_ 1629 ESP_Zaehnezahl 0;
BA_ "GenSigSwitchedByIgnition" SG_ 1629 ESP_Zaehnezahl 0;
BA_ "GenSigSendType" SG_ 1629 HDC_Charisma_FahrPr 3;
BA_ "GenSigSwitchedByIgnition" SG_ 1629 HDC_Charisma_FahrPr 0;
BA_ "GenSigSendType" SG_ 1629 HDC_Charisma_Status 3;
BA_ "GenSigSwitchedByIgnition" SG_ 1629 HDC_Charisma_Status 0;
BA_ "GenSigSendType" SG_ 253 ABS_Bremsung 0;
BA_ "GenSigSwitchedByIgnition" SG_ 253 ABS_Bremsung 0;
BA_ "GenSigSendType" SG_ 253 ASR_Anf 0;
BA_ "GenSigSwitchedByIgnition" SG_ 253 ASR_Anf 0;
BA_ "GenSigSendType" SG_ 253 ASR_Schalteingriff 0;
BA_ "GenSigSwitchedByIgnition" SG_ 253 ASR_Schalteingriff 0;
BA_ "GenSigSendType" SG_ 253 ASR_Tastung_passiv 0;
BA_ "GenSigSwitchedByIgnition" SG_ 253 ASR_Tastung_passiv 0;
BA_ "Fehlerwert" SG_ 253 BR_Eingriffsmoment 1023;
BA_ "GenSigSendType" SG_ 253 BR_Eingriffsmoment 0;
BA_ "GenSigStartValue" SG_ 253 BR_Eingriffsmoment 1022;
BA_ "GenSigSwitchedByIgnition" SG_ 253 BR_Eingriffsmoment 0;
BA_ "GenSigSendType" SG_ 253 EBV_Eingriff 0;
BA_ "GenSigSwitchedByIgnition" SG_ 253 EBV_Eingriff 0;
BA_ "GenSigSendType" SG_ 253 EDS_Eingriff 0;
BA_ "GenSigSwitchedByIgnition" SG_ 253 EDS_Eingriff 0;
BA_ "GenSigSendType" SG_ 253 ESC_Reku_Freigabe 0;
BA_ "GenSigSwitchedByIgnition" SG_ 253 ESC_Reku_Freigabe 0;
BA_ "Fehlerwert" SG_ 253 ESC_v_Signal_Qualifier_High_Low 7;
BA_ "GenSigSendType" SG_ 253 ESC_v_Signal_Qualifier_High_Low 0;
BA_ "GenSigStartValue" SG_ 253 ESC_v_Signal_Qualifier_High_Low 6;
BA_ "GenSigSwitchedByIgnition" SG_ 253 ESC_v_Signal_Qualifier_High_Low 0;
BA_ "GenSigFuncType" SG_ 253 ESP_21_BZ 1;
BA_ "GenSigSendType" SG_ 253 ESP_21_BZ 0;
BA_ "GenSigSwitchedByIgnition" SG_ 253 ESP_21_BZ 0;
BA_ "GenSigFuncType" SG_ 253 ESP_21_CRC 2;
BA_ "GenSigSendType" SG_ 253 ESP_21_CRC 0;
BA_ "GenSigSwitchedByIgnition" SG_ 253 ESP_21_CRC 0;
BA_ "GenSigSendType" SG_ 253 ESP_Anhaltevorgang_ACC_aktiv 0;
BA_ "GenSigSwitchedByIgnition" SG_ 253 ESP_Anhaltevorgang_ACC_aktiv 0;
BA_ "GenSigSendType" SG_ 253 ESP_ASP 0;
BA_ "GenSigSwitchedByIgnition" SG_ 253 ESP_ASP 0;
BA_ "GenSigSendType" SG_ 253 ESP_AWV3_Brems_aktiv 0;
BA_ "GenSigSwitchedByIgnition" SG_ 253 ESP_AWV3_Brems_aktiv 0;
BA_ "GenSigSendType" SG_ 253 ESP_Diagnose 0;
BA_ "GenSigSwitchedByIgnition" SG_ 253 ESP_Diagnose 0;
BA_ "GenSigSendType" SG_ 253 ESP_Eingriff 0;
BA_ "GenSigSwitchedByIgnition" SG_ 253 ESP_Eingriff 0;
BA_ "GenSigSendType" SG_ 253 ESP_Haltebestaetigung 0;
BA_ "GenSigSwitchedByIgnition" SG_ 253 ESP_Haltebestaetigung 0;
BA_ "GenSigSendType" SG_ 253 ESP_MKB_Abbruch_Geschw 0;
BA_ "GenSigSwitchedByIgnition" SG_ 253 ESP_MKB_Abbruch_Geschw 0;
BA_ "GenSigSendType" SG_ 253 ESP_PLA_Bremseingriff 0;
BA_ "GenSigSwitchedByIgnition" SG_ 253 ESP_PLA_Bremseingriff 0;
BA_ "GenSigSendType" SG_ 253 ESP_QBit_v_Signal 0;
BA_ "GenSigStartValue" SG_ 253 ESP_QBit_v_Signal 1;
BA_ "GenSigSwitchedByIgnition" SG_ 253 ESP_QBit_v_Signal 0;
BA_ "GenSigSendType" SG_ 253 ESP_Systemstatus 0;
BA_ "GenSigSwitchedByIgnition" SG_ 253 ESP_Systemstatus 0;
BA_ "GenSigSendType" SG_ 253 ESP_Tastung_passiv 0;
BA_ "GenSigSwitchedByIgnition" SG_ 253 ESP_Tastung_passiv 0;
BA_ "Fehlerwert" SG_ 253 ESP_v_Signal 65535;
BA_ "GenSigMissingSourceValue" SG_ 253 ESP_v_Signal 65534;
BA_ "GenSigSendType" SG_ 253 ESP_v_Signal 0;
BA_ "GenSigStartValue" SG_ 253 ESP_v_Signal 65534;
BA_ "GenSigSwitchedByIgnition" SG_ 253 ESP_v_Signal 0;
BA_ "GenSigSendType" SG_ 253 ESP_Vorsteuerung 0;
BA_ "GenSigSwitchedByIgnition" SG_ 253 ESP_Vorsteuerung 0;
BA_ "GenSigSendType" SG_ 253 MSR_Anf 0;
BA_ "GenSigSwitchedByIgnition" SG_ 253 MSR_Anf 0;
BA_ "GenSigSendType" SG_ 253 OBD_QBit_Schlechtweg 0;
BA_ "GenSigStartValue" SG_ 253 OBD_QBit_Schlechtweg 1;
BA_ "GenSigSwitchedByIgnition" SG_ 253 OBD_QBit_Schlechtweg 0;
BA_ "GenSigSendType" SG_ 253 OBD_Schlechtweg 0;
BA_ "GenSigSwitchedByIgnition" SG_ 253 OBD_Schlechtweg 0;
BA_ "GenSigSendType" SG_ 795 ABS_Lampe 0;
BA_ "GenSigStartValue" SG_ 795 ABS_Lampe 1;
BA_ "GenSigSwitchedByIgnition" SG_ 795 ABS_Lampe 0;
BA_ "GenSigSendType" SG_ 795 BK_Lampe_02 0;
BA_ "GenSigStartValue" SG_ 795 BK_Lampe_02 1;
BA_ "GenSigSwitchedByIgnition" SG_ 795 BK_Lampe_02 0;
BA_ "GenSigFuncType" SG_ 795 ESP_24_BZ 1;
BA_ "GenSigSendType" SG_ 795 ESP_24_BZ 0;
BA_ "GenSigSwitchedByIgnition" SG_ 795 ESP_24_BZ 0;
BA_ "GenSigFuncType" SG_ 795 ESP_24_CRC 2;
BA_ "GenSigSendType" SG_ 795 ESP_24_CRC 0;
BA_ "GenSigSwitchedByIgnition" SG_ 795 ESP_24_CRC 0;
BA_ "GenSigSendType" SG_ 795 ESP_BKV_Warnung 0;
BA_ "GenSigSwitchedByIgnition" SG_ 795 ESP_BKV_Warnung 0;
BA_ "GenSigSendType" SG_ 795 ESP_Fehlerstatus_Wegimp 0;
BA_ "GenSigSwitchedByIgnition" SG_ 795 ESP_Fehlerstatus_Wegimp 0;
BA_ "GenSigSendType" SG_ 795 ESP_HDC_FktLampe 0;
BA_ "GenSigSwitchedByIgnition" SG_ 795 ESP_HDC_FktLampe 0;
BA_ "Fehlerwert" SG_ 795 ESP_HDC_Regelgeschw 127;
BA_ "GenSigSendType" SG_ 795 ESP_HDC_Regelgeschw 0;
BA_ "GenSigStartValue" SG_ 795 ESP_HDC_Regelgeschw 126;
BA_ "GenSigSwitchedByIgnition" SG_ 795 ESP_HDC_Regelgeschw 0;
BA_ "GenSigSendType" SG_ 795 ESP_Lampe 0;
BA_ "GenSigStartValue" SG_ 795 ESP_Lampe 1;
BA_ "GenSigSwitchedByIgnition" SG_ 795 ESP_Lampe 0;
BA_ "Fehlerwert" SG_ 795 ESP_m_Raddrehz 32767;
BA_ "GenSigSendType" SG_ 795 ESP_m_Raddrehz 0;
BA_ "GenSigStartValue" SG_ 795 ESP_m_Raddrehz 32766;
BA_ "GenSigSwitchedByIgnition" SG_ 795 ESP_m_Raddrehz 0;
BA_ "GenSigSendType" SG_ 795 ESP_Meldungen 0;
BA_ "GenSigSwitchedByIgnition" SG_ 795 ESP_Meldungen 0;
BA_ "GenSigSendType" SG_ 795 ESP_Off_Lampe 0;
BA_ "GenSigSwitchedByIgnition" SG_ 795 ESP_Off_Lampe 0;
BA_ "GenSigSendType" SG_ 795 ESP_QBit_Wegimp_VA 0;
BA_ "GenSigStartValue" SG_ 795 ESP_QBit_Wegimp_VA 1;
BA_ "GenSigSwitchedByIgnition" SG_ 795 ESP_QBit_Wegimp_VA 0;
BA_ "GenSigSendType" SG_ 795 ESP_Textanzeigen_03 0;
BA_ "GenSigSwitchedByIgnition" SG_ 795 ESP_Textanzeigen_03 0;
BA_ "GenSigSendType" SG_ 795 ESP_Wegimp_Ueberlauf 0;
BA_ "GenSigSwitchedByIgnition" SG_ 795 ESP_Wegimp_Ueberlauf 0;
BA_ "GenSigSendType" SG_ 795 ESP_Wegimp_VA 0;
BA_ "GenSigSwitchedByIgnition" SG_ 795 ESP_Wegimp_VA 0;
BA_ "GenSigSendType" SG_ 795 TC_Lampe 0;
BA_ "GenSigSwitchedByIgnition" SG_ 795 TC_Lampe 0;
BA_REL_ "GenSigTimeoutTime" BU_SG_REL_ Fahrerdisplay_Kombi SG_ 253 ESP_QBit_v_Signal 500;
BA_REL_ "GenSigTimeoutTime" BU_SG_REL_ Fahrerdisplay_Kombi SG_ 253 ESP_v_Signal 500;
BA_REL_ "GenSigTimeoutTime" BU_SG_REL_ Fahrerdisplay_Kombi SG_ 503 EPB_03_BZ 2000;
BA_REL_ "GenSigTimeoutTime" BU_SG_REL_ Fahrerdisplay_Kombi SG_ 503 EPB_03_CRC 2000;
BA_REL_ "GenSigTimeoutTime" BU_SG_REL_ Fahrerdisplay_Kombi SG_ 503 EPB_Autoholdlampe_02 2000;
BA_REL_ "GenSigTimeoutTime" BU_SG_REL_ Fahrerdisplay_Kombi SG_ 503 EPB_Fehlermeldungen_02 2000;
BA_REL_ "GenSigTimeoutTime" BU_SG_REL_ Fahrerdisplay_Kombi SG_ 503 EPB_Funktionslampe_02 2000;
BA_REL_ "GenSigTimeoutTime" BU_SG_REL_ Fahrerdisplay_Kombi SG_ 503 EPB_Texte_02 2000;
BA_REL_ "GenSigTimeoutTime" BU_SG_REL_ Fahrerdisplay_Kombi SG_ 795 ABS_Lampe 500;
BA_REL_ "GenSigTimeoutTime" BU_SG_REL_ Fahrerdisplay_Kombi SG_ 795 BK_Lampe_02 500;
BA_REL_ "GenSigTimeoutTime" BU_SG_REL_ Fahrerdisplay_Kombi SG_ 795 ESP_24_BZ 500;
BA_REL_ "GenSigTimeoutTime" BU_SG_REL_ Fahrerdisplay_Kombi SG_ 795 ESP_24_CRC 500;
BA_REL_ "GenSigTimeoutTime" BU_SG_REL_ Fahrerdisplay_Kombi SG_ 795 ESP_BKV_Warnung 500;
BA_REL_ "GenSigTimeoutTime" BU_SG_REL_ Fahrerdisplay_Kombi SG_ 795 ESP_Lampe 500;
BA_REL_ "GenSigTimeoutTime" BU_SG_REL_ Fahrerdisplay_Kombi SG_ 795 ESP_Meldungen 500;
BA_REL_ "GenSigTimeoutTime" BU_SG_REL_ Fahrerdisplay_Kombi SG_ 795 ESP_Off_Lampe 500;
BA_REL_ "GenSigTimeoutTime" BU_SG_REL_ Fahrerdisplay_Kombi SG_ 1520 DI_Display_Nachtdesign 2000;
BA_REL_ "GenSigTimeoutTime" BU_SG_REL_ Fahrerdisplay_Kombi SG_ 1520 DI_KL_58xd 2000;
BA_REL_ "GenSigTimeoutTime" BU_SG_REL_ Fahrerdisplay_Kombi SG_ 1520 DI_KL_58xs 2000;
BA_REL_ "GenSigTimeoutTime" BU_SG_REL_ Fahrerdisplay_Kombi SG_ 1520 DI_KL_58xt 2000;
BA_REL_ "GenSigTimeoutTime" BU_SG_REL_ HUD SG_ 253 ESC_v_Signal_Qualifier_High_Low 500;
BA_REL_ "GenSigTimeoutTime" BU_SG_REL_ HUD SG_ 253 ESP_21_BZ 500;
BA_REL_ "GenSigTimeoutTime" BU_SG_REL_ HUD SG_ 253 ESP_21_CRC 500;
BA_REL_ "GenSigTimeoutTime" BU_SG_REL_ HUD SG_ 253 ESP_QBit_v_Signal 500;
BA_REL_ "GenSigTimeoutTime" BU_SG_REL_ HUD SG_ 253 ESP_v_Signal 500;
BA_REL_ "GenSigTimeoutTime" BU_SG_REL_ HUD SG_ 1520 BCM1_Stellgroesse_Kl_58s 2000;
BA_REL_ "GenSigTimeoutTime" BU_SG_REL_ HUD SG_ 1520 DI_Display_Nachtdesign 2000;
BA_REL_ "GenSigTimeoutTime" BU_SG_REL_ HUD SG_ 1520 DI_KL_58xd 2000;
BA_REL_ "GenSigTimeoutTime" BU_SG_REL_ HUD SG_ 1520 DI_KL_58xs 2000;
BA_REL_ "GenSigTimeoutTime" BU_SG_REL_ HUD SG_ 1520 DI_KL_58xt 2000;
BA_REL_ "GenSigTimeoutTime" BU_SG_REL_ ICAS1_X_Gateway SG_ 2527679674 DispKBI_FS_Systemstatus 5000;
BA_REL_ "GenSigTimeoutTime" BU_SG_REL_ ICAS3_Gateway SG_ 253 ESP_QBit_v_Signal 500;
BA_REL_ "GenSigTimeoutTime" BU_SG_REL_ ICAS3_Gateway SG_ 253 ESP_v_Signal 500;
BA_REL_ "GenSigTimeoutTime" BU_SG_REL_ ICAS3_Gateway SG_ 258 ESP_Gierrate 500;
BA_REL_ "GenSigTimeoutTime" BU_SG_REL_ ICAS3_Gateway SG_ 258 ESP_Laengsbeschl 500;
BA_REL_ "GenSigTimeoutTime" BU_SG_REL_ ICAS3_Gateway SG_ 258 ESP_QBit_Gierrate 500;
BA_REL_ "GenSigTimeoutTime" BU_SG_REL_ ICAS3_Gateway SG_ 258 ESP_QBit_Laengsbeschl 500;
BA_REL_ "GenSigTimeoutTime" BU_SG_REL_ ICAS3_Gateway SG_ 258 ESP_QBit_Querb 500;
BA_REL_ "GenSigTimeoutTime" BU_SG_REL_ ICAS3_Gateway SG_ 258 ESP_Querbeschleunigung 500;
BA_REL_ "GenSigTimeoutTime" BU_SG_REL_ ICAS3_Gateway SG_ 258 ESP_VZ_Gierrate 500;
BA_REL_ "GenSigTimeoutTime" BU_SG_REL_ ICAS3_Gateway SG_ 278 ESP_10_BZ 500;
BA_REL_ "GenSigTimeoutTime" BU_SG_REL_ ICAS3_Gateway SG_ 278 ESP_HL_Fahrtrichtung 500;
BA_REL_ "GenSigTimeoutTime" BU_SG_REL_ ICAS3_Gateway SG_ 278 ESP_HR_Fahrtrichtung 500;
BA_REL_ "GenSigTimeoutTime" BU_SG_REL_ ICAS3_Gateway SG_ 278 ESP_QBit_Wegimpuls_HL 500;
BA_REL_ "GenSigTimeoutTime" BU_SG_REL_ ICAS3_Gateway SG_ 278 ESP_QBit_Wegimpuls_HR 500;
BA_REL_ "GenSigTimeoutTime" BU_SG_REL_ ICAS3_Gateway SG_ 278 ESP_QBit_Wegimpuls_VL 500;
BA_REL_ "GenSigTimeoutTime" BU_SG_REL_ ICAS3_Gateway SG_ 278 ESP_QBit_Wegimpuls_VR 500;
BA_REL_ "GenSigTimeoutTime" BU_SG_REL_ ICAS3_Gateway SG_ 278 ESP_VL_Fahrtrichtung 500;
BA_REL_ "GenSigTimeoutTime" BU_SG_REL_ ICAS3_Gateway SG_ 278 ESP_VR_Fahrtrichtung 500;
BA_REL_ "GenSigTimeoutTime" BU_SG_REL_ ICAS3_Gateway SG_ 278 ESP_Wegimpuls_HL 500;
BA_REL_ "GenSigTimeoutTime" BU_SG_REL_ ICAS3_Gateway SG_ 278 ESP_Wegimpuls_HR 500;
BA_REL_ "GenSigTimeoutTime" BU_SG_REL_ ICAS3_Gateway SG_ 278 ESP_Wegimpuls_VL 500;
BA_REL_ "GenSigTimeoutTime" BU_SG_REL_ ICAS3_Gateway SG_ 278 ESP_Wegimpuls_VR 500;
BA_REL_ "GenSigTimeoutTime" BU_SG_REL_ ICAS3_Gateway SG_ 496 EA_Infotainment_Anf 5000;
BA_REL_ "GenSigTimeoutTime" BU_SG_REL_ ICAS3_Gateway SG_ 496 EA_Status_HMI 5000;
BA_REL_ "GenSigTimeoutTime" BU_SG_REL_ ICAS3_Gateway SG_ 503 EPB_Parkanzeige 2000;
BA_REL_ "GenSigTimeoutTime" BU_SG_REL_ ICAS3_Gateway SG_ 608 EML_AnzeigeGeschw 500;
BA_REL_ "GenSigTimeoutTime" BU_SG_REL_ ICAS3_Gateway SG_ 795 ESP_Fehlerstatus_Wegimp 500;
BA_REL_ "GenSigTimeoutTime" BU_SG_REL_ ICAS3_Gateway SG_ 795 ESP_QBit_Wegimp_VA 500;
BA_REL_ "GenSigTimeoutTime" BU_SG_REL_ ICAS3_Gateway SG_ 795 ESP_Wegimp_Ueberlauf 500;
BA_REL_ "GenSigTimeoutTime" BU_SG_REL_ ICAS3_Gateway SG_ 795 ESP_Wegimp_VA 500;
BA_REL_ "GenSigTimeoutTime" BU_SG_REL_ ICAS3_Gateway SG_ 851 DiETa_Car 500;
BA_REL_ "GenSigTimeoutTime" BU_SG_REL_ ICAS3_Gateway SG_ 851 DiETa_Touch_Event 500;
BA_REL_ "GenSigTimeoutTime" BU_SG_REL_ ICAS3_Gateway SG_ 885 ESC_54_BZ 500;
BA_REL_ "GenSigTimeoutTime" BU_SG_REL_ ICAS3_Gateway SG_ 885 SOK_ESC_54_Signatur 500;
BA_REL_ "GenSigTimeoutTime" BU_SG_REL_ ICAS3_Gateway SG_ 885 SSO_EdgeCount_Sum 500;
BA_REL_ "GenSigTimeoutTime" BU_SG_REL_ ICAS3_Gateway SG_ 1520 DI_Display_Nachtdesign 2000;
BA_REL_ "GenSigTimeoutTime" BU_SG_REL_ ICAS3_Gateway SG_ 1520 DI_KL_58xd 2000;
BA_REL_ "GenSigTimeoutTime" BU_SG_REL_ ICAS3_Gateway SG_ 1520 DI_KL_58xs 2000;
BA_REL_ "GenSigTimeoutTime" BU_SG_REL_ ICAS3_Gateway SG_ 1520 DI_KL_58xt 2000;
BA_REL_ "GenSigTimeoutTime" BU_SG_REL_ ICAS3_Gateway SG_ 1629 BR_Reifenumfang 5000;
BA_REL_ "GenSigTimeoutTime" BU_SG_REL_ ICAS3_Gateway SG_ 1629 ESP_Zaehnezahl 5000;
BA_REL_ "GenSigTimeoutTime" BU_SG_REL_ ICAS3_Gateway SG_ 2331595989 DIST_DKmtg 500;
BA_REL_ "GenSigTimeoutTime" BU_SG_REL_ ICAS3_Gateway SG_ 2589283970 DIST_DKmtg_Auth 5000;
BA_REL_ "GenSigTimeoutTime" BU_SG_REL_ ICAS3_Gateway SG_ 2589283970 SOK_Entfernung_02_Signatur 5000;
BA_REL_ "GenSigTimeoutTime" BU_SG_REL_ ICC_IO_Node SG_ 253 ESP_QBit_v_Signal 500;
BA_REL_ "GenSigTimeoutTime" BU_SG_REL_ ICC_IO_Node SG_ 253 ESP_v_Signal 500;
BA_REL_ "GenSigTimeoutTime" BU_SG_REL_ Kombi SG_ 252 ESC_Anf_Mindestreku 500;
BA_REL_ "GenSigTimeoutTime" BU_SG_REL_ Kombi SG_ 253 ESP_v_Signal 500;
BA_REL_ "GenSigTimeoutTime" BU_SG_REL_ Kombi SG_ 258 ESP_Laengsbeschl 500;
BA_REL_ "GenSigTimeoutTime" BU_SG_REL_ Kombi SG_ 258 ESP_QBit_Laengsbeschl 500;
BA_REL_ "GenSigTimeoutTime" BU_SG_REL_ Kombi SG_ 258 ESP_QBit_Querb 500;
BA_REL_ "GenSigTimeoutTime" BU_SG_REL_ Kombi SG_ 258 ESP_Querbeschleunigung 500;
BA_REL_ "GenSigTimeoutTime" BU_SG_REL_ Kombi SG_ 496 EA_Texte 5000;
BA_REL_ "GenSigTimeoutTime" BU_SG_REL_ Kombi SG_ 496 EA_eCall_Anf 5000;
BA_REL_ "GenSigTimeoutTime" BU_SG_REL_ Kombi SG_ 503 EPB_03_BZ 2000;
BA_REL_ "GenSigTimeoutTime" BU_SG_REL_ Kombi SG_ 503 EPB_03_CRC 2000;
BA_REL_ "GenSigTimeoutTime" BU_SG_REL_ Kombi SG_ 503 EPB_Autohold_Standbyanzeige 2000;
BA_REL_ "GenSigTimeoutTime" BU_SG_REL_ Kombi SG_ 503 EPB_Autoholdlampe_02 2000;
BA_REL_ "GenSigTimeoutTime" BU_SG_REL_ Kombi SG_ 503 EPB_Fehlermeldungen_02 2000;
BA_REL_ "GenSigTimeoutTime" BU_SG_REL_ Kombi SG_ 503 EPB_Funktionslampe_02 2000;
BA_REL_ "GenSigTimeoutTime" BU_SG_REL_ Kombi SG_ 503 EPB_Parkanzeige 2000;
BA_REL_ "GenSigTimeoutTime" BU_SG_REL_ Kombi SG_ 503 EPB_Texte_02 2000;
BA_REL_ "GenSigTimeoutTime" BU_SG_REL_ Kombi SG_ 608 EML_AnzeigeGeschw 500;
BA_REL_ "GenSigTimeoutTime" BU_SG_REL_ Kombi SG_ 795 ABS_Lampe 500;
BA_REL_ "GenSigTimeoutTime" BU_SG_REL_ Kombi SG_ 795 BK_Lampe_02 500;
BA_REL_ "GenSigTimeoutTime" BU_SG_REL_ Kombi SG_ 795 ESP_24_BZ 500;
BA_REL_ "GenSigTimeoutTime" BU_SG_REL_ Kombi SG_ 795 ESP_24_CRC 500;
BA_REL_ "GenSigTimeoutTime" BU_SG_REL_ Kombi SG_ 795 ESP_BKV_Warnung 500;
BA_REL_ "GenSigTimeoutTime" BU_SG_REL_ Kombi SG_ 795 ESP_Lampe 500;
BA_REL_ "GenSigTimeoutTime" BU_SG_REL_ Kombi SG_ 795 ESP_Meldungen 500;
BA_REL_ "GenSigTimeoutTime" BU_SG_REL_ Kombi SG_ 795 ESP_Off_Lampe 500;
BA_REL_ "GenSigTimeoutTime" BU_SG_REL_ Kombi SG_ 795 ESP_Textanzeigen_03 500;
BA_REL_ "GenSigTimeoutTime" BU_SG_REL_ Kombi SG_ 795 ESP_Wegimp_Ueberlauf 500;
BA_REL_ "GenSigTimeoutTime" BU_SG_REL_ Kombi SG_ 795 ESP_Wegimp_VA 500;
BA_REL_ "GenSigTimeoutTime" BU_SG_REL_ Kombi SG_ 795 ESP_m_Raddrehz 500;
BA_REL_ "GenSigTimeoutTime" BU_SG_REL_ Kombi SG_ 885 ESC_54_BZ 500;
BA_REL_ "GenSigTimeoutTime" BU_SG_REL_ Kombi SG_ 885 SOK_ESC_54_Signatur 500;
BA_REL_ "GenSigTimeoutTime" BU_SG_REL_ Kombi SG_ 885 SSO_EdgeCount_Sum 500;
BA_REL_ "GenSigTimeoutTime" BU_SG_REL_ Kombi SG_ 1520 DI_Display_Nachtdesign 2000;
BA_REL_ "GenSigTimeoutTime" BU_SG_REL_ Kombi SG_ 1520 DI_KL_58xd 2000;
BA_REL_ "GenSigTimeoutTime" BU_SG_REL_ Kombi SG_ 1520 DI_KL_58xs 2000;
BA_REL_ "GenSigTimeoutTime" BU_SG_REL_ Kombi SG_ 1520 DI_KL_58xt 2000;
BA_REL_ "GenSigTimeoutTime" BU_SG_REL_ Kombi SG_ 1622 ELV_Entriegelt 5000;
BA_REL_ "GenSigTimeoutTime" BU_SG_REL_ Kombi SG_ 1622 ELV_LED_Rot 5000;
BA_REL_ "GenSigTimeoutTime" BU_SG_REL_ Kombi SG_ 1622 ELV_Txt_Defekt 5000;
BA_REL_ "GenSigTimeoutTime" BU_SG_REL_ Kombi SG_ 1622 ELV_Txt_Lkg_Bewegen 5000;
BA_REL_ "GenSigTimeoutTime" BU_SG_REL_ Kombi SG_ 1622 ELV_Txt_Werkstatt 5000;
BA_REL_ "GenSigTimeoutTime" BU_SG_REL_ Kombi SG_ 1622 ELV_Verriegelt 5000;
BA_REL_ "GenSigTimeoutTime" BU_SG_REL_ Kombi SG_ 1629 ESP_Zaehnezahl 5000;
BA_REL_ "GenSigTimeoutTime" BU_SG_REL_ Kombi SG_ 2331595989 DIST_DKmtg 500;
BA_REL_ "GenSigTimeoutTime" BU_SG_REL_ Kombi SG_ 2589283751 KBI_Kilometerstand_HiRes_meter 5000;
BA_REL_ "GenSigTimeoutTime" BU_SG_REL_ Kombi SG_ 2589283970 DIST_DKmtg_Auth 5000;
BA_REL_ "GenSigTimeoutTime" BU_SG_REL_ Kombi SG_ 2589283970 SOK_Entfernung_02_Signatur 5000;
BA_REL_ "GenSigTimeoutTime" BU_SG_REL_ SmartLight_01 SG_ 253 ESP_v_Signal 500;
BA_REL_ "GenSigTimeoutTime" BU_SG_REL_ ZR_MIB_TOP_ab_Gen3 SG_ 252 ESP_HL_Radgeschw_02 500;
BA_REL_ "GenSigTimeoutTime" BU_SG_REL_ ZR_MIB_TOP_ab_Gen3 SG_ 252 ESP_HR_Radgeschw_02 500;
BA_REL_ "GenSigTimeoutTime" BU_SG_REL_ ZR_MIB_TOP_ab_Gen3 SG_ 252 ESP_VL_Radgeschw_02 500;
BA_REL_ "GenSigTimeoutTime" BU_SG_REL_ ZR_MIB_TOP_ab_Gen3 SG_ 252 ESP_VR_Radgeschw_02 500;
BA_REL_ "GenSigTimeoutTime" BU_SG_REL_ ZR_MIB_TOP_ab_Gen3 SG_ 253 ESP_QBit_v_Signal 500;
BA_REL_ "GenSigTimeoutTime" BU_SG_REL_ ZR_MIB_TOP_ab_Gen3 SG_ 253 ESP_v_Signal 500;
BA_REL_ "GenSigTimeoutTime" BU_SG_REL_ ZR_MIB_TOP_ab_Gen3 SG_ 258 ESP_Bremsdruck 500;
BA_REL_ "GenSigTimeoutTime" BU_SG_REL_ ZR_MIB_TOP_ab_Gen3 SG_ 258 ESP_Eingr_HL 500;
BA_REL_ "GenSigTimeoutTime" BU_SG_REL_ ZR_MIB_TOP_ab_Gen3 SG_ 258 ESP_Eingr_HR 500;
BA_REL_ "GenSigTimeoutTime" BU_SG_REL_ ZR_MIB_TOP_ab_Gen3 SG_ 258 ESP_Eingr_VL 500;
BA_REL_ "GenSigTimeoutTime" BU_SG_REL_ ZR_MIB_TOP_ab_Gen3 SG_ 258 ESP_Eingr_VR 500;
BA_REL_ "GenSigTimeoutTime" BU_SG_REL_ ZR_MIB_TOP_ab_Gen3 SG_ 258 ESP_Gierrate 500;
BA_REL_ "GenSigTimeoutTime" BU_SG_REL_ ZR_MIB_TOP_ab_Gen3 SG_ 258 ESP_Laengsbeschl 500;
BA_REL_ "GenSigTimeoutTime" BU_SG_REL_ ZR_MIB_TOP_ab_Gen3 SG_ 258 ESP_QBit_Gierrate 500;
BA_REL_ "GenSigTimeoutTime" BU_SG_REL_ ZR_MIB_TOP_ab_Gen3 SG_ 258 ESP_QBit_Laengsbeschl 500;
BA_REL_ "GenSigTimeoutTime" BU_SG_REL_ ZR_MIB_TOP_ab_Gen3 SG_ 258 ESP_QBit_Querb 500;
BA_REL_ "GenSigTimeoutTime" BU_SG_REL_ ZR_MIB_TOP_ab_Gen3 SG_ 258 ESP_Querbeschleunigung 500;
BA_REL_ "GenSigTimeoutTime" BU_SG_REL_ ZR_MIB_TOP_ab_Gen3 SG_ 258 ESP_VZ_Gierrate 500;
BA_REL_ "GenSigTimeoutTime" BU_SG_REL_ ZR_MIB_TOP_ab_Gen3 SG_ 278 ESP_HL_Fahrtrichtung 500;
BA_REL_ "GenSigTimeoutTime" BU_SG_REL_ ZR_MIB_TOP_ab_Gen3 SG_ 278 ESP_HR_Fahrtrichtung 500;
BA_REL_ "GenSigTimeoutTime" BU_SG_REL_ ZR_MIB_TOP_ab_Gen3 SG_ 278 ESP_QBit_Wegimpuls_HL 500;
BA_REL_ "GenSigTimeoutTime" BU_SG_REL_ ZR_MIB_TOP_ab_Gen3 SG_ 278 ESP_QBit_Wegimpuls_HR 500;
BA_REL_ "GenSigTimeoutTime" BU_SG_REL_ ZR_MIB_TOP_ab_Gen3 SG_ 278 ESP_QBit_Wegimpuls_VL 500;
BA_REL_ "GenSigTimeoutTime" BU_SG_REL_ ZR_MIB_TOP_ab_Gen3 SG_ 278 ESP_QBit_Wegimpuls_VR 500;
BA_REL_ "GenSigTimeoutTime" BU_SG_REL_ ZR_MIB_TOP_ab_Gen3 SG_ 278 ESP_VL_Fahrtrichtung 500;
BA_REL_ "GenSigTimeoutTime" BU_SG_REL_ ZR_MIB_TOP_ab_Gen3 SG_ 278 ESP_VR_Fahrtrichtung 500;
BA_REL_ "GenSigTimeoutTime" BU_SG_REL_ ZR_MIB_TOP_ab_Gen3 SG_ 278 ESP_Wegimpuls_HL 500;
BA_REL_ "GenSigTimeoutTime" BU_SG_REL_ ZR_MIB_TOP_ab_Gen3 SG_ 278 ESP_Wegimpuls_HR 500;
BA_REL_ "GenSigTimeoutTime" BU_SG_REL_ ZR_MIB_TOP_ab_Gen3 SG_ 278 ESP_Wegimpuls_VL 500;
BA_REL_ "GenSigTimeoutTime" BU_SG_REL_ ZR_MIB_TOP_ab_Gen3 SG_ 278 ESP_Wegimpuls_VR 500;
BA_REL_ "GenSigTimeoutTime" BU_SG_REL_ ZR_MIB_TOP_ab_Gen3 SG_ 496 EA_Infotainment_Anf 5000;
BA_REL_ "GenSigTimeoutTime" BU_SG_REL_ ZR_MIB_TOP_ab_Gen3 SG_ 522 EML_LenkWnklVL 500;
BA_REL_ "GenSigTimeoutTime" BU_SG_REL_ ZR_MIB_TOP_ab_Gen3 SG_ 522 EML_LenkWnklVR 500;
BA_REL_ "GenSigTimeoutTime" BU_SG_REL_ ZR_MIB_TOP_ab_Gen3 SG_ 795 ESP_Fehlerstatus_Wegimp 500;
BA_REL_ "GenSigTimeoutTime" BU_SG_REL_ ZR_MIB_TOP_ab_Gen3 SG_ 795 ESP_Lampe 500;
BA_REL_ "GenSigTimeoutTime" BU_SG_REL_ ZR_MIB_TOP_ab_Gen3 SG_ 795 ESP_QBit_Wegimp_VA 500;
BA_REL_ "GenSigTimeoutTime" BU_SG_REL_ ZR_MIB_TOP_ab_Gen3 SG_ 795 ESP_Wegimp_Ueberlauf 500;
BA_REL_ "GenSigTimeoutTime" BU_SG_REL_ ZR_MIB_TOP_ab_Gen3 SG_ 795 ESP_Wegimp_VA 500;
BA_REL_ "GenSigTimeoutTime" BU_SG_REL_ ZR_MIB_TOP_ab_Gen3 SG_ 1520 BCM1_Stellgroesse_Kl_58s 2000;
BA_REL_ "GenSigTimeoutTime" BU_SG_REL_ ZR_MIB_TOP_ab_Gen3 SG_ 1520 DI_Display_Nachtdesign 2000;
BA_REL_ "GenSigTimeoutTime" BU_SG_REL_ ZR_MIB_TOP_ab_Gen3 SG_ 1520 DI_Fotosensor 2000;
BA_REL_ "GenSigTimeoutTime" BU_SG_REL_ ZR_MIB_TOP_ab_Gen3 SG_ 1520 DI_KL_58xd 2000;
BA_REL_ "GenSigTimeoutTime" BU_SG_REL_ ZR_MIB_TOP_ab_Gen3 SG_ 1520 DI_KL_58xs 2000;
BA_REL_ "GenSigTimeoutTime" BU_SG_REL_ ZR_MIB_TOP_ab_Gen3 SG_ 1520 DI_KL_58xt 2000;
BA_REL_ "GenSigTimeoutTime" BU_SG_REL_ ZR_MIB_TOP_ab_Gen3 SG_ 1629 ESP_Zaehnezahl 5000;
VAL_ 851 DiETa_Car 0 "Init_oder_nicht_verbaut" 1 "Taste_unbetaetigt" 2 "Taste_betaetigt" 3 "Fehler" ;
VAL_ 851 DiETa_Defrost_Taste 0 "Init_oder_nicht_verbaut" 1 "Taste_unbetaetigt" 2 "Taste_betaetigt" 3 "Fehler" ;
VAL_ 851 DiETa_FAS_Stufe 0 "Init_oder_nicht_verbaut" 1 "Taste_unbetaetigt" 2 "Taste_betaetigt" 3 "Fehler" ;
VAL_ 851 DiETa_FSH_Taste 0 "Init_oder_nicht_verbaut" 1 "Taste_unbetaetigt" 2 "Taste_betaetigt" 3 "Fehler" ;
VAL_ 851 DiETa_HSH_Taste 0 "Init_oder_nicht_verbaut" 1 "Taste_unbetaetigt" 2 "Taste_betaetigt" 3 "Fehler" ;
VAL_ 851 DiETa_Klima 0 "Init_oder_nicht_verbaut" 1 "Taste_unbetaetigt" 2 "Taste_betaetigt" 3 "Fehler" ;
VAL_ 851 DiETa_Lock_Unlock_Taste 0 "Init" 1 "Taste_unbetaetigt" 2 "Taste_betaetigt_unlock" 3 "Taste_betaetigt_lock" 4 "Reserviert" 5 "Reserviert" 6 "Reserviert" 7 "Fehler" ;
VAL_ 851 DiETa_Mode 0 "Init_oder_nicht_verbaut" 1 "Taste_unbetaetigt" 2 "Taste_betaetigt" 3 "Fehler" ;
VAL_ 851 DiETa_Mode2 0 "Init_oder_nicht_verbaut" 1 "Taste_unbetaetigt" 2 "Taste_betaetigt" 3 "Fehler" ;
VAL_ 851 DiETa_Mode_roh 0 "Taste_unbetaetigt" 1 "Taste_betaetigt" ;
VAL_ 851 DiETa_PAO_OFF_Status 0 "LED_Aus" 1 "LED_Ein" 2 "LED_Blinkt" 3 "LED_defekt" ;
VAL_ 851 DiETa_PAO_ON_Status 0 "LED_Aus" 1 "LED_Ein" 2 "LED_Blinkt" 3 "LED_defekt" ;
VAL_ 851 DiETa_Parken 0 "Init_oder_nicht_verbaut" 1 "Taste_unbetaetigt" 2 "Taste_betaetigt" 3 "Fehler" ;
VAL_ 851 DiETa_ResponseError 0 "normal" 1 "Fehler" ;
VAL_ 851 DiETa_Status 0 "DiETa_betriebsbereit" 2 "Init" 3 "Fehler_oder_defekt" ;
VAL_ 851 DiETa_Touch_Event 0 "nicht_betaetigt" 1 "Tippen" 2 "Wischen_Slide" 3 "Geste" 4 "Doppeltippen" 5 "Longpress_1" 6 "Longpress_2" 7 "Longpress_3" 8 "Press" 9 "Strongpress" 10 "reserviert" 11 "reserviert" 12 "reserviert" 13 "reserviert" 14 "Taktgeber_Inkrement" 15 "Fehler" ;
VAL_ 851 DiETa_Warnblink_Taste 0 "Init_oder_nicht_verbaut" 1 "Taste_unbetaetigt" 2 "Taste_betaetigt" 3 "Fehler" ;
VAL_ 851 ESP_Off_Taster 0 "Taste_nicht_betaetigt" 1 "Taste_entprellt_betaetigt" 2 "Init_oder_nicht_verbaut" 3 "Fehler" ;
VAL_ 1520 BCM1_Stellgroesse_Kl_58s 125 "Nicht_verbaut" 126 "Init" 127 "Fehler" ;
VAL_ 1520 DI_KL_58xd 254 "Init" 255 "Fehler" ;
VAL_ 1520 DI_KL_58xs 126 "Init" 127 "Fehler" ;
VAL_ 1520 DI_KL_58xt 126 "Init" 127 "Fehler" ;
VAL_ 2527679674 DispKBI_FS_Systemstatus 0 "DispKBI_IO" 1 "DispKBI_System_Failure" ;
VAL_ 496 ACF_Lampe_Hands_Off 0 "keine_Anzeige" 1 "Hands_Off_erkannt" ;
VAL_ 496 EA_Blinken 0 "Kein_Blinken" 1 "Wechselblinken_links" 2 "Wechselblinken_rechts" 3 "Warnblinken" 4 "Warnblinken_Taster" ;
VAL_ 496 EA_Bremslichtblinken 0 "kein_Blinken" 1 "Anforderung_Bremslichtblinken" ;
VAL_ 496 EA_eCall_Anf 0 "Keine_Anforderung" 1 "Ausloesen_eCall" ;
VAL_ 496 EA_Fahrzeughupe_Anf 0 "keine_Anforderung" 1 "Anforderung_Fahrzeughupe" ;
VAL_ 496 EA_Infotainment_Anf 0 "Init" 1 "Keine_Absenkung" 2 "Absenkung" 3 "Mute" ;
VAL_ 496 EA_Innenraumlicht_Anf 0 "Innenraumbeleuchtung_ausschalten" 1 "Innenraumbeleuchtung_einschalten" ;
VAL_ 496 EA_Status_HMI 0 "Keine_Anzeige" 1 "Aktiv_quer_laengs" 2 "Aktiv_laengs" ;
VAL_ 496 EA_Texte 0 "keine_Anzeige" 1 "Nothalteassistent_fehlende_Fahreraktivitaet" 2 "Nothalteassistent_aktiv_Fahrzeugfuehrung_uebernehmen" 3 "Nothalteassistent_automatischer_Nothalt_wird_durchgefuehrt" 4 "Nothalteassistent_automatischer_Nothalt_durchgefuehrt" 5 "Nothalteassistent_Verbindung_zum_Notruf_wird_aufgebaut" 6 "Nothalteassistent_deaktiviert" 7 "Nothalteassistent_Eingriff_abgebrochen" 8 "Nothalteassistent_fehlende_Fahreraktivitaet_2" 9 "Sekundenschlaf_erkannt" 10 "LaneAssist_Lenkung_uebernehmen" 11 "ACA_Fahrzeugfuehrung_uebernehmen" 12 "EA_Fahr_Standstreifenwechsel" 14 "Nothalteassistent_nicht_verfuegbar_reversibel" 15 "Nothalteassistent_Stoerung_irreversibel" ;
VAL_ 496 EA_Tueren_Anf 0 "Keine_Anforderung" 1 "Tueren_entriegeln" ;
VAL_ 496 EA_Warnlevel 0 "keine_Gefaehrdung" 63 "max_Gefaehrdung" ;
VAL_ 496 STP_Primaeranz 0 "keine_Anzeige" 1 "Verfuegbar" 2 "Aktiv" 3 "Uebernahme" 4 "Aktiv_Warnung" 5 "Nicht_Verfuegbar" ;
VAL_ 496 zFAS_Warnblinken 0 "Aus" 1 "Statisch" 2 "Taster" 3 "Statisch_ohne_WBT" ;
VAL_ 1622 ELV_01_Sendestatus 0 "ELV_sendet_mit_1000ms" 1 "ELV_sendet_mit_50ms" ;
VAL_ 1622 ELV_Abbruch_Anf_Klemmenfreigabe 0 "kein_Abbruch" 1 "Abbruch" ;
VAL_ 1622 ELV_Anf_Klemme_15 0 "Aus" 1 "Ein" ;
VAL_ 1622 ELV_Anf_Klemme_50 0 "Aus" 1 "Ein" ;
VAL_ 1622 ELV_Anf_Klemme_S 0 "Aus" 1 "Ein" ;
VAL_ 1622 ELV_Anlernmodus 0 "Normalbetrieb" 1 "Anlernmodus" ;
VAL_ 1622 ELV_Entriegelt 0 "ELV_nicht_entriegelt" 1 "ELV_entriegelt" ;
VAL_ 1622 ELV_Klemmenfreigabe 0 "keine_Freigabe" 1 "Freigabe" ;
VAL_ 1622 ELV_Lebenszustand 0 "Lebenszustand_0" 1 "Lebenszustand_4" ;
VAL_ 1622 ELV_LED_Gelb 0 "Aus" 1 "Ein" ;
VAL_ 1622 ELV_LED_Rot 0 "Aus" 1 "Ein" ;
VAL_ 1622 ELV_P_verriegelt 0 "nicht_verriegelt" 1 "verriegelt" ;
VAL_ 1622 ELV_Txt_Bremse 0 "Aus" 1 "Ein" ;
VAL_ 1622 ELV_Txt_Defekt 0 "Aus" 1 "Ein" ;
VAL_ 1622 ELV_Txt_Kupplung 0 "Aus" 1 "Ein" ;
VAL_ 1622 ELV_Txt_Lkg_Bewegen 0 "Aus" 1 "Ein" ;
VAL_ 1622 ELV_Txt_P_Gang 0 "Aus" 1 "Ein" ;
VAL_ 1622 ELV_Txt_Panikabschaltung 0 "Aus" 1 "Ein" ;
VAL_ 1622 ELV_Txt_PN_Gang 0 "Aus" 1 "Ein" ;
VAL_ 1622 ELV_Txt_Werkstatt 0 "Aus" 1 "Ein" ;
VAL_ 1622 ELV_Verriegelt 0 "nicht_verriegelt" 1 "verriegelt" ;
VAL_ 1622 ELV_ZAT_betaetigt 0 "nicht_betaetigt" 1 "betaetigt" ;
VAL_ 1622 KST_Anf_ZV_Verriegelung 0 "inaktiv" 1 "aktiv" ;
VAL_ 1622 KST_aut_Abschaltung_Zuendung 0 "Zuendung_wird_bei_Verl_nicht_deaktiviert" 1 "Zuendung_wird_bei_Verl_deaktiviert" ;
VAL_ 1622 KST_Txt_Komfortabschaltung 0 "inaktiv" 1 "aktiv" ;
VAL_ 522 EML_AnzeigeGeschw 1022 "Init" 1023 "Fehler" ;
VAL_ 522 EML_BeschlX 2046 "Init" 2047 "Fehler" ;
VAL_ 522 EML_BeschlXCF 0 "gueltiger_Wert" 1 "Best_Guess" 4 "Eingangsdatenfehler" 6 "Init" 7 "Fehler" ;
VAL_ 522 EML_BeschlY 2046 "Init" 2047 "Fehler" ;
VAL_ 522 EML_BeschlYCF 0 "gueltiger_Wert" 1 "Best_Guess" 4 "Eingangsdatenfehler" 6 "Init" 7 "Fehler" ;
VAL_ 522 EML_Fahrtrichtungswahrsch 254 "Init" 255 "Fehler" ;
VAL_ 522 EML_Fahrwerksregeleingriff 0 "Kein_Eingriff" 1 "Eingriff_erkannt" 2 "Passivtaster_aktiv" 3 "reserviert" 4 "reserviert" 5 "reserviert" 6 "Init" 7 "Fehler" ;
VAL_ 522 EML_GeschwX 4094 "Init" 4095 "Fehler" ;
VAL_ 522 EML_GeschwXStdA 61 "Best_Guess" 62 "Init" 63 "Fehler" ;
VAL_ 522 EML_GierRate 65534 "Init" 65535 "Fehler" ;
VAL_ 522 EML_GierRateCF 0 "gueltiger_Wert" 1 "Best_Guess" 4 "Eingangsdatenfehler" 6 "Init" 7 "Fehler" ;
VAL_ 522 EML_GierRateStdA 61 "Best_Guess" 62 "Init" 63 "Fehler" ;
VAL_ 522 EML_Gierwinkel 16382 "Init" 16383 "Fehler" ;
VAL_ 522 EML_GierwinkelCF 0 "GueltigerWert" 1 "BestGuessOderErsatzwert" 2 "Init" 3 "Fehler" ;
VAL_ 522 EML_GierwinkelStdA 29 "Best_Guess" 30 "Init" 31 "Fehler" ;
VAL_ 522 EML_Hoehe2USK 126 "Init" 127 "Fehler" ;
VAL_ 522 EML_Hoehe2USKStdA 13 "Best_Guess" 14 "Init" 15 "Fehler" ;
VAL_ 522 EML_Hoehe_Nick_Wankwinkel2USKCF 0 "GueltigerWert" 1 "BestGuessOderErsatzwert" 2 "Init" 3 "Fehler" ;
VAL_ 522 EML_Kurvenkruemmung 16382 "Init" 16383 "Fehler" ;
VAL_ 522 EML_LenkWnklVL 1022 "Init" 1023 "Fehler" ;
VAL_ 522 EML_LenkWnklVR 1022 "Init" 1023 "Fehler" ;
VAL_ 522 EML_MessZeitpunkt 8191 "Init" ;
VAL_ 522 EML_Nickwinkel 4094 "Init" 4095 "Fehler" ;
VAL_ 522 EML_Nickwinkel2USK 126 "Init" 127 "Fehler" ;
VAL_ 522 EML_Nickwinkel2USKStdA 13 "Best_Guess" 14 "Init" 15 "Fehler" ;
VAL_ 522 EML_Pose_Qualifier 0 "Fehler" 1 "Ja" ;
VAL_ 522 EML_PositionCF 0 "GueltigerWert" 1 "BestGuessOderErsatzwert" 2 "Init" 3 "Fehler" ;
VAL_ 522 EML_PositionX 16382 "Init" 16383 "Fehler" ;
VAL_ 522 EML_PositionXStdA 61 "Best_Guess" 62 "Init" 63 "Fehler" ;
VAL_ 522 EML_PositionY 16382 "Init" 16383 "Fehler" ;
VAL_ 522 EML_PositionYStdA 61 "Best_Guess" 62 "Init" 63 "Fehler" ;
VAL_ 522 EML_QBit_Anzeigegeschw 0 "gueltiger_Wert" 1 "Ersatz_Init_oder_Fehlerwert" ;
VAL_ 522 EML_QBit_Fahrtrichtungswahrsch 0 "gueltiger_Wert" 1 "Ersatz_Init_oder_Fehlerwert" ;
VAL_ 522 EML_QBit_Kurvenkruemmung 0 "gueltiger_Wert" 1 "Ersatz_Init_oder_Fehlerwert" ;
VAL_ 522 EML_QBit_Nickwinkel 0 "gueltiger_Wert" 1 "Ersatz_Init_oder_Fehlerwert" ;
VAL_ 522 EML_QBit_Stillstandswahrsch 0 "gueltiger_Wert" 1 "Ersatz_Init_oder_Fehlerwert" ;
VAL_ 522 EML_Stillstandswahrsch 126 "Init" 127 "Fehler" ;
VAL_ 522 EML_Wankwinkel2USK 254 "Init" 255 "Fehler" ;
VAL_ 522 EML_Wankwinkel2USKStdA 13 "Best_Guess" 14 "Init" 15 "Fehler" ;
VAL_ 608 EML_AnzeigeGeschw 1022 "Init" 1023 "Fehler" ;
VAL_ 608 EML_QBit_Anzeigegeschw 0 "gueltiger_Wert" 1 "Ersatz_Init_oder_Fehlerwert" ;
VAL_ 2589283970 DIST_DKmtg_Auth 0 "Fehler" ;
VAL_ 2331595989 DIST_DKmtg 0 "Fehler" ;
VAL_ 2589283751 KBI_Kilometerstand_Extended 16777214 "Init" 16777215 "Fehler" ;
VAL_ 503 EPB_Autohold_Standbyanzeige 0 "Lampe aus" 1 "Lampe ein" ;
VAL_ 503 EPB_Autoholdlampe_02 0 "Lampe aus (Autohold inaktiv)" 1 "Lampe ein (Autohold aktiv)" ;
VAL_ 503 EPB_Fehlermeldungen_02 0 "keine_Anzeige" 1 "Systemstoerung_Kl15an" 2 "Systemstoerung_Kl15aus" 3 "Parkbremse_betaetigen" 4 "Systemstoerung_Hanghaltefaehigkeit" 5 "Funktionseinschraenkung_Kl15an" 6 "Funktionseinschraenkung_Kl15aus" 7 "HU_Modus_aktiv" 8 "Transportmodus" 9 "Produktionsmodus" 10 "FktEinschr_Taster_defekt" 11 "Funktionseinschraenkung_Hanghalt" ;
VAL_ 503 EPB_Funktionslampe_02 0 "Aus" 1 "Ein" ;
VAL_ 503 EPB_Parkanzeige 0 "aus" 1 "an" 2 "blinken" 3 "reserviert" ;
VAL_ 503 EPB_Texte_02 0 "keine_Anzeige" 1 "Neigungswinkel_zu_gross" 2 "Parkbremse_von_Hand_oeffnen" 3 "HU_Modus_oder_EPB_in_Diagnose" 4 "Bremspedal_betaetigen" 5 "EPB_durch_Fahrstufe_loesen" 6 "tbd" 7 "Stoerung_Anfahrassistent" 8 "Motor_starten" 9 "Feststellbremse_nicht_automatisch_geschlossen" 10 "Parkbremse_loesen_nicht_moeglich_Ladekabel_gesteckt" 11 "Notbremsung_ueber_EPB_Taster" 12 "Parkbremse_angezogen" 13 "Parkbremse_loesen_nicht_moeglich_ParkPilot_aktiv" ;
VAL_ 258 ASR_Systemstatus 0 "ASR_passiv_getastet" 1 "ASR_Schwellen_geaendert" 2 "ASR_aktiviert" 3 "ASR_Stoerung" ;
VAL_ 258 ECD_Bremslicht 0 "Aus" 1 "Ein" ;
VAL_ 258 ECD_Fehler 0 "ECD_iO" 1 "ECD_Fehler" ;
VAL_ 258 ECD_nicht_verfuegbar 0 "ECD_Funktion_verfuegbar" 1 "ECD_Funktion_nicht_verfuegbar" ;
VAL_ 258 EPB_DAA_Randbed_erf 0 "Randbed_nicht_erfuellt" 1 "Randbed_erfuellt" ;
VAL_ 258 EPB_Fehlerstatus_02 0 "kein_Fehler" 1 "Fehler_ausserhalb_apply_release" 2 "Fehler_einseitig_apply_release" 3 "Fehler_beidseitig_apply_release" ;
VAL_ 258 EPB_Freig_Verzoeg_Anf 0 "nicht freigegeben" 1 "freigegeben" ;
VAL_ 258 EPB_Pedalweg_Kuppl 0 "Init" 255 "Fehler" ;
VAL_ 258 EPB_QBit_Pedalweg_Kuppl 0 "gï?½ltiger Wert" 1 "Ersatz-, Init- oder Fehlerwert" ;
VAL_ 258 EPB_QBit_Schalterpos 0 "gï?½ltiger Wert (volle Funktion)" 1 "" ;
VAL_ 258 EPB_Schalterposition 0 "keine Fahreranforderung" 1 "Fahreranforderung ï?½ffnen" 2 "Fahreranforderung Schlieï?½en" 3 "Fehler" ;
VAL_ 258 EPB_Spannkraft 30 "Init" 31 "Fehler" ;
VAL_ 258 EPB_Status 0 "offen" 1 "Bremse_geschl_(Spannkraft_voll/reduziert)" 2 "Aktuator_im_Lauf" 3 "Fehler_oder_unbekannt" ;
VAL_ 258 EPB_Status_02 0 "offen" 1 "geschlossen_Parken" 2 "teilgespannt_Halten" 3 "im_Lauf_oeffnen" 4 "im_Lauf_schliessen" 5 "tbd" 6 "Init" 7 "unbekannt" ;
VAL_ 258 ESC_Bremsdruckgradient 251 "groesser_2500_bar_per_sec" 254 "Init" 255 "Fehler" ;
VAL_ 258 ESC_Fahrerbremswunsch 1023 "Fehler" ;
VAL_ 258 ESC_Fahrerradbremswunschmoment 4094 "Init" 4095 "Fehler" ;
VAL_ 258 ESC_Hydr_Fkt_aktiv 0 "keine_Aktivitaet" 1 "ESC_Druckaufbau_HBx_HFC_aktiv" 2 "Warnrucklevel_Summand_1" 3 "Warnrucklevel_Summand_3" ;
VAL_ 258 ESC_Motorstartverzoegerung 0 "Startfreigabe" 1 "Anforderung_Startverzoegerung" ;
VAL_ 258 ESC_QBit_Fahrerbremswunsch 0 "gueltiger_Wert" 1 "Ersatz_Init_oder_Fehlerwert" ;
VAL_ 258 ESC_Raddruck_max 254 "Init" 255 "Fehler" ;
VAL_ 258 ESC_SeitenwindAssistent_Eingriff 0 "Kein_SWA_Eingriff_und_Init" 1 "SWA_Eingriff_aktiv" ;
VAL_ 258 ESC_Unterdruckmangel_erkannt 0 "kein_Unterdruckmangel_erkannt" 1 "Unterdruckmangel_erkannt" ;
VAL_ 258 ESCGeneratorSollMoment 4094 "Init" 4095 "Fehler" ;
VAL_ 258 ESP_Abrutschen_Stillstand 0 "kein_Abrutschen_erkannt" 1 "Abrutschen_erkannt" ;
VAL_ 258 ESP_ANB_CM_Rueckk_Umsetz 0 "keine_Ausfuehrung" 1 "Ausfuehrung" ;
VAL_ 258 ESP_Anforderung_EPB 0 "keine_Anforderung" 1 "Anforderung_Oeffnen" 2 "Anforderung_Schliessen" 3 "reserviert" ;
VAL_ 258 ESP_Anschleppstart_Freigabe 0 "kein_Schleppstart_oder_NotSchleppstart_erlaubt" 1 "NotSchleppstart_erlaubt" 2 "Schleppstart_und_NotSchleppStart_erlaubt" ;
VAL_ 258 ESP_Autohold_aktiv 0 "Autohold_inaktiv" 1 "Autohold_aktiv" ;
VAL_ 258 ESP_Autohold_Standby 0 "Autohold_nicht_im_Standby" 1 "Autohold_im_Standby" ;
VAL_ 258 ESP_BKV_Unterdruck 0 "nicht_verbaut_oder_nicht_kodiert" 254 "Init" 255 "Fehler" ;
VAL_ 258 ESP_Bremsdruck 1023 "Fehler" ;
VAL_ 258 ESP_Bremsruck_AWV2 0 "kein_Bremsruck_ausgefuehrt" 1 "Bremsruck_ausgefuehrt" ;
VAL_ 258 ESP_Eingr_HL 0 "kein_Eingriff" 1 "ESP_Eingriff_HL" ;
VAL_ 258 ESP_Eingr_HR 0 "kein_Eingriff" 1 "ESP_Eingriff_HR" ;
VAL_ 258 ESP_Eingr_VL 0 "kein_Eingriff" 1 "ESP_Eingriff_VL" ;
VAL_ 258 ESP_Eingr_VR 0 "kein_Eingriff" 1 "ESP_Eingriff_VR" ;
VAL_ 258 ESP_Fahrer_bremst 0 "Bremsdruckschwelle_nicht_ueberschritten" 1 "Bremsdruckschwelle_ueberschritten" ;
VAL_ 258 ESP_Fahrer_tritt_ZBR_Schw 0 "Fahrer_uebertritt_ZBR_Schwelle_nicht" 1 "Fahrer_uebertritt_ZBR_Schwelle" ;
VAL_ 258 ESP_FStatus_Anfahrhilfe 0 "kein_Fehler" 1 "Fehler" ;
VAL_ 258 ESP_Gierrate 16383 "Fehler" ;
VAL_ 258 ESP_HBA_aktiv 0 "HBA_nicht_aktiv" 1 "HBA_aktiv" ;
VAL_ 258 ESP_HDC_aktiv 0 "inaktiv" 1 "aktiv" ;
VAL_ 258 ESP_HDC_Standby 0 "HDC_Funktion_nicht_im_Standby" 1 "HDC_Funktion_im_Standby" ;
VAL_ 258 ESP_Konsistenz_ACC_Botschaft 0 "Botschaft_fuer_ACC_konsistent" 1 "Botschaft_fuer_ACC_nicht_konsistent" ;
VAL_ 258 ESP_Konsistenz_AWV2 0 "Botschaft_fuer_AWV2_konsistent" 1 "Botschaft_fuer_AWV2_nicht_konsistent" ;
VAL_ 258 ESP_Konsistenz_TSK 0 "Botschaft_fuer_Verzoegerungsanforderung_konsistent" 1 "Botschaft_fuer_Verzoegerungsanforderung_nicht_konsistent" ;
VAL_ 258 ESP_Laengsbeschl 1022 "Signal_nicht_vorhanden" 1023 "Fehler" ;
VAL_ 258 ESP_Lenkeingriff_ADS 0 "kein_Lenkeingriff" 1 "stabilisierender_Lenkeingriff" ;
VAL_ 258 ESP_Notbremsanzeige 0 "keine_Notbremsung_erkannt" 1 "Notbremsung_erkannt" ;
VAL_ 258 ESP_PLA_Abbruch 0 "Init" 1 "Geschwindigkeitsueberschreitung" 2 "Falscher_PLA_Status" 3 "Deaktivierung_durch_Abbruch_Lenkung" 4 "PLA_Bremsanforderung_nach_Stillstand" 5 "Abbruch_durch_Kl15_aus" 6 "Abbruch_durch_FT_offen" ;
VAL_ 258 ESP_Prefill_ausgeloest 0 "nicht_ausgeloest" 1 "Prefill_ausgeloest" ;
VAL_ 258 ESP_QBit_Bremsdruck 0 "gueltiger_Wert" 1 "Ersatz_Init_oder_Fehlerwert" ;
VAL_ 258 ESP_QBit_Fahrer_bremst 0 "gueltiger_Wert" 1 "Ersatz_Init_oder_Fehlerwert" ;
VAL_ 258 ESP_QBit_Gierrate 0 "gueltiger_Wert" 1 "Ersatz_Init_oder_Fehlerwert" ;
VAL_ 258 ESP_QBit_Laengsbeschl 0 "gueltiger_Wert" 1 "Ersatz_Init_oder_Fehlerwert" ;
VAL_ 258 ESP_QBit_Querb 0 "gueltiger_Wert" 1 "Ersatz_Init_oder_Fehlerwert" ;
VAL_ 258 ESP_QBit_v_ref 0 "gueltiger_Wert" 1 "Ersatz_Init_oder_Fehlerwert" ;
VAL_ 258 ESP_Querbeschleunigung 255 "Fehler" ;
VAL_ 258 ESP_Rueckwaertsfahrt_erkannt 0 "keine_Rueckwaetsfahrt" 1 "Rueckwaertsfahrt_sicher_erkannt" ;
VAL_ 258 ESP_Schwelle_Unterdruck 0 "kein_Signal" 1 "Unterdruck_kleiner_gleich_450_mbar" 2 "Unterdruck_groesser_450_mbar" 3 "Fehler_Unterdrucksensor" ;
VAL_ 258 ESP_SpannungsAnf 0 "keine_Anforderung" 1 "Anforderung_Spannungswert_1" ;
VAL_ 258 ESP_StartStopp_Info 0 "Motorlauf_nicht_notwendig_(Stoppfreigabe)" 1 "Motoranlauf_nicht_zwingend_notwendig_(Stoppverbot,keine_Startanforderung)" 2 "Motoranlauf_zwingend_notwendig_(Startanforderung)" 3 "Systemfehler" ;
VAL_ 258 ESP_Status_Anfahrhilfe 0 "Aus" 1 "Ein" ;
VAL_ 258 ESP_Status_Bremsdruck 0 "Bremse_drucklos" 1 "mit_Bremsdruck" ;
VAL_ 258 ESP_Status_Bremsentemp 0 "Bremse_nicht_ueberhitzt" 1 "Bremse_ueberhitzt" ;
VAL_ 258 ESP_Status_Bremsentemp_02 0 "nicht_erhoeht" 1 "Schwelle_1" 2 "Schwelle_2" ;
VAL_ 258 ESP_Status_ESP_PLA 0 "ESP_PLA_deaktiv" 1 "ESP_PLA_Init" 2 "ESP_PLA_Fehler" 4 "ESP_PLA_aktivierbar" 6 "ESP_PLA_Bremse_aktiv" 8 "ESP_PLA_funktionsbereit" 9 "ESP_PLA_Neustart" 10 "ESP_PLA_Abbruch" ;
VAL_ 258 ESP_Stillstandsphase_erschoepft 0 "sicheres_Halten_moeglich" 1 "kein_sicheres_Halten_moeglich" ;
VAL_ 258 ESP_Systemstatus_03 0 "ESC_passiv_getastet" 1 "ESC_Schwellen_geaendert" 2 "ESC_aktiviert" 3 "Fehler" ;
VAL_ 258 ESP_Tuerkontakt_Fahrertuer 0 "Schalter_geschlossen" 1 "Schalter_offen" ;
VAL_ 258 ESP_v_ref 4093 "Unterspannung" 4094 "Init" 4095 "Fehler" ;
VAL_ 258 ESP_v_ref_Fahrtrichtung 0 "Fahrtrichtung_nicht_definiert" 1 "Vorwaerts" 2 "Rueckwaerts" 3 "Stillstand" ;
VAL_ 258 ESP_Verz_EPB_aktiv 0 "nicht_aktiviert" 1 "aktiviert" ;
VAL_ 258 ESP_Verz_TSK_aktiv 0 "TSK_Verzoegerung_inaktiv" 1 "TSK_Verzoegerung_aktiv" ;
VAL_ 258 ESP_Verzoeg_EPB_verf 0 "nicht_verfuegbar" 1 "System_verfuegbar" ;
VAL_ 258 ESP_VZ_Gierrate 0 "positiv" 1 "negativ" ;
VAL_ 258 ESP_ZT_Rueckk_Umsetz 0 "keine_Ausfuehrung" 1 "Ausfuehrung" ;
VAL_ 252 ESC_Achsdrehzahl_Max 16382 "Init" 16383 "Fehler" ;
VAL_ 252 ESC_Achsdrehzahl_Max_sek 16382 "Init" 16383 "Fehler" ;
VAL_ 252 ESC_Achsdrehzahl_Min 16382 "Init" 16383 "Fehler" ;
VAL_ 252 ESC_Achsdrehzahl_Min_sek 16382 "Init" 16383 "Fehler" ;
VAL_ 252 ESC_aktBR_Modus_02 0 "Aktivbremsung_Aus" 1 "Aktivbremsung_FastInit" 2 "Aktivbremsung_Aktiv" 3 "Aktivbremsung_NoLimitAktiv" ;
VAL_ 252 ESC_Allrad_Anteil_max_sek 510 "Init" 511 "Fehler" ;
VAL_ 252 ESC_Allrad_Anteil_min_sek 510 "Init" 511 "Fehler" ;
VAL_ 252 ESC_Allradverteilung_aktiv 0 "kein_Eingriff" 1 "Allradeingriff_aktiv" ;
VAL_ 252 ESC_Anf_Mindestreku 0 "nicht_angefordert" 1 "angefordert" ;
VAL_ 252 ESC_Blending_Solldruck 1022 "Init" 1023 "Fehler" ;
VAL_ 252 ESC_Bremsdruck_02 1023 "Fehler" ;
VAL_ 252 ESC_Bremsdruck_Modell 1022 "Init" 1023 "Fehler" ;
VAL_ 252 ESC_EBKV_Kraftblending_Modus 0 "Inactive" 1 "Hold" 2 "Active" ;
VAL_ 252 ESC_GMV_aktiv 0 "keine_Aktivitaet" 1 "Aktivitaet_durch_AWA" ;
VAL_ 252 ESC_GMV_nicht_verfuegbar 0 "verfuegbar" 1 "nicht_verfuegbar" ;
VAL_ 252 ESC_MomRad_Eingriff 8190 "Init" 8191 "Fehler" ;
VAL_ 252 ESC_MomRad_Eingriff_sek 8190 "Init" 8191 "Fehler" ;
VAL_ 252 ESC_QBit_Bremsdruck_02 0 "gueltiger_Wert" 1 "Ersatz_Init_oder_Fehlerwert" ;
VAL_ 252 ESC_Status_Eingriff 0 "kein Eingriff" 1 "ASR-Eingriff" 2 "MSR-Eingriff" 3 "nicht belegt " ;
VAL_ 252 ESC_Status_Eingriff_sek 0 "kein Eingriff" 1 "ASR-Eingriff" 2 "MSR-Eingriff" 3 "nicht belegt " ;
VAL_ 252 ESC_Status_vRef_Stuetzeingriff 0 "kein_Eingriff" 1 "Stuetzungseingriff" ;
VAL_ 252 ESP_FDR_uebersteuern 254 "Init" 255 "Fehler" ;
VAL_ 252 ESP_FDR_untersteuern 254 "Init" 255 "Fehler" ;
VAL_ 252 ESP_FZR_uebersteuern 254 "Init" 255 "Fehler" ;
VAL_ 252 ESP_FZR_untersteuern 254 "Init" 255 "Fehler" ;
VAL_ 252 ESP_HL_Bremsmoment 254 "Init" 255 "Fehler" ;
VAL_ 252 ESP_HL_Radgeschw_02 65533 "Unterspannung" 65534 "Init" 65535 "Fehler" ;
VAL_ 252 ESP_HR_Bremsmoment 254 "Init" 255 "Fehler" ;
VAL_ 252 ESP_HR_Radgeschw_02 65533 "Unterspannung" 65534 "Init" 65535 "Fehler" ;
VAL_ 252 ESP_VL_Bremsmoment 254 "Init" 255 "Fehler" ;
VAL_ 252 ESP_VL_Radgeschw_02 65533 "Unterspannung" 65534 "Init" 65535 "Fehler" ;
VAL_ 252 ESP_VR_Bremsmoment 254 "Init" 255 "Fehler" ;
VAL_ 252 ESP_VR_Radgeschw_02 65533 "Unterspannung" 65534 "Init" 65535 "Fehler" ;
VAL_ 252 FDR_Allradverteilung_aktiv 0 "kein_Eingriff" 1 "Allradeingriff_aktiv" ;
VAL_ 252 FDR_Anf_Allradbetrieb 0 "keine_Anforderung" 1 "Kraftschluss_an_beiden_Achsen_herstellen" ;
VAL_ 252 TSMomBegrenzung 4094 "Init" 4095 "Fehler" ;
VAL_ 885 SSO_EdgeCount_Sum 0 "Fehler" ;
VAL_ 278 ESP_HL_Fahrtrichtung 0 "Vorwaerts" 1 "Rueckwaerts" 2 "Init" 3 "ungueltig_oder_nicht_verbaut" ;
VAL_ 278 ESP_HR_Fahrtrichtung 0 "Vorwaerts" 1 "Rueckwaerts" 2 "Init" 3 "ungueltig_oder_nicht_verbaut" ;
VAL_ 278 ESP_QBit_Wegimpuls_HL 0 "gueltiger_Wert" 1 "Ersatz_Init_oder_Fehlerwert" ;
VAL_ 278 ESP_QBit_Wegimpuls_HR 0 "gueltiger_Wert" 1 "Ersatz_Init_oder_Fehlerwert" ;
VAL_ 278 ESP_QBit_Wegimpuls_VL 0 "gueltiger_Wert" 1 "Ersatz_Init_oder_Fehlerwert" ;
VAL_ 278 ESP_QBit_Wegimpuls_VR 0 "gueltiger_Wert" 1 "Ersatz_Init_oder_Fehlerwert" ;
VAL_ 278 ESP_VL_Fahrtrichtung 0 "Vorwaerts" 1 "Rueckwaerts" 2 "Init" 3 "ungueltig_oder_nicht_verbaut" ;
VAL_ 278 ESP_VR_Fahrtrichtung 0 "Vorwaerts" 1 "Rueckwaerts" 2 "Init" 3 "ungueltig_oder_nicht_verbaut" ;
VAL_ 278 ESP_Wegimpuls_HL 1021 "Init" 1022 "Unterspannung" 1023 "Fehler" ;
VAL_ 278 ESP_Wegimpuls_HR 1021 "Init" 1022 "Unterspannung" 1023 "Fehler" ;
VAL_ 278 ESP_Wegimpuls_VL 1021 "Init" 1022 "Unterspannung" 1023 "Fehler" ;
VAL_ 278 ESP_Wegimpuls_VR 1021 "Init" 1022 "Unterspannung" 1023 "Fehler" ;
VAL_ 1629 BR_QBit_Reifenumfang 0 "gueltiger_Wert" 1 "Ersatz_Init_oder_Fehlerwert" ;
VAL_ 1629 BR_Systemart 0 "ABS" 1 "ABS_ASR" 2 "ESP" 3 "ESP_mit_integrierter_EPB" ;
VAL_ 1629 ESP_Charisma_FahrPr 0 "keine_Funktion" 1 "Programm_1" 2 "Programm_2" 3 "Programm_3" 4 "Programm_4" 5 "Programm_5" 6 "Programm_6" 7 "Programm_7" 8 "Programm_8" 9 "Programm_9" 10 "Programm_10" 11 "Programm_11" 12 "Programm_12" 13 "Programm_13" 14 "Programm_14" 15 "Programm_15" ;
VAL_ 1629 ESP_Charisma_Status 0 "Init" 1 "verfuegbar" 2 "nicht_verfuegbar" 3 "asynchron_durch_Fahrerwunsch" ;
VAL_ 1629 ESP_Dachrelingsensor 0 "Sensor_nicht_verbaut" 1 "Quertraeger_montiert" 2 "Quertraeger_nicht_montiert" 3 "Fehler" ;
VAL_ 1629 ESP_SpannungsAnf_02 0 "keine_Anforderung" 1 "Anforderung_Stufe1" 2 "Anforderung_Stufe2" 3 "Anforderung_Stufe3" ;
VAL_ 1629 ESP_Stoppverbot_Anz_01 0 "keine_Anzeige" 1 "Notbremsung_aktiv" ;
VAL_ 1629 ESP_Stoppverbot_Anz_02 0 "keine_Anzeige" 1 "Autohold_AVH_Rutschen" ;
VAL_ 1629 ESP_Stoppverbot_Anz_03 0 "keine_Anzeige" 1 "Rueckwaertsrollen" ;
VAL_ 1629 ESP_Stoppverbot_Anz_04 0 "keine_Anzeige" 1 "ESP_Pumpenlauf" ;
VAL_ 1629 ESP_Stoppverbot_Anz_05 0 "keine_Anzeige" 1 "ESP_OFF" ;
VAL_ 1629 ESP_Stoppverbot_Anz_06 0 "keine_Anzeige" 1 "Offroad_HDC" ;
VAL_ 1629 ESP_Stoppverbot_Anz_07 0 "keine_Anzeige" 1 "ESP_Haltefunktion_nicht_verfuegbar" ;
VAL_ 1629 ESP_Stoppverbot_Anz_08 0 "keine_Anzeige" 1 "Neigungsbegrenzung" ;
VAL_ 1629 ESP_Stoppverbot_Anz_Std 0 "keine_Anzeige" 1 "Standard_Stoppvetogrund" ;
VAL_ 1629 ESP_Wiederstart_Anz_01 0 "keine_Anzeige" 1 "Rueckwaertsrollen" ;
VAL_ 1629 ESP_Wiederstart_Anz_02 0 "keine_Anzeige" 1 "Autohold_Rutschen" ;
VAL_ 1629 ESP_Wiederstart_Anz_03 0 "keine_Anzeige" 1 "Offroad_HDC" ;
VAL_ 1629 ESP_Wiederstart_Anz_04 0 "keine_Anzeige" 1 "ESC_Off" ;
VAL_ 1629 HDC_Charisma_FahrPr 0 "keine_Funktion" 1 "Programm_1" 2 "Programm_2" 3 "Programm_3" 4 "Programm_4" 5 "Programm_5" 6 "Programm_6" 7 "Programm_7" 8 "Programm_8" 9 "Programm_9" 10 "Programm_10" 11 "Programm_11" 12 "Programm_12" 13 "Programm_13" 14 "Programm_14" 15 "Programm_15" ;
VAL_ 1629 HDC_Charisma_Status 0 "Init" 1 "verfuegbar" 2 "nicht_verfuegbar" 3 "asynchron_durch_Fahrerwunsch" ;
VAL_ 253 ABS_Bremsung 0 "keine_ABS_Regelung" 1 "ABS_Regelung_aktiv" ;
VAL_ 253 ASR_Anf 0 "keine_Anforderung" 1 "ASR_Anforderung" ;
VAL_ 253 ASR_Schalteingriff 0 "keine_Anforderung" 1 "ASR_Schaltkennfeld" 2 "Rueckschaltung" 3 "Schaltverbot" ;
VAL_ 253 ASR_Tastung_passiv 0 "ASR_aktiviert" 1 "ASR_passiv_getastet_oder_Schwellen_geaendert" ;
VAL_ 253 BR_Eingriffsmoment 1022 "Init" 1023 "Fehler" ;
VAL_ 253 EBV_Eingriff 0 "kein_EBV_Eingriff" 1 "EBV_Eingriff" ;
VAL_ 253 EDS_Eingriff 0 "kein_EDS_Eingriff" 1 "EDS_Eingriff" ;
VAL_ 253 ESC_Reku_Freigabe 0 "keine_Freigabe_der_Rekuperation" 1 "Freigabe_der_Rekuperation" ;
VAL_ 253 ESC_v_Signal_Qualifier_High_Low 0 "Gueteschwelle_kleiner_1kmh" 1 "Gueteschwelle_kleiner_3kmh" 2 "Gueteschwelle_kleiner_5kmh" 3 "Gueteschwelle_kleiner_10kmh" 4 "Gueteschwelle_kleiner_20kmh" 5 "Gueteschwelle_groessergleich_20kmh" 6 "Init" 7 "Fehler" ;
VAL_ 253 ESP_Anhaltevorgang_ACC_aktiv 0 "inaktiv" 1 "aktiv" ;
VAL_ 253 ESP_ASP 0 "inaktiv" 1 "aktiv" ;
VAL_ 253 ESP_AWV3_Brems_aktiv 0 "inaktiv" 1 "aktiv" ;
VAL_ 253 ESP_Diagnose 0 "ESP_nicht_in_Diagnose" 1 "ESP_in_Diagnose" ;
VAL_ 253 ESP_Eingriff 0 "kein_ESP_Eingriff" 1 "ESP_Eingriff_aktiv" ;
VAL_ 253 ESP_Haltebestaetigung 0 "kein_sicheres_Halten" 1 "sicheres_Halten" ;
VAL_ 253 ESP_MKB_Abbruch_Geschw 0 "MKB_nicht_beendet_wg_v_Schwelle" 1 "MKB_beendet_wg_v_Schwelle" ;
VAL_ 253 ESP_PLA_Bremseingriff 0 "inaktiv" 1 "aktiv" ;
VAL_ 253 ESP_QBit_v_Signal 0 "gueltiger_Wert" 1 "Ersatz_Init_oder_Fehlerwert" ;
VAL_ 253 ESP_Systemstatus 0 "iO" 1 "Fehler" ;
VAL_ 253 ESP_Tastung_passiv 0 "ESP_aktiviert" 1 "ESP_passiv_getastet_oder_Schwellen_geaendert" ;
VAL_ 253 ESP_v_Signal 65533 "Unterspannung" 65534 "Init" 65535 "Fehler" ;
VAL_ 253 ESP_Vorsteuerung 0 "keine_Vorsteuerung_aktiv" 1 "Vorsteuerung_aktiv" ;
VAL_ 253 MSR_Anf 0 "keine Anfoderung" 1 "MSR-Anforderung" ;
VAL_ 253 OBD_QBit_Schlechtweg 0 "gueltiger_Wert" 1 "Ersatz_Init_oder_Fehlerwert" ;
VAL_ 253 OBD_Schlechtweg 0 "kein_Schlechtweg_erkannt" 1 "Schlechtweg_erkannt" ;
VAL_ 795 ABS_Lampe 0 "Aus" 1 "Ein" ;
VAL_ 795 BK_Lampe_02 0 "aus" 1 "Typ1_ein_statisch" 2 "Typ2_ein_statisch" 3 "Warnung" ;
VAL_ 795 ESP_BKV_Warnung 0 "keine_Anzeige" 1 "keine_Bremskraftverstaerkung" ;
VAL_ 795 ESP_Fehlerstatus_Wegimp 0 "Wegimpulse_iO" 1 "Fehler" ;
VAL_ 795 ESP_HDC_FktLampe 0 "Aus" 1 "Ein" ;
VAL_ 795 ESP_HDC_Regelgeschw 0 "nicht_verbaut" 125 "HDC_Standby" 126 "Init" 127 "Fehler" ;
VAL_ 795 ESP_Lampe 0 "Aus" 1 "Ein" ;
VAL_ 795 ESP_m_Raddrehz 32765 "Unterspannung" 32766 "Init" 32767 "Fehler" ;
VAL_ 795 ESP_Meldungen 0 "keine_Anzeige" 1 "Autohold_Hinweis_1" 2 "Stoerung_Autohold" 3 "Stoerung_Hillholder" 4 "Uebernehmen" 5 "Autohold_aus" 6 "Autohold_Hinweis_2" ;
VAL_ 795 ESP_Off_Lampe 0 "Lampe_aus" 1 "Lampe_ein" ;
VAL_ 795 ESP_QBit_Wegimp_VA 0 "gueltiger_Wert" 1 "Ersatz_Init_oder_Fehlerwert" ;
VAL_ 795 ESP_Textanzeigen_03 0 "kein_Text" 1 "ESP_Stoerung" 2 "ABS_Stoerung" 3 "ESP_ABS_Stoerung" 4 "Werkstatt_Bremse" 5 "ASR_Stoerung" 6 "ESP_switched_off" 7 "ASR_off" 8 "ESP_ASR_on" 10 "keine_Bremskraftverstaerkung" 11 "ASR_aktiviert" 12 "ABS_ASR_Stoerung" 15 "ESP_offroad" 17 "ESP_sport" 18 "ESP_Zwangsaktivierung" 19 "ESP_Taster_Info" 20 "TC_aktiv" 21 "reserviert_fuer_Verlwarn" 22 "TC_switched_off" 23 "Verlwarn_akt_Rollsicher_inakt" 24 "ESP_SuperSport" 25 "ESP_Offroad_nicht_verfuegbar" ;
VAL_ 795 ESP_Wegimp_Ueberlauf 0 "Reset_und_kein_Ueberlauf" 1 "mindestens_1x_Ueberlauf" ;
VAL_ 795 TC_Lampe 0 "Aus" 1 "Ein" ;
